// *************************************************************************** *
// *                                                                           *
// * Description:         CANDB File                                           *
// * Generated at:        2025-10-17 10:36                                     *
// * System:              SPA8410_Final2                                       *
// * Variant:             ConfigurationsSPA3d2                                 *
// * Network:             ASDM1CANFD                                           *
// *                                                                           *
// *************************************************************************** *

VERSION "ASDM1CANFD"

NS_ :

BS_ :

BU_ :  ASDM FLRB
VAL_TABLE_ ElevAlignment_States_MFR 2 "MBASC_ELEV_MISALIGNED" 1 "MBASC_ELEV_ALIGNED" 0 "MBASC_ELEV_CALIBRATING" ;

BO_ 289 RADARtoASDM: 2 FLRB
 SG_ EmblmHeatrReqReqDutyCycle : 8|8@1+ (0.5,0) [0|100] "%"  ASDM
 SG_ EmblmHeatrReqReqPWMFrq : 0|8@1+ (0.1,0) [0|25.5] ""  ASDM

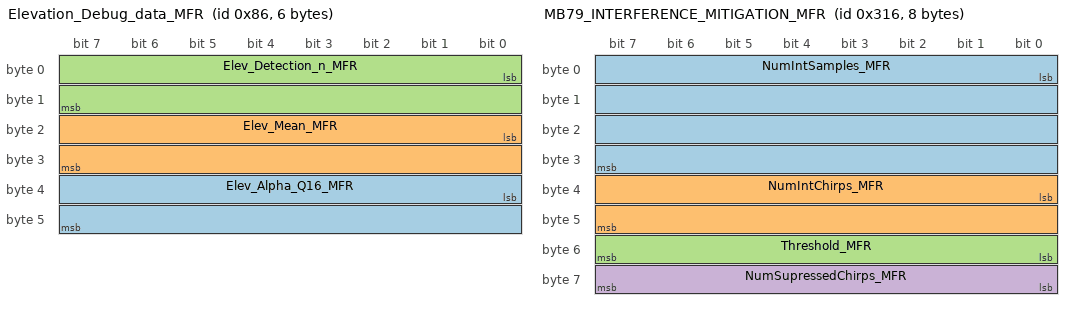
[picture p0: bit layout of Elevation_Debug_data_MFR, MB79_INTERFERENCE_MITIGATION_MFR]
BO_ 134 Elevation_Debug_data_MFR: 6 FLRB
 SG_ Elev_Alpha_Q16_MFR : 32|16@1+ (1,0) [0|65535] ""  ASDM
 SG_ Elev_Mean_MFR : 16|16@1- (1,0) [-32768|32767] ""  ASDM
 SG_ Elev_Detection_n_MFR : 0|16@1+ (1,0) [0|65535] ""  ASDM

BO_ 789 MB79_PARAMETERS_MFR: 24 FLRB
 SG_ Sensor_Serial_Number_MFR : 0|192@1+ (1,0) [0|16777215] ""  ASDM

BO_ 770 MB79_SYSTEM_STATUS_MFR: 8 FLRB
 SG_ Reserved_2bits_MFR : 29|2@1+ (1,0) [0|3] "" Vector__XXX
 SG_ Sensor_Error_Synchronization_Err : 25|1@1+ (1,0) [0|1] "" Vector__XXX
 SG_ Sensor_Error_Supply_Error_MFR : 24|1@1+ (1,0) [0|1] "" Vector__XXX
 SG_ Sensor_Error_Software_Incompatib : 27|1@1+ (1,0) [0|1] "" Vector__XXX
 SG_ Sensor_Error_Security_Breach_MFR : 28|1@1+ (1,0) [0|1] "" Vector__XXX
 SG_ Sensor_Error_Position_Error_MFR : 19|1@1+ (1,0) [0|1] "" Vector__XXX
 SG_ Sensor_Error_Misaligned_MFR : 20|1@1+ (1,0) [0|1] "" Vector__XXX
 SG_ Sensor_Error_Internal_Failure_MF : 17|1@1+ (1,0) [0|1] "" Vector__XXX
 SG_ Sensor_Error_Interference_MFR : 22|1@1+ (1,0) [0|1] "" Vector__XXX
 SG_ Sensor_Error_Initialization_MFR : 23|1@1+ (1,0) [0|1] "" Vector__XXX
 SG_ Sensor_Error_HW_Error_MFR : 26|1@1+ (1,0) [0|1] "" Vector__XXX
 SG_ Sensor_Error_Communication_MFR : 16|1@1+ (1,0) [0|1] "" Vector__XXX
 SG_ Sensor_Error_Calibration_Error_M : 18|1@1+ (1,0) [0|1] "" Vector__XXX
 SG_ Sensor_Error_Blocked_MFR : 21|1@1+ (1,0) [0|1] "" Vector__XXX
 SG_ Heater_Trigger_MFR : 31|1@1+ (1,0) [0|1] "" Vector__XXX
 SG_ Sensor_Operation_Mode_MFR : 12|4@1+ (1,0) [0|15] ""  ASDM
 SG_ Clock_SystemStatus_MFR : 8|4@1+ (1,0) [0|15] ""  ASDM
 SG_ CRC_SystemStatus_MFR : 0|8@1+ (1,0) [0|255] ""  ASDM

BO_ 790 MB79_INTERFERENCE_MITIGATION_MFR: 8 FLRB
 SG_ NumIntSamples_MFR : 0|32@1+ (1,0) [0|16777215] ""  ASDM
 SG_ NumIntChirps_MFR : 32|16@1+ (1,0) [0|255] ""  ASDM
 SG_ Threshold_MFR : 48|8@1+ (1,0) [0|65535] ""  ASDM
 SG_ NumSupressedChirps_MFR : 56|8@1+ (1,0) [0|255] ""  ASDM

BO_ 2047 AsdmToAllFuncAsdm1CanDiagReqFrame : 64 ASDM
 SG_ AsdmToAllFuncAsdm1CanDiagReqNpdu : 7|512@0+ (1,0) [0|0] "" FLRB

BO_ 1889 AsdmToFlrbAsdm1CanDiagReqFrame : 64 ASDM
 SG_ AsdmToFlrbAsdm1CanDiagReqNPdu : 7|512@0+ (1,0) [0|0] "" FLRB

BO_ 1633 FlrbToAsdmAsdm1CanDiagResFrame : 64 FLRB
 SG_ FlrbToAsdmAsdm1CanDiagRespNpdu : 7|512@0+ (1,0) [0|0] "" ASDM

BO_ 288 ASDMtoRADAR: 20 ASDM
 SG_ Vehicle_Type : 123|8@0+ (1,0) [0|255] ""  FLRB
 SG_ EmblmHeatrOutSts : 117|2@0+ (1,0) [0|0] ""  FLRB
 SG_ WshngCycActv : 115|8@0+ (1,0) [0|1] ""  FLRB
 SG_ isUsgModSts : 105|4@0+ (1,0) [0|15] ""  FLRB
 SG_ PwrLvlElecSubtyp : 3|4@0+ (1,0) [0|15] ""  FLRB
 SG_ PwrLvlElecMai : 7|4@0+ (1,0) [0|15] ""  FLRB
 SG_ AmbTRawVal : 47|11@0+ (0.1,-70) [-70|134.7] "degC"  FLRB
 SG_ AmbTRawQly : 52|2@0+ (1,0) [0|3] ""  FLRB
 SG_ BkpOfDstTrvld : 50|21@0+ (1,0) [0|2000000] "km"  FLRB
 SG_ CarTiGlb : 15|32@0+ (0.1,0) [0|429496729.5] "s"  FLRB
 SG_ CarModSts1 : 81|3@0+ (1,0) [0|7] "N/A"  FLRB
 SG_ DrvModReq : 85|4@0+ (1,0) [0|15] ""  FLRB
 SG_ VehBattUSysU : 77|8@0+ (0.1,0) [0|25] "Volt"  FLRB
 SG_ VehBattUSysUQf : 91|2@0+ (1,0) [0|3] ""  FLRB
 SG_ WipgInfoWipgSpdInfo : 94|3@0+ (1,0) [0|7] ""  FLRB
 SG_ WipgInfoWiprActv : 97|8@0+ (1,0) [0|255] ""  FLRB
 SG_ WipgInfoWiprInWipgAr : 89|8@0+ (1,0) [0|255] ""  FLRB

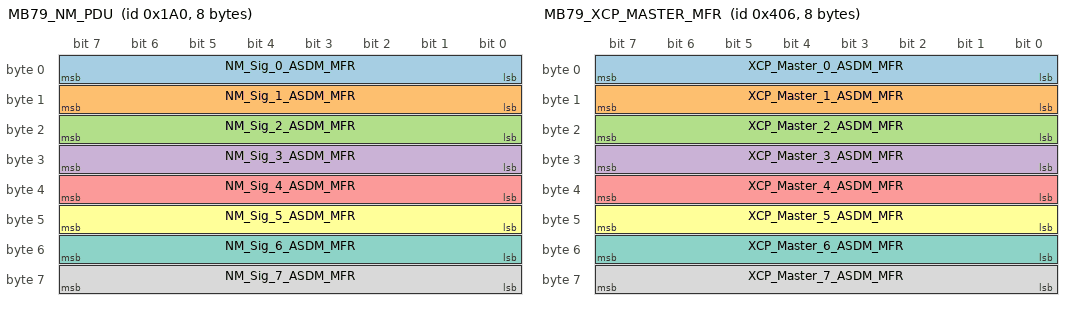
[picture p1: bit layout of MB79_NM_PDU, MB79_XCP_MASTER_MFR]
BO_ 416 MB79_NM_PDU: 8 ASDM
 SG_ NM_Sig_0_ASDM_MFR : 7|8@0+ (1,0) [0|255] "N/A"  FLRB
 SG_ NM_Sig_1_ASDM_MFR : 15|8@0+ (1,0) [0|255] "N/A"  FLRB
 SG_ NM_Sig_2_ASDM_MFR : 23|8@0+ (1,0) [0|255] "N/A"  FLRB
 SG_ NM_Sig_3_ASDM_MFR : 31|8@0+ (1,0) [0|255] "N/A"  FLRB
 SG_ NM_Sig_4_ASDM_MFR : 39|8@0+ (1,0) [0|255] "N/A"  FLRB
 SG_ NM_Sig_5_ASDM_MFR : 47|8@0+ (1,0) [0|255] "N/A"  FLRB
 SG_ NM_Sig_6_ASDM_MFR : 55|8@0+ (1,0) [0|255] "N/A"  FLRB
 SG_ NM_Sig_7_ASDM_MFR : 63|8@0+ (1,0) [0|255] "N/A"  FLRB

BO_ 1281 MB79_ECU_WAKE_UP_MFR: 64 FLRB
 SG_ ECU_Wake_UP_0_MFR : 7|8@0+ (1,0) [0|255] "N/A"  ASDM
 SG_ ECU_Wake_UP_1_MFR : 15|8@0+ (1,0) [0|255] "N/A"  ASDM
 SG_ ECU_Wake_UP_2_MFR : 23|8@0+ (1,0) [0|255] "N/A"  ASDM
 SG_ ECU_Wake_UP_3_MFR : 31|8@0+ (1,0) [0|255] "N/A"  ASDM
 SG_ ECU_Wake_UP_4_MFR : 39|8@0+ (1,0) [0|255] "N/A"  ASDM
 SG_ ECU_Wake_UP_5_MFR : 47|8@0+ (1,0) [0|255] "N/A"  ASDM
 SG_ ECU_Wake_UP_6_MFR : 55|8@0+ (1,0) [0|255] "N/A"  ASDM
 SG_ ECU_Wake_UP_7_MFR : 63|8@0+ (1,0) [0|255] "N/A"  ASDM

BO_ 1030 MB79_XCP_MASTER_MFR: 8 ASDM
 SG_ XCP_Master_0_ASDM_MFR : 7|8@0+ (1,0) [0|255] "N/A"  FLRB
 SG_ XCP_Master_1_ASDM_MFR : 15|8@0+ (1,0) [0|255] "N/A"  FLRB
 SG_ XCP_Master_2_ASDM_MFR : 23|8@0+ (1,0) [0|255] "N/A"  FLRB
 SG_ XCP_Master_3_ASDM_MFR : 31|8@0+ (1,0) [0|255] "N/A"  FLRB
 SG_ XCP_Master_4_ASDM_MFR : 39|8@0+ (1,0) [0|255] "N/A"  FLRB
 SG_ XCP_Master_5_ASDM_MFR : 47|8@0+ (1,0) [0|255] "N/A"  FLRB
 SG_ XCP_Master_6_ASDM_MFR : 55|8@0+ (1,0) [0|255] "N/A"  FLRB
 SG_ XCP_Master_7_ASDM_MFR : 63|8@0+ (1,0) [0|255] "N/A"  FLRB

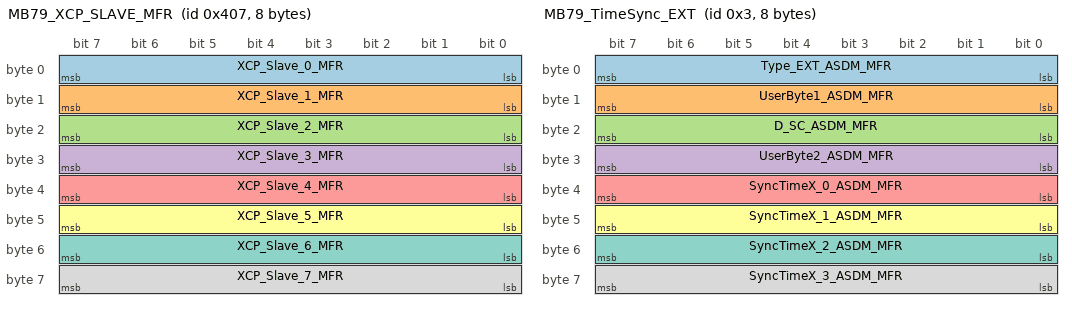
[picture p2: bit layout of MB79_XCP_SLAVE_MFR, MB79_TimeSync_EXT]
BO_ 1031 MB79_XCP_SLAVE_MFR: 8 FLRB
 SG_ XCP_Slave_0_MFR : 7|8@0+ (1,0) [0|255] "N/A"  ASDM
 SG_ XCP_Slave_1_MFR : 15|8@0+ (1,0) [0|255] "N/A"  ASDM
 SG_ XCP_Slave_2_MFR : 23|8@0+ (1,0) [0|255] "N/A"  ASDM
 SG_ XCP_Slave_3_MFR : 31|8@0+ (1,0) [0|255] "N/A"  ASDM
 SG_ XCP_Slave_4_MFR : 39|8@0+ (1,0) [0|255] "N/A"  ASDM
 SG_ XCP_Slave_5_MFR : 47|8@0+ (1,0) [0|255] "N/A"  ASDM
 SG_ XCP_Slave_6_MFR : 55|8@0+ (1,0) [0|255] "N/A"  ASDM
 SG_ XCP_Slave_7_MFR : 63|8@0+ (1,0) [0|255] "N/A"  ASDM

BO_ 3 MB79_TimeSync_EXT: 8 ASDM
 SG_ Type_EXT_ASDM_MFR : 7|8@0+ (1,0) [0|255] "N/A"  FLRB
 SG_ UserByte1_ASDM_MFR : 15|8@0+ (1,0) [0|255] "N/A"  FLRB
 SG_ D_SC_ASDM_MFR : 23|8@0+ (1,0) [0|255] "N/A"  FLRB
 SG_ UserByte2_ASDM_MFR : 31|8@0+ (1,0) [0|255] "N/A"  FLRB
 SG_ SyncTimeX_0_ASDM_MFR : 39|8@0+ (1,0) [0|255] "N/A"  FLRB
 SG_ SyncTimeX_1_ASDM_MFR : 47|8@0+ (1,0) [0|255] "N/A"  FLRB
 SG_ SyncTimeX_2_ASDM_MFR : 55|8@0+ (1,0) [0|255] "N/A"  FLRB
 SG_ SyncTimeX_3_ASDM_MFR : 63|8@0+ (1,0) [0|255] "N/A"  FLRB

BO_ 257 MB79_DETECTION_HEADER_MFR: 64 FLRB
 SG_ ElevAlignment_Status_MFR : 504|2@1+ (1,0) [0|3] "" Vector__XXX
 SG_ CRC_DetectionList_MFR : 0|32@1+ (1,0) [0|4294967295] "N/A"  ASDM
 SG_ CycleNumber_MFR : 32|32@1+ (1,0) [0|4294967295] "cycle"  ASDM
 SG_ TimeStamp_MFR : 64|32@1+ (1,0) [0|4294967295] "us"  ASDM
 SG_ HostVelEst_MFR : 96|16@1- (1,0) [-2000|14000] "cm/s"  ASDM
 SG_ HostYawEst_MFR : 112|16@1- (0.000977,0) [-2|2] "rad/s"  ASDM
 SG_ HostAccelLatEst_MFR : 128|16@1- (1,0) [-2000|2000] "cm/s.s"  ASDM
 SG_ HostAccelLongEst_MFR : 144|16@1- (1,0) [-2000|2000] "cm/s.s"  ASDM
 SG_ Sensor_Elev_Angle_corr_MFR : 160|16@1- (0.1,0) [-180|655.35] "degree"  ASDM
 SG_ Alignment_update_cycle_MFR : 176|8@1+ (1,0) [0|255] "N/A"  ASDM
 SG_ Velocity_Correction_MFR : 184|16@1- (0.0196,0) [-5|5] "%"  ASDM
 SG_ Sensor_Pos_X_MFR : 200|16@1- (0.001,0) [-20|65.535] "m"  ASDM
 SG_ Sensor_Pos_Y_MFR : 216|16@1- (0.001,0) [-20|65.535] "m"  ASDM
 SG_ Orientation_Angle_MFR : 232|16@1- (0.1,0) [-180|180] "degree"  ASDM
 SG_ Calibrated_Angle_Az_MFR : 248|16@1- (0.1,0) [-180|180] "degree"  ASDM
 SG_ Sensor_Pos_Z_MFR : 264|8@1+ (0.01,0) [0|2.55] "m"  ASDM
 SG_ Sensor_FoV_Max_MFR : 272|8@1+ (1,0) [0|255] "degree"  ASDM
 SG_ Sensor_FoV_Min_MFR : 280|8@1+ (1,0) [0|255] "degree"  ASDM
 SG_ BW100KHz1_MFR : 288|16@1+ (100,0) [0|6553500] "N/A"  ASDM
 SG_ UnambiguousVelMeas1_MFR : 304|8@1+ (1,0) [0|255] "N/A"  ASDM
 SG_ Radar_Sensor_type_MFR : 312|8@1+ (1,0) [0|255] "N/A"  ASDM
 SG_ Sensor_Position_ID_MFR : 320|4@1+ (1,0) [0|15] "N/A"  ASDM
 SG_ DetectionListVersion_MFR : 324|4@1+ (1,0) [0|15] "N/A"  ASDM
 SG_ Detection_Header_Version_MFR : 328|4@1+ (1,0) [0|15] "N/A"  ASDM
 SG_ numInfrastructureDetected_MFR : 332|10@1+ (1,0) [0|1023] "detection"  ASDM
 SG_ numNonInfraDetected_MFR : 342|10@1+ (1,0) [0|1023] "detection"  ASDM
 SG_ numFreespaceDetections_MFR : 352|2@1+ (1,0) [0|3] "detection"  ASDM
 SG_ interferenceDetected_MFR : 354|2@1+ (1,0) [0|3] "N/A"  ASDM
 SG_ Blockage_Confidence_MFR : 356|8@1+ (0.5,0) [0|200] "%"  ASDM
 SG_ Blockage_Level_MFR : 364|8@1+ (0.5,0) [0|200] "%"  ASDM
 SG_ Blockage_Status_MFR : 372|3@1+ (1,0) [0|7] "N/A"  ASDM
 SG_ max_instrumented_range_2m_MFR : 375|8@1+ (2,0) [0|510] "m"  ASDM
 SG_ Sensor_Operation_Mode_MFR : 383|4@1+ (1,0) [0|15] "Mode"  ASDM
 SG_ AutoAlignment_Status_MFR : 387|4@1+ (1,0) [0|15] "N/A"  ASDM
 SG_ Testing_Mode_MFR : 391|4@1+ (1,0) [0|15] "N/A"  ASDM
 SG_ NearZoneDetectionsCount_MFR : 395|10@1+ (1,0) [0|512] "detection" Vector__XXX
 SG_ HorizonZoneDetectionsCount_MFR : 405|10@1+ (1,0) [0|512] "detection" Vector__XXX
 SG_ Reserved_1byte_MFR : 415|8@1- (1,0) [0|0] "" Vector__XXX
 SG_ Detection_Data_Mode_MFR : 423|1@1+ (1,0) [0|1] "" Vector__XXX
 SG_ Reserved_3bits_MFR : 424|3@1- (1,0) [0|0] "" Vector__XXX
 SG_ AR_Counter_DetectionList_MFR : 427|32@1+ (1,0) [0|4294967295] "N/A"  ASDM
 SG_ MAC_DetectionList_MFR : 459|24@1+ (1,0) [0|16777215] "N/A"  ASDM
 SG_ Sensor_Topology_MFR : 483|1@1+ (1,0) [0|1] "N/A"  ASDM
 SG_ AASC_Calibration_flag_MFR : 484|1@1+ (1,0) [0|1] "N/A"  ASDM
 SG_ selected_chirp_config_MFR : 485|3@1+ (1,0) [0|7] "N/A"  ASDM
 SG_ FC1MHz1_MFR : 488|16@1+ (10,0) [0|65535] "MHz"  ASDM

BO_ 304 MB79_DETECTIONS_0_MFR: 64 FLRB
 SG_ zipy_serialized_data_0_MFR : 0|32@1- (0.1,0) [-102.4|429496729.5] "degree"  ASDM
 SG_ zipy_serialized_data_1_MFR : 32|32@1- (0.1,0) [-102.4|429496729.5] "degree"  ASDM
 SG_ zipy_serialized_data_2_MFR : 64|32@1- (0.1,0) [-102.4|429496729.5] "degree"  ASDM
 SG_ zipy_serialized_data_3_MFR : 96|32@1- (0.1,0) [-102.4|429496729.5] "degree"  ASDM
 SG_ zipy_serialized_data_4_MFR : 128|32@1- (0.1,0) [-102.4|429496729.5] "degree"  ASDM
 SG_ zipy_serialized_data_5_MFR : 160|32@1- (0.1,0) [-102.4|429496729.5] "degree"  ASDM
 SG_ zipy_serialized_data_6_MFR : 192|32@1- (0.1,0) [-102.4|429496729.5] "degree"  ASDM
 SG_ zipy_serialized_data_7_MFR : 224|32@1- (0.1,0) [-102.4|429496729.5] "degree"  ASDM
 SG_ zipy_serialized_data_8_MFR : 256|32@1- (0.1,0) [-102.4|429496729.5] "degree"  ASDM
 SG_ zipy_serialized_data_9_MFR : 288|32@1- (0.1,0) [-102.4|429496729.5] "degree"  ASDM
 SG_ zipy_serialized_data_10_MFR : 320|32@1- (0.1,0) [-102.4|429496729.5] "degree"  ASDM
 SG_ zipy_serialized_data_11_MFR : 352|32@1- (0.1,0) [-102.4|429496729.5] "degree"  ASDM
 SG_ zipy_serialized_data_12_MFR : 384|32@1- (0.1,0) [-102.4|429496729.5] "degree"  ASDM
 SG_ zipy_serialized_data_13_MFR : 416|32@1- (0.1,0) [-102.4|429496729.5] "degree"  ASDM
 SG_ zipy_serialized_data_14_MFR : 448|32@1- (0.1,0) [-102.4|429496729.5] "degree"  ASDM
 SG_ zipy_serialized_data_15_MFR : 480|32@1- (0.1,0) [-102.4|429496729.5] "degree"  ASDM

BO_ 305 MB79_DETECTIONS_1_MFR: 64 FLRB
 SG_ zipy_serialized_data_16_MFR : 0|32@1- (0.1,0) [-102.4|429496729.5] "degree"  ASDM
 SG_ zipy_serialized_data_17_MFR : 32|32@1- (0.1,0) [-102.4|429496729.5] "degree"  ASDM
 SG_ zipy_serialized_data_18_MFR : 64|32@1- (0.1,0) [-102.4|429496729.5] "degree"  ASDM
 SG_ zipy_serialized_data_19_MFR : 96|32@1- (0.1,0) [-102.4|429496729.5] "degree"  ASDM
 SG_ zipy_serialized_data_20_MFR : 128|32@1- (0.1,0) [-102.4|429496729.5] "degree"  ASDM
 SG_ zipy_serialized_data_21_MFR : 160|32@1- (0.1,0) [-102.4|429496729.5] "degree"  ASDM
 SG_ zipy_serialized_data_22_MFR : 192|32@1- (0.1,0) [-102.4|429496729.5] "degree"  ASDM
 SG_ zipy_serialized_data_23_MFR : 224|32@1- (0.1,0) [-102.4|429496729.5] "degree"  ASDM
 SG_ zipy_serialized_data_24_MFR : 256|32@1- (0.1,0) [-102.4|429496729.5] "degree"  ASDM
 SG_ zipy_serialized_data_25_MFR : 288|32@1- (0.1,0) [-102.4|429496729.5] "degree"  ASDM
 SG_ zipy_serialized_data_26_MFR : 320|32@1- (0.1,0) [-102.4|429496729.5] "degree"  ASDM
 SG_ zipy_serialized_data_27_MFR : 352|32@1- (0.1,0) [-102.4|429496729.5] "degree"  ASDM
 SG_ zipy_serialized_data_28_MFR : 384|32@1- (0.1,0) [-102.4|429496729.5] "degree"  ASDM
 SG_ zipy_serialized_data_29_MFR : 416|32@1- (0.1,0) [-102.4|429496729.5] "degree"  ASDM
 SG_ zipy_serialized_data_30_MFR : 448|32@1- (0.1,0) [-102.4|429496729.5] "degree"  ASDM
 SG_ zipy_serialized_data_31_MFR : 480|32@1- (0.1,0) [-102.4|429496729.5] "degree"  ASDM

BO_ 306 MB79_DETECTIONS_2_MFR: 64 FLRB
 SG_ zipy_serialized_data_32_MFR : 0|32@1- (0.1,0) [-102.4|429496729.5] "degree"  ASDM
 SG_ zipy_serialized_data_33_MFR : 32|32@1- (0.1,0) [-102.4|429496729.5] "degree"  ASDM
 SG_ zipy_serialized_data_34_MFR : 64|32@1- (0.1,0) [-102.4|429496729.5] "degree"  ASDM
 SG_ zipy_serialized_data_35_MFR : 96|32@1- (0.1,0) [-102.4|429496729.5] "degree"  ASDM
 SG_ zipy_serialized_data_36_MFR : 128|32@1- (0.1,0) [-102.4|429496729.5] "degree"  ASDM
 SG_ zipy_serialized_data_37_MFR : 160|32@1- (0.1,0) [-102.4|429496729.5] "degree"  ASDM
 SG_ zipy_serialized_data_38_MFR : 192|32@1- (0.1,0) [-102.4|429496729.5] "degree"  ASDM
 SG_ zipy_serialized_data_39_MFR : 224|32@1- (0.1,0) [-102.4|429496729.5] "degree"  ASDM
 SG_ zipy_serialized_data_40_MFR : 256|32@1- (0.1,0) [-102.4|429496729.5] "degree"  ASDM
 SG_ zipy_serialized_data_41_MFR : 288|32@1- (0.1,0) [-102.4|429496729.5] "degree"  ASDM
 SG_ zipy_serialized_data_42_MFR : 320|32@1- (0.1,0) [-102.4|429496729.5] "degree"  ASDM
 SG_ zipy_serialized_data_43_MFR : 352|32@1- (0.1,0) [-102.4|429496729.5] "degree"  ASDM
 SG_ zipy_serialized_data_44_MFR : 384|32@1- (0.1,0) [-102.4|429496729.5] "degree"  ASDM
 SG_ zipy_serialized_data_45_MFR : 416|32@1- (0.1,0) [-102.4|429496729.5] "degree"  ASDM
 SG_ zipy_serialized_data_46_MFR : 448|32@1- (0.1,0) [-102.4|429496729.5] "degree"  ASDM
 SG_ zipy_serialized_data_47_MFR : 480|32@1- (0.1,0) [-102.4|429496729.5] "degree"  ASDM

BO_ 307 MB79_DETECTIONS_3_MFR: 64 FLRB
 SG_ zipy_serialized_data_48_MFR : 0|32@1- (0.1,0) [-102.4|429496729.5] "degree"  ASDM
 SG_ zipy_serialized_data_49_MFR : 32|32@1- (0.1,0) [-102.4|429496729.5] "degree"  ASDM
 SG_ zipy_serialized_data_50_MFR : 64|32@1- (0.1,0) [-102.4|429496729.5] "degree"  ASDM
 SG_ zipy_serialized_data_51_MFR : 96|32@1- (0.1,0) [-102.4|429496729.5] "degree"  ASDM
 SG_ zipy_serialized_data_52_MFR : 128|32@1- (0.1,0) [-102.4|429496729.5] "degree"  ASDM
 SG_ zipy_serialized_data_53_MFR : 160|32@1- (0.1,0) [-102.4|429496729.5] "degree"  ASDM
 SG_ zipy_serialized_data_54_MFR : 192|32@1- (0.1,0) [-102.4|429496729.5] "degree"  ASDM
 SG_ zipy_serialized_data_55_MFR : 224|32@1- (0.1,0) [-102.4|429496729.5] "degree"  ASDM
 SG_ zipy_serialized_data_56_MFR : 256|32@1- (0.1,0) [-102.4|429496729.5] "degree"  ASDM
 SG_ zipy_serialized_data_57_MFR : 288|32@1- (0.1,0) [-102.4|429496729.5] "degree"  ASDM
 SG_ zipy_serialized_data_58_MFR : 320|32@1- (0.1,0) [-102.4|429496729.5] "degree"  ASDM
 SG_ zipy_serialized_data_59_MFR : 352|32@1- (0.1,0) [-102.4|429496729.5] "degree"  ASDM
 SG_ zipy_serialized_data_60_MFR : 384|32@1- (0.1,0) [-102.4|429496729.5] "degree"  ASDM
 SG_ zipy_serialized_data_61_MFR : 416|32@1- (0.1,0) [-102.4|429496729.5] "degree"  ASDM
 SG_ zipy_serialized_data_62_MFR : 448|32@1- (0.1,0) [-102.4|429496729.5] "degree"  ASDM
 SG_ zipy_serialized_data_63_MFR : 480|32@1- (0.1,0) [-102.4|429496729.5] "degree"  ASDM

BO_ 308 MB79_DETECTIONS_4_MFR: 64 FLRB
 SG_ zipy_serialized_data_64_MFR : 0|32@1- (0.1,0) [-102.4|429496729.5] "degree"  ASDM
 SG_ zipy_serialized_data_65_MFR : 32|32@1- (0.1,0) [-102.4|429496729.5] "degree"  ASDM
 SG_ zipy_serialized_data_66_MFR : 64|32@1- (0.1,0) [-102.4|429496729.5] "degree"  ASDM
 SG_ zipy_serialized_data_67_MFR : 96|32@1- (0.1,0) [-102.4|429496729.5] "degree"  ASDM
 SG_ zipy_serialized_data_68_MFR : 128|32@1- (0.1,0) [-102.4|429496729.5] "degree"  ASDM
 SG_ zipy_serialized_data_69_MFR : 160|32@1- (0.1,0) [-102.4|429496729.5] "degree"  ASDM
 SG_ zipy_serialized_data_70_MFR : 192|32@1- (0.1,0) [-102.4|429496729.5] "degree"  ASDM
 SG_ zipy_serialized_data_71_MFR : 224|32@1- (0.1,0) [-102.4|429496729.5] "degree"  ASDM
 SG_ zipy_serialized_data_72_MFR : 256|32@1- (0.1,0) [-102.4|429496729.5] "degree"  ASDM
 SG_ zipy_serialized_data_73_MFR : 288|32@1- (0.1,0) [-102.4|429496729.5] "degree"  ASDM
 SG_ zipy_serialized_data_74_MFR : 320|32@1- (0.1,0) [-102.4|429496729.5] "degree"  ASDM
 SG_ zipy_serialized_data_75_MFR : 352|32@1- (0.1,0) [-102.4|429496729.5] "degree"  ASDM
 SG_ zipy_serialized_data_76_MFR : 384|32@1- (0.1,0) [-102.4|429496729.5] "degree"  ASDM
 SG_ zipy_serialized_data_77_MFR : 416|32@1- (0.1,0) [-102.4|429496729.5] "degree"  ASDM
 SG_ zipy_serialized_data_78_MFR : 448|32@1- (0.1,0) [-102.4|429496729.5] "degree"  ASDM
 SG_ zipy_serialized_data_79_MFR : 480|32@1- (0.1,0) [-102.4|429496729.5] "degree"  ASDM

BO_ 309 MB79_DETECTIONS_5_MFR: 64 FLRB
 SG_ zipy_serialized_data_80_MFR : 0|32@1- (0.1,0) [-102.4|429496729.5] "degree"  ASDM
 SG_ zipy_serialized_data_81_MFR : 32|32@1- (0.1,0) [-102.4|429496729.5] "degree"  ASDM
 SG_ zipy_serialized_data_82_MFR : 64|32@1- (0.1,0) [-102.4|429496729.5] "degree"  ASDM
 SG_ zipy_serialized_data_83_MFR : 96|32@1- (0.1,0) [-102.4|429496729.5] "degree"  ASDM
 SG_ zipy_serialized_data_84_MFR : 128|32@1- (0.1,0) [-102.4|429496729.5] "degree"  ASDM
 SG_ zipy_serialized_data_85_MFR : 160|32@1- (0.1,0) [-102.4|429496729.5] "degree"  ASDM
 SG_ zipy_serialized_data_86_MFR : 192|32@1- (0.1,0) [-102.4|429496729.5] "degree"  ASDM
 SG_ zipy_serialized_data_87_MFR : 224|32@1- (0.1,0) [-102.4|429496729.5] "degree"  ASDM
 SG_ zipy_serialized_data_88_MFR : 256|32@1- (0.1,0) [-102.4|429496729.5] "degree"  ASDM
 SG_ zipy_serialized_data_89_MFR : 288|32@1- (0.1,0) [-102.4|429496729.5] "degree"  ASDM
 SG_ zipy_serialized_data_90_MFR : 320|32@1- (0.1,0) [-102.4|429496729.5] "degree"  ASDM
 SG_ zipy_serialized_data_91_MFR : 352|32@1- (0.1,0) [-102.4|429496729.5] "degree"  ASDM
 SG_ zipy_serialized_data_92_MFR : 384|32@1- (0.1,0) [-102.4|429496729.5] "degree"  ASDM
 SG_ zipy_serialized_data_93_MFR : 416|32@1- (0.1,0) [-102.4|429496729.5] "degree"  ASDM
 SG_ zipy_serialized_data_94_MFR : 448|32@1- (0.1,0) [-102.4|429496729.5] "degree"  ASDM
 SG_ zipy_serialized_data_95_MFR : 480|32@1- (0.1,0) [-102.4|429496729.5] "degree"  ASDM

BO_ 310 MB79_DETECTIONS_6_MFR: 64 FLRB
 SG_ zipy_serialized_data_96_MFR : 0|32@1- (0.1,0) [-102.4|429496729.5] "degree"  ASDM
 SG_ zipy_serialized_data_97_MFR : 32|32@1- (0.1,0) [-102.4|429496729.5] "degree"  ASDM
 SG_ zipy_serialized_data_98_MFR : 64|32@1- (0.1,0) [-102.4|429496729.5] "degree"  ASDM
 SG_ zipy_serialized_data_99_MFR : 96|32@1- (0.1,0) [-102.4|429496729.5] "degree"  ASDM
 SG_ zipy_serialized_data_100_MFR : 128|32@1- (0.1,0) [-102.4|429496729.5] "degree"  ASDM
 SG_ zipy_serialized_data_101_MFR : 160|32@1- (0.1,0) [-102.4|429496729.5] "degree"  ASDM
 SG_ zipy_serialized_data_102_MFR : 192|32@1- (0.1,0) [-102.4|429496729.5] "degree"  ASDM
 SG_ zipy_serialized_data_103_MFR : 224|32@1- (0.1,0) [-102.4|429496729.5] "degree"  ASDM
 SG_ zipy_serialized_data_104_MFR : 256|32@1- (0.1,0) [-102.4|429496729.5] "degree"  ASDM
 SG_ zipy_serialized_data_105_MFR : 288|32@1- (0.1,0) [-102.4|429496729.5] "degree"  ASDM
 SG_ zipy_serialized_data_106_MFR : 320|32@1- (0.1,0) [-102.4|429496729.5] "degree"  ASDM
 SG_ zipy_serialized_data_107_MFR : 352|32@1- (0.1,0) [-102.4|429496729.5] "degree"  ASDM
 SG_ zipy_serialized_data_108_MFR : 384|32@1- (0.1,0) [-102.4|429496729.5] "degree"  ASDM
 SG_ zipy_serialized_data_109_MFR : 416|32@1- (0.1,0) [-102.4|429496729.5] "degree"  ASDM
 SG_ zipy_serialized_data_110_MFR : 448|32@1- (0.1,0) [-102.4|429496729.5] "degree"  ASDM
 SG_ zipy_serialized_data_111_MFR : 480|32@1- (0.1,0) [-102.4|429496729.5] "degree"  ASDM

BO_ 311 MB79_DETECTIONS_7_MFR: 64 FLRB
 SG_ zipy_serialized_data_112_MFR : 0|32@1- (0.1,0) [-102.4|429496729.5] "degree"  ASDM
 SG_ zipy_serialized_data_113_MFR : 32|32@1- (0.1,0) [-102.4|429496729.5] "degree"  ASDM
 SG_ zipy_serialized_data_114_MFR : 64|32@1- (0.1,0) [-102.4|429496729.5] "degree"  ASDM
 SG_ zipy_serialized_data_115_MFR : 96|32@1- (0.1,0) [-102.4|429496729.5] "degree"  ASDM
 SG_ zipy_serialized_data_116_MFR : 128|32@1- (0.1,0) [-102.4|429496729.5] "degree"  ASDM
 SG_ zipy_serialized_data_117_MFR : 160|32@1- (0.1,0) [-102.4|429496729.5] "degree"  ASDM
 SG_ zipy_serialized_data_118_MFR : 192|32@1- (0.1,0) [-102.4|429496729.5] "degree"  ASDM
 SG_ zipy_serialized_data_119_MFR : 224|32@1- (0.1,0) [-102.4|429496729.5] "degree"  ASDM
 SG_ zipy_serialized_data_120_MFR : 256|32@1- (0.1,0) [-102.4|429496729.5] "degree"  ASDM
 SG_ zipy_serialized_data_121_MFR : 288|32@1- (0.1,0) [-102.4|429496729.5] "degree"  ASDM
 SG_ zipy_serialized_data_122_MFR : 320|32@1- (0.1,0) [-102.4|429496729.5] "degree"  ASDM
 SG_ zipy_serialized_data_123_MFR : 352|32@1- (0.1,0) [-102.4|429496729.5] "degree"  ASDM
 SG_ zipy_serialized_data_124_MFR : 384|32@1- (0.1,0) [-102.4|429496729.5] "degree"  ASDM
 SG_ zipy_serialized_data_125_MFR : 416|32@1- (0.1,0) [-102.4|429496729.5] "degree"  ASDM
 SG_ zipy_serialized_data_126_MFR : 448|32@1- (0.1,0) [-102.4|429496729.5] "degree"  ASDM
 SG_ zipy_serialized_data_127_MFR : 480|32@1- (0.1,0) [-102.4|429496729.5] "degree"  ASDM

BO_ 312 MB79_DETECTIONS_8_MFR: 64 FLRB
 SG_ zipy_serialized_data_128_MFR : 0|32@1- (0.1,0) [-102.4|429496729.5] "degree"  ASDM
 SG_ zipy_serialized_data_129_MFR : 32|32@1- (0.1,0) [-102.4|429496729.5] "degree"  ASDM
 SG_ zipy_serialized_data_130_MFR : 64|32@1- (0.1,0) [-102.4|429496729.5] "degree"  ASDM
 SG_ zipy_serialized_data_131_MFR : 96|32@1- (0.1,0) [-102.4|429496729.5] "degree"  ASDM
 SG_ zipy_serialized_data_132_MFR : 128|32@1- (0.1,0) [-102.4|429496729.5] "degree"  ASDM
 SG_ zipy_serialized_data_133_MFR : 160|32@1- (0.1,0) [-102.4|429496729.5] "degree"  ASDM
 SG_ zipy_serialized_data_134_MFR : 192|32@1- (0.1,0) [-102.4|429496729.5] "degree"  ASDM
 SG_ zipy_serialized_data_135_MFR : 224|32@1- (0.1,0) [-102.4|429496729.5] "degree"  ASDM
 SG_ zipy_serialized_data_136_MFR : 256|32@1- (0.1,0) [-102.4|429496729.5] "degree"  ASDM
 SG_ zipy_serialized_data_137_MFR : 288|32@1- (0.1,0) [-102.4|429496729.5] "degree"  ASDM
 SG_ zipy_serialized_data_138_MFR : 320|32@1- (0.1,0) [-102.4|429496729.5] "degree"  ASDM
 SG_ zipy_serialized_data_139_MFR : 352|32@1- (0.1,0) [-102.4|429496729.5] "degree"  ASDM
 SG_ zipy_serialized_data_140_MFR : 384|32@1- (0.1,0) [-102.4|429496729.5] "degree"  ASDM
 SG_ zipy_serialized_data_141_MFR : 416|32@1- (0.1,0) [-102.4|429496729.5] "degree"  ASDM
 SG_ zipy_serialized_data_142_MFR : 448|32@1- (0.1,0) [-102.4|429496729.5] "degree"  ASDM
 SG_ zipy_serialized_data_143_MFR : 480|32@1- (0.1,0) [-102.4|429496729.5] "degree"  ASDM

BO_ 313 MB79_DETECTIONS_9_MFR: 64 FLRB
 SG_ zipy_serialized_data_144_MFR : 0|32@1- (0.1,0) [-102.4|429496729.5] "degree"  ASDM
 SG_ zipy_serialized_data_145_MFR : 32|32@1- (0.1,0) [-102.4|429496729.5] "degree"  ASDM
 SG_ zipy_serialized_data_146_MFR : 64|32@1- (0.1,0) [-102.4|429496729.5] "degree"  ASDM
 SG_ zipy_serialized_data_147_MFR : 96|32@1- (0.1,0) [-102.4|429496729.5] "degree"  ASDM
 SG_ zipy_serialized_data_148_MFR : 128|32@1- (0.1,0) [-102.4|429496729.5] "degree"  ASDM
 SG_ zipy_serialized_data_149_MFR : 160|32@1- (0.1,0) [-102.4|429496729.5] "degree"  ASDM
 SG_ zipy_serialized_data_150_MFR : 192|32@1- (0.1,0) [-102.4|429496729.5] "degree"  ASDM
 SG_ zipy_serialized_data_151_MFR : 224|32@1- (0.1,0) [-102.4|429496729.5] "degree"  ASDM
 SG_ zipy_serialized_data_152_MFR : 256|32@1- (0.1,0) [-102.4|429496729.5] "degree"  ASDM
 SG_ zipy_serialized_data_153_MFR : 288|32@1- (0.1,0) [-102.4|429496729.5] "degree"  ASDM
 SG_ zipy_serialized_data_154_MFR : 320|32@1- (0.1,0) [-102.4|429496729.5] "degree"  ASDM
 SG_ zipy_serialized_data_155_MFR : 352|32@1- (0.1,0) [-102.4|429496729.5] "degree"  ASDM
 SG_ zipy_serialized_data_156_MFR : 384|32@1- (0.1,0) [-102.4|429496729.5] "degree"  ASDM
 SG_ zipy_serialized_data_157_MFR : 416|32@1- (0.1,0) [-102.4|429496729.5] "degree"  ASDM
 SG_ zipy_serialized_data_158_MFR : 448|32@1- (0.1,0) [-102.4|429496729.5] "degree"  ASDM
 SG_ zipy_serialized_data_159_MFR : 480|32@1- (0.1,0) [-102.4|429496729.5] "degree"  ASDM

BO_ 314 MB79_DETECTIONS_10_MFR: 64 FLRB
 SG_ zipy_serialized_data_160_MFR : 0|32@1- (0.1,0) [-102.4|429496729.5] "degree"  ASDM
 SG_ zipy_serialized_data_161_MFR : 32|32@1- (0.1,0) [-102.4|429496729.5] "degree"  ASDM
 SG_ zipy_serialized_data_162_MFR : 64|32@1- (0.1,0) [-102.4|429496729.5] "degree"  ASDM
 SG_ zipy_serialized_data_163_MFR : 96|32@1- (0.1,0) [-102.4|429496729.5] "degree"  ASDM
 SG_ zipy_serialized_data_164_MFR : 128|32@1- (0.1,0) [-102.4|429496729.5] "degree"  ASDM
 SG_ zipy_serialized_data_165_MFR : 160|32@1- (0.1,0) [-102.4|429496729.5] "degree"  ASDM
 SG_ zipy_serialized_data_166_MFR : 192|32@1- (0.1,0) [-102.4|429496729.5] "degree"  ASDM
 SG_ zipy_serialized_data_167_MFR : 224|32@1- (0.1,0) [-102.4|429496729.5] "degree"  ASDM
 SG_ zipy_serialized_data_168_MFR : 256|32@1- (0.1,0) [-102.4|429496729.5] "degree"  ASDM
 SG_ zipy_serialized_data_169_MFR : 288|32@1- (0.1,0) [-102.4|429496729.5] "degree"  ASDM
 SG_ zipy_serialized_data_170_MFR : 320|32@1- (0.1,0) [-102.4|429496729.5] "degree"  ASDM
 SG_ zipy_serialized_data_171_MFR : 352|32@1- (0.1,0) [-102.4|429496729.5] "degree"  ASDM
 SG_ zipy_serialized_data_172_MFR : 384|32@1- (0.1,0) [-102.4|429496729.5] "degree"  ASDM
 SG_ zipy_serialized_data_173_MFR : 416|32@1- (0.1,0) [-102.4|429496729.5] "degree"  ASDM
 SG_ zipy_serialized_data_174_MFR : 448|32@1- (0.1,0) [-102.4|429496729.5] "degree"  ASDM
 SG_ zipy_serialized_data_175_MFR : 480|32@1- (0.1,0) [-102.4|429496729.5] "degree"  ASDM

BO_ 315 MB79_DETECTIONS_11_MFR: 64 FLRB
 SG_ zipy_serialized_data_176_MFR : 0|32@1- (0.1,0) [-102.4|429496729.5] "degree"  ASDM
 SG_ zipy_serialized_data_177_MFR : 32|32@1- (0.1,0) [-102.4|429496729.5] "degree"  ASDM
 SG_ zipy_serialized_data_178_MFR : 64|32@1- (0.1,0) [-102.4|429496729.5] "degree"  ASDM
 SG_ zipy_serialized_data_179_MFR : 96|32@1- (0.1,0) [-102.4|429496729.5] "degree"  ASDM
 SG_ zipy_serialized_data_180_MFR : 128|32@1- (0.1,0) [-102.4|429496729.5] "degree"  ASDM
 SG_ zipy_serialized_data_181_MFR : 160|32@1- (0.1,0) [-102.4|429496729.5] "degree"  ASDM
 SG_ zipy_serialized_data_182_MFR : 192|32@1- (0.1,0) [-102.4|429496729.5] "degree"  ASDM
 SG_ zipy_serialized_data_183_MFR : 224|32@1- (0.1,0) [-102.4|429496729.5] "degree"  ASDM
 SG_ zipy_serialized_data_184_MFR : 256|32@1- (0.1,0) [-102.4|429496729.5] "degree"  ASDM
 SG_ zipy_serialized_data_185_MFR : 288|32@1- (0.1,0) [-102.4|429496729.5] "degree"  ASDM
 SG_ zipy_serialized_data_186_MFR : 320|32@1- (0.1,0) [-102.4|429496729.5] "degree"  ASDM
 SG_ zipy_serialized_data_187_MFR : 352|32@1- (0.1,0) [-102.4|429496729.5] "degree"  ASDM
 SG_ zipy_serialized_data_188_MFR : 384|32@1- (0.1,0) [-102.4|429496729.5] "degree"  ASDM
 SG_ zipy_serialized_data_189_MFR : 416|32@1- (0.1,0) [-102.4|429496729.5] "degree"  ASDM
 SG_ zipy_serialized_data_190_MFR : 448|32@1- (0.1,0) [-102.4|429496729.5] "degree"  ASDM
 SG_ zipy_serialized_data_191_MFR : 480|32@1- (0.1,0) [-102.4|429496729.5] "degree"  ASDM

BO_ 316 MB79_DETECTIONS_12_MFR: 64 FLRB
 SG_ zipy_serialized_data_192_MFR : 0|32@1- (0.1,0) [-102.4|429496729.5] "degree"  ASDM
 SG_ zipy_serialized_data_193_MFR : 32|32@1- (0.1,0) [-102.4|429496729.5] "degree"  ASDM
 SG_ zipy_serialized_data_194_MFR : 64|32@1- (0.1,0) [-102.4|429496729.5] "degree"  ASDM
 SG_ zipy_serialized_data_195_MFR : 96|32@1- (0.1,0) [-102.4|429496729.5] "degree"  ASDM
 SG_ zipy_serialized_data_196_MFR : 128|32@1- (0.1,0) [-102.4|429496729.5] "degree"  ASDM
 SG_ zipy_serialized_data_197_MFR : 160|32@1- (0.1,0) [-102.4|429496729.5] "degree"  ASDM
 SG_ zipy_serialized_data_198_MFR : 192|32@1- (0.1,0) [-102.4|429496729.5] "degree"  ASDM
 SG_ zipy_serialized_data_199_MFR : 224|32@1- (0.1,0) [-102.4|429496729.5] "degree"  ASDM
 SG_ zipy_serialized_data_200_MFR : 256|32@1- (0.1,0) [-102.4|429496729.5] "degree"  ASDM
 SG_ zipy_serialized_data_201_MFR : 288|32@1- (0.1,0) [-102.4|429496729.5] "degree"  ASDM
 SG_ zipy_serialized_data_202_MFR : 320|32@1- (0.1,0) [-102.4|429496729.5] "degree"  ASDM
 SG_ zipy_serialized_data_203_MFR : 352|32@1- (0.1,0) [-102.4|429496729.5] "degree"  ASDM
 SG_ zipy_serialized_data_204_MFR : 384|32@1- (0.1,0) [-102.4|429496729.5] "degree"  ASDM
 SG_ zipy_serialized_data_205_MFR : 416|32@1- (0.1,0) [-102.4|429496729.5] "degree"  ASDM
 SG_ zipy_serialized_data_206_MFR : 448|32@1- (0.1,0) [-102.4|429496729.5] "degree"  ASDM
 SG_ zipy_serialized_data_207_MFR : 480|32@1- (0.1,0) [-102.4|429496729.5] "degree"  ASDM

BO_ 317 MB79_DETECTIONS_13_MFR: 64 FLRB
 SG_ zipy_serialized_data_208_MFR : 0|32@1- (0.1,0) [-102.4|429496729.5] "degree"  ASDM
 SG_ zipy_serialized_data_209_MFR : 32|32@1- (0.1,0) [-102.4|429496729.5] "degree"  ASDM
 SG_ zipy_serialized_data_210_MFR : 64|32@1- (0.1,0) [-102.4|429496729.5] "degree"  ASDM
 SG_ zipy_serialized_data_211_MFR : 96|32@1- (0.1,0) [-102.4|429496729.5] "degree"  ASDM
 SG_ zipy_serialized_data_212_MFR : 128|32@1- (0.1,0) [-102.4|429496729.5] "degree"  ASDM
 SG_ zipy_serialized_data_213_MFR : 160|32@1- (0.1,0) [-102.4|429496729.5] "degree"  ASDM
 SG_ zipy_serialized_data_214_MFR : 192|32@1- (0.1,0) [-102.4|429496729.5] "degree"  ASDM
 SG_ zipy_serialized_data_215_MFR : 224|32@1- (0.1,0) [-102.4|429496729.5] "degree"  ASDM
 SG_ zipy_serialized_data_216_MFR : 256|32@1- (0.1,0) [-102.4|429496729.5] "degree"  ASDM
 SG_ zipy_serialized_data_217_MFR : 288|32@1- (0.1,0) [-102.4|429496729.5] "degree"  ASDM
 SG_ zipy_serialized_data_218_MFR : 320|32@1- (0.1,0) [-102.4|429496729.5] "degree"  ASDM
 SG_ zipy_serialized_data_219_MFR : 352|32@1- (0.1,0) [-102.4|429496729.5] "degree"  ASDM
 SG_ zipy_serialized_data_220_MFR : 384|32@1- (0.1,0) [-102.4|429496729.5] "degree"  ASDM
 SG_ zipy_serialized_data_221_MFR : 416|32@1- (0.1,0) [-102.4|429496729.5] "degree"  ASDM
 SG_ zipy_serialized_data_222_MFR : 448|32@1- (0.1,0) [-102.4|429496729.5] "degree"  ASDM
 SG_ zipy_serialized_data_223_MFR : 480|32@1- (0.1,0) [-102.4|429496729.5] "degree"  ASDM

BO_ 318 MB79_DETECTIONS_14_MFR: 64 FLRB
 SG_ zipy_serialized_data_224_MFR : 0|32@1- (0.1,0) [-102.4|429496729.5] "degree"  ASDM
 SG_ zipy_serialized_data_225_MFR : 32|32@1- (0.1,0) [-102.4|429496729.5] "degree"  ASDM
 SG_ zipy_serialized_data_226_MFR : 64|32@1- (0.1,0) [-102.4|429496729.5] "degree"  ASDM
 SG_ zipy_serialized_data_227_MFR : 96|32@1- (0.1,0) [-102.4|429496729.5] "degree"  ASDM
 SG_ zipy_serialized_data_228_MFR : 128|32@1- (0.1,0) [-102.4|429496729.5] "degree"  ASDM
 SG_ zipy_serialized_data_229_MFR : 160|32@1- (0.1,0) [-102.4|429496729.5] "degree"  ASDM
 SG_ zipy_serialized_data_230_MFR : 192|32@1- (0.1,0) [-102.4|429496729.5] "degree"  ASDM
 SG_ zipy_serialized_data_231_MFR : 224|32@1- (0.1,0) [-102.4|429496729.5] "degree"  ASDM
 SG_ zipy_serialized_data_232_MFR : 256|32@1- (0.1,0) [-102.4|429496729.5] "degree"  ASDM
 SG_ zipy_serialized_data_233_MFR : 288|32@1- (0.1,0) [-102.4|429496729.5] "degree"  ASDM
 SG_ zipy_serialized_data_234_MFR : 320|32@1- (0.1,0) [-102.4|429496729.5] "degree"  ASDM
 SG_ zipy_serialized_data_235_MFR : 352|32@1- (0.1,0) [-102.4|429496729.5] "degree"  ASDM
 SG_ zipy_serialized_data_236_MFR : 384|32@1- (0.1,0) [-102.4|429496729.5] "degree"  ASDM
 SG_ zipy_serialized_data_237_MFR : 416|32@1- (0.1,0) [-102.4|429496729.5] "degree"  ASDM
 SG_ zipy_serialized_data_238_MFR : 448|32@1- (0.1,0) [-102.4|429496729.5] "degree"  ASDM
 SG_ zipy_serialized_data_239_MFR : 480|32@1- (0.1,0) [-102.4|429496729.5] "degree"  ASDM

BO_ 319 MB79_DETECTIONS_15_MFR: 64 FLRB
 SG_ zipy_serialized_data_240_MFR : 0|32@1- (0.1,0) [-102.4|429496729.5] "degree"  ASDM
 SG_ zipy_serialized_data_241_MFR : 32|32@1- (0.1,0) [-102.4|429496729.5] "degree"  ASDM
 SG_ zipy_serialized_data_242_MFR : 64|32@1- (0.1,0) [-102.4|429496729.5] "degree"  ASDM
 SG_ zipy_serialized_data_243_MFR : 96|32@1- (0.1,0) [-102.4|429496729.5] "degree"  ASDM
 SG_ zipy_serialized_data_244_MFR : 128|32@1- (0.1,0) [-102.4|429496729.5] "degree"  ASDM
 SG_ zipy_serialized_data_245_MFR : 160|32@1- (0.1,0) [-102.4|429496729.5] "degree"  ASDM
 SG_ zipy_serialized_data_246_MFR : 192|32@1- (0.1,0) [-102.4|429496729.5] "degree"  ASDM
 SG_ zipy_serialized_data_247_MFR : 224|32@1- (0.1,0) [-102.4|429496729.5] "degree"  ASDM
 SG_ zipy_serialized_data_248_MFR : 256|32@1- (0.1,0) [-102.4|429496729.5] "degree"  ASDM
 SG_ zipy_serialized_data_249_MFR : 288|32@1- (0.1,0) [-102.4|429496729.5] "degree"  ASDM
 SG_ zipy_serialized_data_250_MFR : 320|32@1- (0.1,0) [-102.4|429496729.5] "degree"  ASDM
 SG_ zipy_serialized_data_251_MFR : 352|32@1- (0.1,0) [-102.4|429496729.5] "degree"  ASDM
 SG_ zipy_serialized_data_252_MFR : 384|32@1- (0.1,0) [-102.4|429496729.5] "degree"  ASDM
 SG_ zipy_serialized_data_253_MFR : 416|32@1- (0.1,0) [-102.4|429496729.5] "degree"  ASDM
 SG_ zipy_serialized_data_254_MFR : 448|32@1- (0.1,0) [-102.4|429496729.5] "degree"  ASDM
 SG_ zipy_serialized_data_255_MFR : 480|32@1- (0.1,0) [-102.4|429496729.5] "degree"  ASDM

BO_ 320 MB79_DETECTIONS_16_MFR: 64 FLRB
 SG_ zipy_serialized_data_256_MFR : 0|32@1- (0.1,0) [-102.4|429496729.5] "degree"  ASDM
 SG_ zipy_serialized_data_257_MFR : 32|32@1- (0.1,0) [-102.4|429496729.5] "degree"  ASDM
 SG_ zipy_serialized_data_258_MFR : 64|32@1- (0.1,0) [-102.4|429496729.5] "degree"  ASDM
 SG_ zipy_serialized_data_259_MFR : 96|32@1- (0.1,0) [-102.4|429496729.5] "degree"  ASDM
 SG_ zipy_serialized_data_260_MFR : 128|32@1- (0.1,0) [-102.4|429496729.5] "degree"  ASDM
 SG_ zipy_serialized_data_261_MFR : 160|32@1- (0.1,0) [-102.4|429496729.5] "degree"  ASDM
 SG_ zipy_serialized_data_262_MFR : 192|32@1- (0.1,0) [-102.4|429496729.5] "degree"  ASDM
 SG_ zipy_serialized_data_263_MFR : 224|32@1- (0.1,0) [-102.4|429496729.5] "degree"  ASDM
 SG_ zipy_serialized_data_264_MFR : 256|32@1- (0.1,0) [-102.4|429496729.5] "degree"  ASDM
 SG_ zipy_serialized_data_265_MFR : 288|32@1- (0.1,0) [-102.4|429496729.5] "degree"  ASDM
 SG_ zipy_serialized_data_266_MFR : 320|32@1- (0.1,0) [-102.4|429496729.5] "degree"  ASDM
 SG_ zipy_serialized_data_267_MFR : 352|32@1- (0.1,0) [-102.4|429496729.5] "degree"  ASDM
 SG_ zipy_serialized_data_268_MFR : 384|32@1- (0.1,0) [-102.4|429496729.5] "degree"  ASDM
 SG_ zipy_serialized_data_269_MFR : 416|32@1- (0.1,0) [-102.4|429496729.5] "degree"  ASDM
 SG_ zipy_serialized_data_270_MFR : 448|32@1- (0.1,0) [-102.4|429496729.5] "degree"  ASDM
 SG_ zipy_serialized_data_271_MFR : 480|32@1- (0.1,0) [-102.4|429496729.5] "degree"  ASDM

BO_ 321 MB79_DETECTIONS_17_MFR: 64 FLRB
 SG_ zipy_serialized_data_272_MFR : 0|32@1- (0.1,0) [-102.4|429496729.5] "degree"  ASDM
 SG_ zipy_serialized_data_273_MFR : 32|32@1- (0.1,0) [-102.4|429496729.5] "degree"  ASDM
 SG_ zipy_serialized_data_274_MFR : 64|32@1- (0.1,0) [-102.4|429496729.5] "degree"  ASDM
 SG_ zipy_serialized_data_275_MFR : 96|32@1- (0.1,0) [-102.4|429496729.5] "degree"  ASDM
 SG_ zipy_serialized_data_276_MFR : 128|32@1- (0.1,0) [-102.4|429496729.5] "degree"  ASDM
 SG_ zipy_serialized_data_277_MFR : 160|32@1- (0.1,0) [-102.4|429496729.5] "degree"  ASDM
 SG_ zipy_serialized_data_278_MFR : 192|32@1- (0.1,0) [-102.4|429496729.5] "degree"  ASDM
 SG_ zipy_serialized_data_279_MFR : 224|32@1- (0.1,0) [-102.4|429496729.5] "degree"  ASDM
 SG_ zipy_serialized_data_280_MFR : 256|32@1- (0.1,0) [-102.4|429496729.5] "degree"  ASDM
 SG_ zipy_serialized_data_281_MFR : 288|32@1- (0.1,0) [-102.4|429496729.5] "degree"  ASDM
 SG_ zipy_serialized_data_282_MFR : 320|32@1- (0.1,0) [-102.4|429496729.5] "degree"  ASDM
 SG_ zipy_serialized_data_283_MFR : 352|32@1- (0.1,0) [-102.4|429496729.5] "degree"  ASDM
 SG_ zipy_serialized_data_284_MFR : 384|32@1- (0.1,0) [-102.4|429496729.5] "degree"  ASDM
 SG_ zipy_serialized_data_285_MFR : 416|32@1- (0.1,0) [-102.4|429496729.5] "degree"  ASDM
 SG_ zipy_serialized_data_286_MFR : 448|32@1- (0.1,0) [-102.4|429496729.5] "degree"  ASDM
 SG_ zipy_serialized_data_287_MFR : 480|32@1- (0.1,0) [-102.4|429496729.5] "degree"  ASDM

BO_ 322 MB79_DETECTIONS_18_MFR: 64 FLRB
 SG_ zipy_serialized_data_288_MFR : 0|32@1- (0.1,0) [-102.4|429496729.5] "degree"  ASDM
 SG_ zipy_serialized_data_289_MFR : 32|32@1- (0.1,0) [-102.4|429496729.5] "degree"  ASDM
 SG_ zipy_serialized_data_290_MFR : 64|32@1- (0.1,0) [-102.4|429496729.5] "degree"  ASDM
 SG_ zipy_serialized_data_291_MFR : 96|32@1- (0.1,0) [-102.4|429496729.5] "degree"  ASDM
 SG_ zipy_serialized_data_292_MFR : 128|32@1- (0.1,0) [-102.4|429496729.5] "degree"  ASDM
 SG_ zipy_serialized_data_293_MFR : 160|32@1- (0.1,0) [-102.4|429496729.5] "degree"  ASDM
 SG_ zipy_serialized_data_294_MFR : 192|32@1- (0.1,0) [-102.4|429496729.5] "degree"  ASDM
 SG_ zipy_serialized_data_295_MFR : 224|32@1- (0.1,0) [-102.4|429496729.5] "degree"  ASDM
 SG_ zipy_serialized_data_296_MFR : 256|32@1- (0.1,0) [-102.4|429496729.5] "degree"  ASDM
 SG_ zipy_serialized_data_297_MFR : 288|32@1- (0.1,0) [-102.4|429496729.5] "degree"  ASDM
 SG_ zipy_serialized_data_298_MFR : 320|32@1- (0.1,0) [-102.4|429496729.5] "degree"  ASDM
 SG_ zipy_serialized_data_299_MFR : 352|32@1- (0.1,0) [-102.4|429496729.5] "degree"  ASDM
 SG_ zipy_serialized_data_300_MFR : 384|32@1- (0.1,0) [-102.4|429496729.5] "degree"  ASDM
 SG_ zipy_serialized_data_301_MFR : 416|32@1- (0.1,0) [-102.4|429496729.5] "degree"  ASDM
 SG_ zipy_serialized_data_302_MFR : 448|32@1- (0.1,0) [-102.4|429496729.5] "degree"  ASDM
 SG_ zipy_serialized_data_303_MFR : 480|32@1- (0.1,0) [-102.4|429496729.5] "degree"  ASDM

BO_ 323 MB79_DETECTIONS_19_MFR: 64 FLRB
 SG_ zipy_serialized_data_304_MFR : 0|32@1- (0.1,0) [-102.4|429496729.5] "degree"  ASDM
 SG_ zipy_serialized_data_305_MFR : 32|32@1- (0.1,0) [-102.4|429496729.5] "degree"  ASDM
 SG_ zipy_serialized_data_306_MFR : 64|32@1- (0.1,0) [-102.4|429496729.5] "degree"  ASDM
 SG_ zipy_serialized_data_307_MFR : 96|32@1- (0.1,0) [-102.4|429496729.5] "degree"  ASDM
 SG_ zipy_serialized_data_308_MFR : 128|32@1- (0.1,0) [-102.4|429496729.5] "degree"  ASDM
 SG_ zipy_serialized_data_309_MFR : 160|32@1- (0.1,0) [-102.4|429496729.5] "degree"  ASDM
 SG_ zipy_serialized_data_310_MFR : 192|32@1- (0.1,0) [-102.4|429496729.5] "degree"  ASDM
 SG_ zipy_serialized_data_311_MFR : 224|32@1- (0.1,0) [-102.4|429496729.5] "degree"  ASDM
 SG_ zipy_serialized_data_312_MFR : 256|32@1- (0.1,0) [-102.4|429496729.5] "degree"  ASDM
 SG_ zipy_serialized_data_313_MFR : 288|32@1- (0.1,0) [-102.4|429496729.5] "degree"  ASDM
 SG_ zipy_serialized_data_314_MFR : 320|32@1- (0.1,0) [-102.4|429496729.5] "degree"  ASDM
 SG_ zipy_serialized_data_315_MFR : 352|32@1- (0.1,0) [-102.4|429496729.5] "degree"  ASDM
 SG_ zipy_serialized_data_316_MFR : 384|32@1- (0.1,0) [-102.4|429496729.5] "degree"  ASDM
 SG_ zipy_serialized_data_317_MFR : 416|32@1- (0.1,0) [-102.4|429496729.5] "degree"  ASDM
 SG_ zipy_serialized_data_318_MFR : 448|32@1- (0.1,0) [-102.4|429496729.5] "degree"  ASDM
 SG_ zipy_serialized_data_319_MFR : 480|32@1- (0.1,0) [-102.4|429496729.5] "degree"  ASDM

BO_ 324 MB79_DETECTIONS_20_MFR: 64 FLRB
 SG_ zipy_serialized_data_320_MFR : 0|32@1- (0.1,0) [-102.4|429496729.5] "degree"  ASDM
 SG_ zipy_serialized_data_321_MFR : 32|32@1- (0.1,0) [-102.4|429496729.5] "degree"  ASDM
 SG_ zipy_serialized_data_322_MFR : 64|32@1- (0.1,0) [-102.4|429496729.5] "degree"  ASDM
 SG_ zipy_serialized_data_323_MFR : 96|32@1- (0.1,0) [-102.4|429496729.5] "degree"  ASDM
 SG_ zipy_serialized_data_324_MFR : 128|32@1- (0.1,0) [-102.4|429496729.5] "degree"  ASDM
 SG_ zipy_serialized_data_325_MFR : 160|32@1- (0.1,0) [-102.4|429496729.5] "degree"  ASDM
 SG_ zipy_serialized_data_326_MFR : 192|32@1- (0.1,0) [-102.4|429496729.5] "degree"  ASDM
 SG_ zipy_serialized_data_327_MFR : 224|32@1- (0.1,0) [-102.4|429496729.5] "degree"  ASDM
 SG_ zipy_serialized_data_328_MFR : 256|32@1- (0.1,0) [-102.4|429496729.5] "degree"  ASDM
 SG_ zipy_serialized_data_329_MFR : 288|32@1- (0.1,0) [-102.4|429496729.5] "degree"  ASDM
 SG_ zipy_serialized_data_330_MFR : 320|32@1- (0.1,0) [-102.4|429496729.5] "degree"  ASDM
 SG_ zipy_serialized_data_331_MFR : 352|32@1- (0.1,0) [-102.4|429496729.5] "degree"  ASDM
 SG_ zipy_serialized_data_332_MFR : 384|32@1- (0.1,0) [-102.4|429496729.5] "degree"  ASDM
 SG_ zipy_serialized_data_333_MFR : 416|32@1- (0.1,0) [-102.4|429496729.5] "degree"  ASDM
 SG_ zipy_serialized_data_334_MFR : 448|32@1- (0.1,0) [-102.4|429496729.5] "degree"  ASDM
 SG_ zipy_serialized_data_335_MFR : 480|32@1- (0.1,0) [-102.4|429496729.5] "degree"  ASDM

BO_ 325 MB79_DETECTIONS_21_MFR: 64 FLRB
 SG_ zipy_serialized_data_336_MFR : 0|32@1- (0.1,0) [-102.4|429496729.5] "degree"  ASDM
 SG_ zipy_serialized_data_337_MFR : 32|32@1- (0.1,0) [-102.4|429496729.5] "degree"  ASDM
 SG_ zipy_serialized_data_338_MFR : 64|32@1- (0.1,0) [-102.4|429496729.5] "degree"  ASDM
 SG_ zipy_serialized_data_339_MFR : 96|32@1- (0.1,0) [-102.4|429496729.5] "degree"  ASDM
 SG_ zipy_serialized_data_340_MFR : 128|32@1- (0.1,0) [-102.4|429496729.5] "degree"  ASDM
 SG_ zipy_serialized_data_341_MFR : 160|32@1- (0.1,0) [-102.4|429496729.5] "degree"  ASDM
 SG_ zipy_serialized_data_342_MFR : 192|32@1- (0.1,0) [-102.4|429496729.5] "degree"  ASDM
 SG_ zipy_serialized_data_343_MFR : 224|32@1- (0.1,0) [-102.4|429496729.5] "degree"  ASDM
 SG_ zipy_serialized_data_344_MFR : 256|32@1- (0.1,0) [-102.4|429496729.5] "degree"  ASDM
 SG_ zipy_serialized_data_345_MFR : 288|32@1- (0.1,0) [-102.4|429496729.5] "degree"  ASDM
 SG_ zipy_serialized_data_346_MFR : 320|32@1- (0.1,0) [-102.4|429496729.5] "degree"  ASDM
 SG_ zipy_serialized_data_347_MFR : 352|32@1- (0.1,0) [-102.4|429496729.5] "degree"  ASDM
 SG_ zipy_serialized_data_348_MFR : 384|32@1- (0.1,0) [-102.4|429496729.5] "degree"  ASDM
 SG_ zipy_serialized_data_349_MFR : 416|32@1- (0.1,0) [-102.4|429496729.5] "degree"  ASDM
 SG_ zipy_serialized_data_350_MFR : 448|32@1- (0.1,0) [-102.4|429496729.5] "degree"  ASDM
 SG_ zipy_serialized_data_351_MFR : 480|32@1- (0.1,0) [-102.4|429496729.5] "degree"  ASDM

BO_ 326 MB79_DETECTIONS_22_MFR: 64 FLRB
 SG_ zipy_serialized_data_352_MFR : 0|32@1- (0.1,0) [-102.4|429496729.5] "degree"  ASDM
 SG_ zipy_serialized_data_353_MFR : 32|32@1- (0.1,0) [-102.4|429496729.5] "degree"  ASDM
 SG_ zipy_serialized_data_354_MFR : 64|32@1- (0.1,0) [-102.4|429496729.5] "degree"  ASDM
 SG_ zipy_serialized_data_355_MFR : 96|32@1- (0.1,0) [-102.4|429496729.5] "degree"  ASDM
 SG_ zipy_serialized_data_356_MFR : 128|32@1- (0.1,0) [-102.4|429496729.5] "degree"  ASDM
 SG_ zipy_serialized_data_357_MFR : 160|32@1- (0.1,0) [-102.4|429496729.5] "degree"  ASDM
 SG_ zipy_serialized_data_358_MFR : 192|32@1- (0.1,0) [-102.4|429496729.5] "degree"  ASDM
 SG_ zipy_serialized_data_359_MFR : 224|32@1- (0.1,0) [-102.4|429496729.5] "degree"  ASDM
 SG_ zipy_serialized_data_360_MFR : 256|32@1- (0.1,0) [-102.4|429496729.5] "degree"  ASDM
 SG_ zipy_serialized_data_361_MFR : 288|32@1- (0.1,0) [-102.4|429496729.5] "degree"  ASDM
 SG_ zipy_serialized_data_362_MFR : 320|32@1- (0.1,0) [-102.4|429496729.5] "degree"  ASDM
 SG_ zipy_serialized_data_363_MFR : 352|32@1- (0.1,0) [-102.4|429496729.5] "degree"  ASDM
 SG_ zipy_serialized_data_364_MFR : 384|32@1- (0.1,0) [-102.4|429496729.5] "degree"  ASDM
 SG_ zipy_serialized_data_365_MFR : 416|32@1- (0.1,0) [-102.4|429496729.5] "degree"  ASDM
 SG_ zipy_serialized_data_366_MFR : 448|32@1- (0.1,0) [-102.4|429496729.5] "degree"  ASDM
 SG_ zipy_serialized_data_367_MFR : 480|32@1- (0.1,0) [-102.4|429496729.5] "degree"  ASDM

BO_ 327 MB79_DETECTIONS_23_MFR: 64 FLRB
 SG_ zipy_serialized_data_368_MFR : 0|32@1- (0.1,0) [-102.4|429496729.5] "degree"  ASDM
 SG_ zipy_serialized_data_369_MFR : 32|32@1- (0.1,0) [-102.4|429496729.5] "degree"  ASDM
 SG_ zipy_serialized_data_370_MFR : 64|32@1- (0.1,0) [-102.4|429496729.5] "degree"  ASDM
 SG_ zipy_serialized_data_371_MFR : 96|32@1- (0.1,0) [-102.4|429496729.5] "degree"  ASDM
 SG_ zipy_serialized_data_372_MFR : 128|32@1- (0.1,0) [-102.4|429496729.5] "degree"  ASDM
 SG_ zipy_serialized_data_373_MFR : 160|32@1- (0.1,0) [-102.4|429496729.5] "degree"  ASDM
 SG_ zipy_serialized_data_374_MFR : 192|32@1- (0.1,0) [-102.4|429496729.5] "degree"  ASDM
 SG_ zipy_serialized_data_375_MFR : 224|32@1- (0.1,0) [-102.4|429496729.5] "degree"  ASDM
 SG_ zipy_serialized_data_376_MFR : 256|32@1- (0.1,0) [-102.4|429496729.5] "degree"  ASDM
 SG_ zipy_serialized_data_377_MFR : 288|32@1- (0.1,0) [-102.4|429496729.5] "degree"  ASDM
 SG_ zipy_serialized_data_378_MFR : 320|32@1- (0.1,0) [-102.4|429496729.5] "degree"  ASDM
 SG_ zipy_serialized_data_379_MFR : 352|32@1- (0.1,0) [-102.4|429496729.5] "degree"  ASDM
 SG_ zipy_serialized_data_380_MFR : 384|32@1- (0.1,0) [-102.4|429496729.5] "degree"  ASDM
 SG_ zipy_serialized_data_381_MFR : 416|32@1- (0.1,0) [-102.4|429496729.5] "degree"  ASDM
 SG_ zipy_serialized_data_382_MFR : 448|32@1- (0.1,0) [-102.4|429496729.5] "degree"  ASDM
 SG_ zipy_serialized_data_383_MFR : 480|32@1- (0.1,0) [-102.4|429496729.5] "degree"  ASDM

BO_ 328 MB79_DETECTIONS_24_MFR: 64 FLRB
 SG_ zipy_serialized_data_384_MFR : 0|32@1- (0.1,0) [-102.4|429496729.5] "degree"  ASDM
 SG_ zipy_serialized_data_385_MFR : 32|32@1- (0.1,0) [-102.4|429496729.5] "degree"  ASDM
 SG_ zipy_serialized_data_386_MFR : 64|32@1- (0.1,0) [-102.4|429496729.5] "degree"  ASDM
 SG_ zipy_serialized_data_387_MFR : 96|32@1- (0.1,0) [-102.4|429496729.5] "degree"  ASDM
 SG_ zipy_serialized_data_388_MFR : 128|32@1- (0.1,0) [-102.4|429496729.5] "degree"  ASDM
 SG_ zipy_serialized_data_389_MFR : 160|32@1- (0.1,0) [-102.4|429496729.5] "degree"  ASDM
 SG_ zipy_serialized_data_390_MFR : 192|32@1- (0.1,0) [-102.4|429496729.5] "degree"  ASDM
 SG_ zipy_serialized_data_391_MFR : 224|32@1- (0.1,0) [-102.4|429496729.5] "degree"  ASDM
 SG_ zipy_serialized_data_392_MFR : 256|32@1- (0.1,0) [-102.4|429496729.5] "degree"  ASDM
 SG_ zipy_serialized_data_393_MFR : 288|32@1- (0.1,0) [-102.4|429496729.5] "degree"  ASDM
 SG_ zipy_serialized_data_394_MFR : 320|32@1- (0.1,0) [-102.4|429496729.5] "degree"  ASDM
 SG_ zipy_serialized_data_395_MFR : 352|32@1- (0.1,0) [-102.4|429496729.5] "degree"  ASDM
 SG_ zipy_serialized_data_396_MFR : 384|32@1- (0.1,0) [-102.4|429496729.5] "degree"  ASDM
 SG_ zipy_serialized_data_397_MFR : 416|32@1- (0.1,0) [-102.4|429496729.5] "degree"  ASDM
 SG_ zipy_serialized_data_398_MFR : 448|32@1- (0.1,0) [-102.4|429496729.5] "degree"  ASDM
 SG_ zipy_serialized_data_399_MFR : 480|32@1- (0.1,0) [-102.4|429496729.5] "degree"  ASDM

BO_ 329 MB79_DETECTIONS_25_MFR: 64 FLRB
 SG_ zipy_serialized_data_400_MFR : 0|32@1- (0.1,0) [-102.4|429496729.5] "degree"  ASDM
 SG_ zipy_serialized_data_401_MFR : 32|32@1- (0.1,0) [-102.4|429496729.5] "degree"  ASDM
 SG_ zipy_serialized_data_402_MFR : 64|32@1- (0.1,0) [-102.4|429496729.5] "degree"  ASDM
 SG_ zipy_serialized_data_403_MFR : 96|32@1- (0.1,0) [-102.4|429496729.5] "degree"  ASDM
 SG_ zipy_serialized_data_404_MFR : 128|32@1- (0.1,0) [-102.4|429496729.5] "degree"  ASDM
 SG_ zipy_serialized_data_405_MFR : 160|32@1- (0.1,0) [-102.4|429496729.5] "degree"  ASDM
 SG_ zipy_serialized_data_406_MFR : 192|32@1- (0.1,0) [-102.4|429496729.5] "degree"  ASDM
 SG_ zipy_serialized_data_407_MFR : 224|32@1- (0.1,0) [-102.4|429496729.5] "degree"  ASDM
 SG_ zipy_serialized_data_408_MFR : 256|32@1- (0.1,0) [-102.4|429496729.5] "degree"  ASDM
 SG_ zipy_serialized_data_409_MFR : 288|32@1- (0.1,0) [-102.4|429496729.5] "degree"  ASDM
 SG_ zipy_serialized_data_410_MFR : 320|32@1- (0.1,0) [-102.4|429496729.5] "degree"  ASDM
 SG_ zipy_serialized_data_411_MFR : 352|32@1- (0.1,0) [-102.4|429496729.5] "degree"  ASDM
 SG_ zipy_serialized_data_412_MFR : 384|32@1- (0.1,0) [-102.4|429496729.5] "degree"  ASDM
 SG_ zipy_serialized_data_413_MFR : 416|32@1- (0.1,0) [-102.4|429496729.5] "degree"  ASDM
 SG_ zipy_serialized_data_414_MFR : 448|32@1- (0.1,0) [-102.4|429496729.5] "degree"  ASDM
 SG_ zipy_serialized_data_415_MFR : 480|32@1- (0.1,0) [-102.4|429496729.5] "degree"  ASDM

BO_ 330 MB79_DETECTIONS_26_MFR: 64 FLRB
 SG_ zipy_serialized_data_416_MFR : 0|32@1- (0.1,0) [-102.4|429496729.5] "degree"  ASDM
 SG_ zipy_serialized_data_417_MFR : 32|32@1- (0.1,0) [-102.4|429496729.5] "degree"  ASDM
 SG_ zipy_serialized_data_418_MFR : 64|32@1- (0.1,0) [-102.4|429496729.5] "degree"  ASDM
 SG_ zipy_serialized_data_419_MFR : 96|32@1- (0.1,0) [-102.4|429496729.5] "degree"  ASDM
 SG_ zipy_serialized_data_420_MFR : 128|32@1- (0.1,0) [-102.4|429496729.5] "degree"  ASDM
 SG_ zipy_serialized_data_421_MFR : 160|32@1- (0.1,0) [-102.4|429496729.5] "degree"  ASDM
 SG_ zipy_serialized_data_422_MFR : 192|32@1- (0.1,0) [-102.4|429496729.5] "degree"  ASDM
 SG_ zipy_serialized_data_423_MFR : 224|32@1- (0.1,0) [-102.4|429496729.5] "degree"  ASDM
 SG_ zipy_serialized_data_424_MFR : 256|32@1- (0.1,0) [-102.4|429496729.5] "degree"  ASDM
 SG_ zipy_serialized_data_425_MFR : 288|32@1- (0.1,0) [-102.4|429496729.5] "degree"  ASDM
 SG_ zipy_serialized_data_426_MFR : 320|32@1- (0.1,0) [-102.4|429496729.5] "degree"  ASDM
 SG_ zipy_serialized_data_427_MFR : 352|32@1- (0.1,0) [-102.4|429496729.5] "degree"  ASDM
 SG_ zipy_serialized_data_428_MFR : 384|32@1- (0.1,0) [-102.4|429496729.5] "degree"  ASDM
 SG_ zipy_serialized_data_429_MFR : 416|32@1- (0.1,0) [-102.4|429496729.5] "degree"  ASDM
 SG_ zipy_serialized_data_430_MFR : 448|32@1- (0.1,0) [-102.4|429496729.5] "degree"  ASDM
 SG_ zipy_serialized_data_431_MFR : 480|32@1- (0.1,0) [-102.4|429496729.5] "degree"  ASDM

BO_ 331 MB79_DETECTIONS_27_MFR: 64 FLRB
 SG_ zipy_serialized_data_432_MFR : 0|32@1- (0.1,0) [-102.4|429496729.5] "degree"  ASDM
 SG_ zipy_serialized_data_433_MFR : 32|32@1- (0.1,0) [-102.4|429496729.5] "degree"  ASDM
 SG_ zipy_serialized_data_434_MFR : 64|32@1- (0.1,0) [-102.4|429496729.5] "degree"  ASDM
 SG_ zipy_serialized_data_435_MFR : 96|32@1- (0.1,0) [-102.4|429496729.5] "degree"  ASDM
 SG_ zipy_serialized_data_436_MFR : 128|32@1- (0.1,0) [-102.4|429496729.5] "degree"  ASDM
 SG_ zipy_serialized_data_437_MFR : 160|32@1- (0.1,0) [-102.4|429496729.5] "degree"  ASDM
 SG_ zipy_serialized_data_438_MFR : 192|32@1- (0.1,0) [-102.4|429496729.5] "degree"  ASDM
 SG_ zipy_serialized_data_439_MFR : 224|32@1- (0.1,0) [-102.4|429496729.5] "degree"  ASDM
 SG_ zipy_serialized_data_440_MFR : 256|32@1- (0.1,0) [-102.4|429496729.5] "degree"  ASDM
 SG_ zipy_serialized_data_441_MFR : 288|32@1- (0.1,0) [-102.4|429496729.5] "degree"  ASDM
 SG_ zipy_serialized_data_442_MFR : 320|32@1- (0.1,0) [-102.4|429496729.5] "degree"  ASDM
 SG_ zipy_serialized_data_443_MFR : 352|32@1- (0.1,0) [-102.4|429496729.5] "degree"  ASDM
 SG_ zipy_serialized_data_444_MFR : 384|32@1- (0.1,0) [-102.4|429496729.5] "degree"  ASDM
 SG_ zipy_serialized_data_445_MFR : 416|32@1- (0.1,0) [-102.4|429496729.5] "degree"  ASDM
 SG_ zipy_serialized_data_446_MFR : 448|32@1- (0.1,0) [-102.4|429496729.5] "degree"  ASDM
 SG_ zipy_serialized_data_447_MFR : 480|32@1- (0.1,0) [-102.4|429496729.5] "degree"  ASDM

BO_ 332 MB79_DETECTIONS_28_MFR: 64 FLRB
 SG_ zipy_serialized_data_448_MFR : 0|32@1- (0.1,0) [-102.4|429496729.5] "degree"  ASDM
 SG_ zipy_serialized_data_449_MFR : 32|32@1- (0.1,0) [-102.4|429496729.5] "degree"  ASDM
 SG_ zipy_serialized_data_450_MFR : 64|32@1- (0.1,0) [-102.4|429496729.5] "degree"  ASDM
 SG_ zipy_serialized_data_451_MFR : 96|32@1- (0.1,0) [-102.4|429496729.5] "degree"  ASDM
 SG_ zipy_serialized_data_452_MFR : 128|32@1- (0.1,0) [-102.4|429496729.5] "degree"  ASDM
 SG_ zipy_serialized_data_453_MFR : 160|32@1- (0.1,0) [-102.4|429496729.5] "degree"  ASDM
 SG_ zipy_serialized_data_454_MFR : 192|32@1- (0.1,0) [-102.4|429496729.5] "degree"  ASDM
 SG_ zipy_serialized_data_455_MFR : 224|32@1- (0.1,0) [-102.4|429496729.5] "degree"  ASDM
 SG_ zipy_serialized_data_456_MFR : 256|32@1- (0.1,0) [-102.4|429496729.5] "degree"  ASDM
 SG_ zipy_serialized_data_457_MFR : 288|32@1- (0.1,0) [-102.4|429496729.5] "degree"  ASDM
 SG_ zipy_serialized_data_458_MFR : 320|32@1- (0.1,0) [-102.4|429496729.5] "degree"  ASDM
 SG_ zipy_serialized_data_459_MFR : 352|32@1- (0.1,0) [-102.4|429496729.5] "degree"  ASDM
 SG_ zipy_serialized_data_460_MFR : 384|32@1- (0.1,0) [-102.4|429496729.5] "degree"  ASDM
 SG_ zipy_serialized_data_461_MFR : 416|32@1- (0.1,0) [-102.4|429496729.5] "degree"  ASDM
 SG_ zipy_serialized_data_462_MFR : 448|32@1- (0.1,0) [-102.4|429496729.5] "degree"  ASDM
 SG_ zipy_serialized_data_463_MFR : 480|32@1- (0.1,0) [-102.4|429496729.5] "degree"  ASDM

BO_ 333 MB79_DETECTIONS_29_MFR: 64 FLRB
 SG_ zipy_serialized_data_464_MFR : 0|32@1- (0.1,0) [-102.4|429496729.5] "degree"  ASDM
 SG_ zipy_serialized_data_465_MFR : 32|32@1- (0.1,0) [-102.4|429496729.5] "degree"  ASDM
 SG_ zipy_serialized_data_466_MFR : 64|32@1- (0.1,0) [-102.4|429496729.5] "degree"  ASDM
 SG_ zipy_serialized_data_467_MFR : 96|32@1- (0.1,0) [-102.4|429496729.5] "degree"  ASDM
 SG_ zipy_serialized_data_468_MFR : 128|32@1- (0.1,0) [-102.4|429496729.5] "degree"  ASDM
 SG_ zipy_serialized_data_469_MFR : 160|32@1- (0.1,0) [-102.4|429496729.5] "degree"  ASDM
 SG_ zipy_serialized_data_470_MFR : 192|32@1- (0.1,0) [-102.4|429496729.5] "degree"  ASDM
 SG_ zipy_serialized_data_471_MFR : 224|32@1- (0.1,0) [-102.4|429496729.5] "degree"  ASDM
 SG_ zipy_serialized_data_472_MFR : 256|32@1- (0.1,0) [-102.4|429496729.5] "degree"  ASDM
 SG_ zipy_serialized_data_473_MFR : 288|32@1- (0.1,0) [-102.4|429496729.5] "degree"  ASDM
 SG_ zipy_serialized_data_474_MFR : 320|32@1- (0.1,0) [-102.4|429496729.5] "degree"  ASDM
 SG_ zipy_serialized_data_475_MFR : 352|32@1- (0.1,0) [-102.4|429496729.5] "degree"  ASDM
 SG_ zipy_serialized_data_476_MFR : 384|32@1- (0.1,0) [-102.4|429496729.5] "degree"  ASDM
 SG_ zipy_serialized_data_477_MFR : 416|32@1- (0.1,0) [-102.4|429496729.5] "degree"  ASDM
 SG_ zipy_serialized_data_478_MFR : 448|32@1- (0.1,0) [-102.4|429496729.5] "degree"  ASDM
 SG_ zipy_serialized_data_479_MFR : 480|32@1- (0.1,0) [-102.4|429496729.5] "degree"  ASDM

BO_ 334 MB79_DETECTIONS_30_MFR: 64 FLRB
 SG_ zipy_serialized_data_480_MFR : 0|32@1- (0.1,0) [-102.4|429496729.5] "degree"  ASDM
 SG_ zipy_serialized_data_481_MFR : 32|32@1- (0.1,0) [-102.4|429496729.5] "degree"  ASDM
 SG_ zipy_serialized_data_482_MFR : 64|32@1- (0.1,0) [-102.4|429496729.5] "degree"  ASDM
 SG_ zipy_serialized_data_483_MFR : 96|32@1- (0.1,0) [-102.4|429496729.5] "degree"  ASDM
 SG_ zipy_serialized_data_484_MFR : 128|32@1- (0.1,0) [-102.4|429496729.5] "degree"  ASDM
 SG_ zipy_serialized_data_485_MFR : 160|32@1- (0.1,0) [-102.4|429496729.5] "degree"  ASDM
 SG_ zipy_serialized_data_486_MFR : 192|32@1- (0.1,0) [-102.4|429496729.5] "degree"  ASDM
 SG_ zipy_serialized_data_487_MFR : 224|32@1- (0.1,0) [-102.4|429496729.5] "degree"  ASDM
 SG_ zipy_serialized_data_488_MFR : 256|32@1- (0.1,0) [-102.4|429496729.5] "degree"  ASDM
 SG_ zipy_serialized_data_489_MFR : 288|32@1- (0.1,0) [-102.4|429496729.5] "degree"  ASDM
 SG_ zipy_serialized_data_490_MFR : 320|32@1- (0.1,0) [-102.4|429496729.5] "degree"  ASDM
 SG_ zipy_serialized_data_491_MFR : 352|32@1- (0.1,0) [-102.4|429496729.5] "degree"  ASDM
 SG_ zipy_serialized_data_492_MFR : 384|32@1- (0.1,0) [-102.4|429496729.5] "degree"  ASDM
 SG_ zipy_serialized_data_493_MFR : 416|32@1- (0.1,0) [-102.4|429496729.5] "degree"  ASDM
 SG_ zipy_serialized_data_494_MFR : 448|32@1- (0.1,0) [-102.4|429496729.5] "degree"  ASDM
 SG_ zipy_serialized_data_495_MFR : 480|32@1- (0.1,0) [-102.4|429496729.5] "degree"  ASDM

BO_ 335 MB79_DETECTIONS_31_MFR: 64 FLRB
 SG_ zipy_serialized_data_496_MFR : 0|32@1- (0.1,0) [-102.4|429496729.5] "degree"  ASDM
 SG_ zipy_serialized_data_497_MFR : 32|32@1- (0.1,0) [-102.4|429496729.5] "degree"  ASDM
 SG_ zipy_serialized_data_498_MFR : 64|32@1- (0.1,0) [-102.4|429496729.5] "degree"  ASDM
 SG_ zipy_serialized_data_499_MFR : 96|32@1- (0.1,0) [-102.4|429496729.5] "degree"  ASDM
 SG_ zipy_serialized_data_500_MFR : 128|32@1- (0.1,0) [-102.4|429496729.5] "degree"  ASDM
 SG_ zipy_serialized_data_501_MFR : 160|32@1- (0.1,0) [-102.4|429496729.5] "degree"  ASDM
 SG_ zipy_serialized_data_502_MFR : 192|32@1- (0.1,0) [-102.4|429496729.5] "degree"  ASDM
 SG_ zipy_serialized_data_503_MFR : 224|32@1- (0.1,0) [-102.4|429496729.5] "degree"  ASDM
 SG_ zipy_serialized_data_504_MFR : 256|32@1- (0.1,0) [-102.4|429496729.5] "degree"  ASDM
 SG_ zipy_serialized_data_505_MFR : 288|32@1- (0.1,0) [-102.4|429496729.5] "degree"  ASDM
 SG_ zipy_serialized_data_506_MFR : 320|32@1- (0.1,0) [-102.4|429496729.5] "degree"  ASDM
 SG_ zipy_serialized_data_507_MFR : 352|32@1- (0.1,0) [-102.4|429496729.5] "degree"  ASDM
 SG_ zipy_serialized_data_508_MFR : 384|32@1- (0.1,0) [-102.4|429496729.5] "degree"  ASDM
 SG_ zipy_serialized_data_509_MFR : 416|32@1- (0.1,0) [-102.4|429496729.5] "degree"  ASDM
 SG_ zipy_serialized_data_510_MFR : 448|32@1- (0.1,0) [-102.4|429496729.5] "degree"  ASDM
 SG_ zipy_serialized_data_511_MFR : 480|32@1- (0.1,0) [-102.4|429496729.5] "degree"  ASDM

BO_ 336 MB79_DETECTIONS_32_MFR: 64 FLRB
 SG_ zipy_serialized_data_512_MFR : 0|32@1- (0.1,0) [-102.4|429496729.5] "degree"  ASDM
 SG_ zipy_serialized_data_513_MFR : 32|32@1- (0.1,0) [-102.4|429496729.5] "degree"  ASDM
 SG_ zipy_serialized_data_514_MFR : 64|32@1- (0.1,0) [-102.4|429496729.5] "degree"  ASDM
 SG_ zipy_serialized_data_515_MFR : 96|32@1- (0.1,0) [-102.4|429496729.5] "degree"  ASDM
 SG_ zipy_serialized_data_516_MFR : 128|32@1- (0.1,0) [-102.4|429496729.5] "degree"  ASDM
 SG_ zipy_serialized_data_517_MFR : 160|32@1- (0.1,0) [-102.4|429496729.5] "degree"  ASDM
 SG_ zipy_serialized_data_518_MFR : 192|32@1- (0.1,0) [-102.4|429496729.5] "degree"  ASDM
 SG_ zipy_serialized_data_519_MFR : 224|32@1- (0.1,0) [-102.4|429496729.5] "degree"  ASDM
 SG_ zipy_serialized_data_520_MFR : 256|32@1- (0.1,0) [-102.4|429496729.5] "degree"  ASDM
 SG_ zipy_serialized_data_521_MFR : 288|32@1- (0.1,0) [-102.4|429496729.5] "degree"  ASDM
 SG_ zipy_serialized_data_522_MFR : 320|32@1- (0.1,0) [-102.4|429496729.5] "degree"  ASDM
 SG_ zipy_serialized_data_523_MFR : 352|32@1- (0.1,0) [-102.4|429496729.5] "degree"  ASDM
 SG_ zipy_serialized_data_524_MFR : 384|32@1- (0.1,0) [-102.4|429496729.5] "degree"  ASDM
 SG_ zipy_serialized_data_525_MFR : 416|32@1- (0.1,0) [-102.4|429496729.5] "degree"  ASDM
 SG_ zipy_serialized_data_526_MFR : 448|32@1- (0.1,0) [-102.4|429496729.5] "degree"  ASDM
 SG_ zipy_serialized_data_527_MFR : 480|32@1- (0.1,0) [-102.4|429496729.5] "degree"  ASDM

BO_ 337 MB79_DETECTIONS_33_MFR: 64 FLRB
 SG_ zipy_serialized_data_528_MFR : 0|32@1- (0.1,0) [-102.4|429496729.5] "degree"  ASDM
 SG_ zipy_serialized_data_529_MFR : 32|32@1- (0.1,0) [-102.4|429496729.5] "degree"  ASDM
 SG_ zipy_serialized_data_530_MFR : 64|32@1- (0.1,0) [-102.4|429496729.5] "degree"  ASDM
 SG_ zipy_serialized_data_531_MFR : 96|32@1- (0.1,0) [-102.4|429496729.5] "degree"  ASDM
 SG_ zipy_serialized_data_532_MFR : 128|32@1- (0.1,0) [-102.4|429496729.5] "degree"  ASDM
 SG_ zipy_serialized_data_533_MFR : 160|32@1- (0.1,0) [-102.4|429496729.5] "degree"  ASDM
 SG_ zipy_serialized_data_534_MFR : 192|32@1- (0.1,0) [-102.4|429496729.5] "degree"  ASDM
 SG_ zipy_serialized_data_535_MFR : 224|32@1- (0.1,0) [-102.4|429496729.5] "degree"  ASDM
 SG_ zipy_serialized_data_536_MFR : 256|32@1- (0.1,0) [-102.4|429496729.5] "degree"  ASDM
 SG_ zipy_serialized_data_537_MFR : 288|32@1- (0.1,0) [-102.4|429496729.5] "degree"  ASDM
 SG_ zipy_serialized_data_538_MFR : 320|32@1- (0.1,0) [-102.4|429496729.5] "degree"  ASDM
 SG_ zipy_serialized_data_539_MFR : 352|32@1- (0.1,0) [-102.4|429496729.5] "degree"  ASDM
 SG_ zipy_serialized_data_540_MFR : 384|32@1- (0.1,0) [-102.4|429496729.5] "degree"  ASDM
 SG_ zipy_serialized_data_541_MFR : 416|32@1- (0.1,0) [-102.4|429496729.5] "degree"  ASDM
 SG_ zipy_serialized_data_542_MFR : 448|32@1- (0.1,0) [-102.4|429496729.5] "degree"  ASDM
 SG_ zipy_serialized_data_543_MFR : 480|32@1- (0.1,0) [-102.4|429496729.5] "degree"  ASDM

BO_ 338 MB79_DETECTIONS_34_MFR: 64 FLRB
 SG_ zipy_serialized_data_544_MFR : 0|32@1- (0.1,0) [-102.4|429496729.5] "degree"  ASDM
 SG_ zipy_serialized_data_545_MFR : 32|32@1- (0.1,0) [-102.4|429496729.5] "degree"  ASDM
 SG_ zipy_serialized_data_546_MFR : 64|32@1- (0.1,0) [-102.4|429496729.5] "degree"  ASDM
 SG_ zipy_serialized_data_547_MFR : 96|32@1- (0.1,0) [-102.4|429496729.5] "degree"  ASDM
 SG_ zipy_serialized_data_548_MFR : 128|32@1- (0.1,0) [-102.4|429496729.5] "degree"  ASDM
 SG_ zipy_serialized_data_549_MFR : 160|32@1- (0.1,0) [-102.4|429496729.5] "degree"  ASDM
 SG_ zipy_serialized_data_550_MFR : 192|32@1- (0.1,0) [-102.4|429496729.5] "degree"  ASDM
 SG_ zipy_serialized_data_551_MFR : 224|32@1- (0.1,0) [-102.4|429496729.5] "degree"  ASDM
 SG_ zipy_serialized_data_552_MFR : 256|32@1- (0.1,0) [-102.4|429496729.5] "degree"  ASDM
 SG_ zipy_serialized_data_553_MFR : 288|32@1- (0.1,0) [-102.4|429496729.5] "degree"  ASDM
 SG_ zipy_serialized_data_554_MFR : 320|32@1- (0.1,0) [-102.4|429496729.5] "degree"  ASDM
 SG_ zipy_serialized_data_555_MFR : 352|32@1- (0.1,0) [-102.4|429496729.5] "degree"  ASDM
 SG_ zipy_serialized_data_556_MFR : 384|32@1- (0.1,0) [-102.4|429496729.5] "degree"  ASDM
 SG_ zipy_serialized_data_557_MFR : 416|32@1- (0.1,0) [-102.4|429496729.5] "degree"  ASDM
 SG_ zipy_serialized_data_558_MFR : 448|32@1- (0.1,0) [-102.4|429496729.5] "degree"  ASDM
 SG_ zipy_serialized_data_559_MFR : 480|32@1- (0.1,0) [-102.4|429496729.5] "degree"  ASDM

BO_ 339 MB79_DETECTIONS_35_MFR: 64 FLRB
 SG_ zipy_serialized_data_560_MFR : 0|32@1- (0.1,0) [-102.4|429496729.5] "degree"  ASDM
 SG_ zipy_serialized_data_561_MFR : 32|32@1- (0.1,0) [-102.4|429496729.5] "degree"  ASDM
 SG_ zipy_serialized_data_562_MFR : 64|32@1- (0.1,0) [-102.4|429496729.5] "degree"  ASDM
 SG_ zipy_serialized_data_563_MFR : 96|32@1- (0.1,0) [-102.4|429496729.5] "degree"  ASDM
 SG_ zipy_serialized_data_564_MFR : 128|32@1- (0.1,0) [-102.4|429496729.5] "degree"  ASDM
 SG_ zipy_serialized_data_565_MFR : 160|32@1- (0.1,0) [-102.4|429496729.5] "degree"  ASDM
 SG_ zipy_serialized_data_566_MFR : 192|32@1- (0.1,0) [-102.4|429496729.5] "degree"  ASDM
 SG_ zipy_serialized_data_567_MFR : 224|32@1- (0.1,0) [-102.4|429496729.5] "degree"  ASDM
 SG_ zipy_serialized_data_568_MFR : 256|32@1- (0.1,0) [-102.4|429496729.5] "degree"  ASDM
 SG_ zipy_serialized_data_569_MFR : 288|32@1- (0.1,0) [-102.4|429496729.5] "degree"  ASDM
 SG_ zipy_serialized_data_570_MFR : 320|32@1- (0.1,0) [-102.4|429496729.5] "degree"  ASDM
 SG_ zipy_serialized_data_571_MFR : 352|32@1- (0.1,0) [-102.4|429496729.5] "degree"  ASDM
 SG_ zipy_serialized_data_572_MFR : 384|32@1- (0.1,0) [-102.4|429496729.5] "degree"  ASDM
 SG_ zipy_serialized_data_573_MFR : 416|32@1- (0.1,0) [-102.4|429496729.5] "degree"  ASDM
 SG_ zipy_serialized_data_574_MFR : 448|32@1- (0.1,0) [-102.4|429496729.5] "degree"  ASDM
 SG_ zipy_serialized_data_575_MFR : 480|32@1- (0.1,0) [-102.4|429496729.5] "degree"  ASDM

BO_ 340 MB79_DETECTIONS_36_MFR: 64 FLRB
 SG_ zipy_serialized_data_576_MFR : 0|32@1- (0.1,0) [-102.4|429496729.5] "degree"  ASDM
 SG_ zipy_serialized_data_577_MFR : 32|32@1- (0.1,0) [-102.4|429496729.5] "degree"  ASDM
 SG_ zipy_serialized_data_578_MFR : 64|32@1- (0.1,0) [-102.4|429496729.5] "degree"  ASDM
 SG_ zipy_serialized_data_579_MFR : 96|32@1- (0.1,0) [-102.4|429496729.5] "degree"  ASDM
 SG_ zipy_serialized_data_580_MFR : 128|32@1- (0.1,0) [-102.4|429496729.5] "degree"  ASDM
 SG_ zipy_serialized_data_581_MFR : 160|32@1- (0.1,0) [-102.4|429496729.5] "degree"  ASDM
 SG_ zipy_serialized_data_582_MFR : 192|32@1- (0.1,0) [-102.4|429496729.5] "degree"  ASDM
 SG_ zipy_serialized_data_583_MFR : 224|32@1- (0.1,0) [-102.4|429496729.5] "degree"  ASDM
 SG_ zipy_serialized_data_584_MFR : 256|32@1- (0.1,0) [-102.4|429496729.5] "degree"  ASDM
 SG_ zipy_serialized_data_585_MFR : 288|32@1- (0.1,0) [-102.4|429496729.5] "degree"  ASDM
 SG_ zipy_serialized_data_586_MFR : 320|32@1- (0.1,0) [-102.4|429496729.5] "degree"  ASDM
 SG_ zipy_serialized_data_587_MFR : 352|32@1- (0.1,0) [-102.4|429496729.5] "degree"  ASDM
 SG_ zipy_serialized_data_588_MFR : 384|32@1- (0.1,0) [-102.4|429496729.5] "degree"  ASDM
 SG_ zipy_serialized_data_589_MFR : 416|32@1- (0.1,0) [-102.4|429496729.5] "degree"  ASDM
 SG_ zipy_serialized_data_590_MFR : 448|32@1- (0.1,0) [-102.4|429496729.5] "degree"  ASDM
 SG_ zipy_serialized_data_591_MFR : 480|32@1- (0.1,0) [-102.4|429496729.5] "degree"  ASDM

BO_ 341 MB79_DETECTIONS_37_MFR: 64 FLRB
 SG_ zipy_serialized_data_592_MFR : 0|32@1- (0.1,0) [-102.4|429496729.5] "degree"  ASDM
 SG_ zipy_serialized_data_593_MFR : 32|32@1- (0.1,0) [-102.4|429496729.5] "degree"  ASDM
 SG_ zipy_serialized_data_594_MFR : 64|32@1- (0.1,0) [-102.4|429496729.5] "degree"  ASDM
 SG_ zipy_serialized_data_595_MFR : 96|32@1- (0.1,0) [-102.4|429496729.5] "degree"  ASDM
 SG_ zipy_serialized_data_596_MFR : 128|32@1- (0.1,0) [-102.4|429496729.5] "degree"  ASDM
 SG_ zipy_serialized_data_597_MFR : 160|32@1- (0.1,0) [-102.4|429496729.5] "degree"  ASDM
 SG_ zipy_serialized_data_598_MFR : 192|32@1- (0.1,0) [-102.4|429496729.5] "degree"  ASDM
 SG_ zipy_serialized_data_599_MFR : 224|32@1- (0.1,0) [-102.4|429496729.5] "degree"  ASDM
 SG_ zipy_serialized_data_600_MFR : 256|32@1- (0.1,0) [-102.4|429496729.5] "degree"  ASDM
 SG_ zipy_serialized_data_601_MFR : 288|32@1- (0.1,0) [-102.4|429496729.5] "degree"  ASDM
 SG_ zipy_serialized_data_602_MFR : 320|32@1- (0.1,0) [-102.4|429496729.5] "degree"  ASDM
 SG_ zipy_serialized_data_603_MFR : 352|32@1- (0.1,0) [-102.4|429496729.5] "degree"  ASDM
 SG_ zipy_serialized_data_604_MFR : 384|32@1- (0.1,0) [-102.4|429496729.5] "degree"  ASDM
 SG_ zipy_serialized_data_605_MFR : 416|32@1- (0.1,0) [-102.4|429496729.5] "degree"  ASDM
 SG_ zipy_serialized_data_606_MFR : 448|32@1- (0.1,0) [-102.4|429496729.5] "degree"  ASDM
 SG_ zipy_serialized_data_607_MFR : 480|32@1- (0.1,0) [-102.4|429496729.5] "degree"  ASDM

BO_ 342 MB79_DETECTIONS_38_MFR: 64 FLRB
 SG_ zipy_serialized_data_608_MFR : 0|32@1- (0.1,0) [-102.4|429496729.5] "degree"  ASDM
 SG_ zipy_serialized_data_609_MFR : 32|32@1- (0.1,0) [-102.4|429496729.5] "degree"  ASDM
 SG_ zipy_serialized_data_610_MFR : 64|32@1- (0.1,0) [-102.4|429496729.5] "degree"  ASDM
 SG_ zipy_serialized_data_611_MFR : 96|32@1- (0.1,0) [-102.4|429496729.5] "degree"  ASDM
 SG_ zipy_serialized_data_612_MFR : 128|32@1- (0.1,0) [-102.4|429496729.5] "degree"  ASDM
 SG_ zipy_serialized_data_613_MFR : 160|32@1- (0.1,0) [-102.4|429496729.5] "degree"  ASDM
 SG_ zipy_serialized_data_614_MFR : 192|32@1- (0.1,0) [-102.4|429496729.5] "degree"  ASDM
 SG_ zipy_serialized_data_615_MFR : 224|32@1- (0.1,0) [-102.4|429496729.5] "degree"  ASDM
 SG_ zipy_serialized_data_616_MFR : 256|32@1- (0.1,0) [-102.4|429496729.5] "degree"  ASDM
 SG_ zipy_serialized_data_617_MFR : 288|32@1- (0.1,0) [-102.4|429496729.5] "degree"  ASDM
 SG_ zipy_serialized_data_618_MFR : 320|32@1- (0.1,0) [-102.4|429496729.5] "degree"  ASDM
 SG_ zipy_serialized_data_619_MFR : 352|32@1- (0.1,0) [-102.4|429496729.5] "degree"  ASDM
 SG_ zipy_serialized_data_620_MFR : 384|32@1- (0.1,0) [-102.4|429496729.5] "degree"  ASDM
 SG_ zipy_serialized_data_621_MFR : 416|32@1- (0.1,0) [-102.4|429496729.5] "degree"  ASDM
 SG_ zipy_serialized_data_622_MFR : 448|32@1- (0.1,0) [-102.4|429496729.5] "degree"  ASDM
 SG_ zipy_serialized_data_623_MFR : 480|32@1- (0.1,0) [-102.4|429496729.5] "degree"  ASDM

BO_ 343 MB79_DETECTIONS_39_MFR: 64 FLRB
 SG_ zipy_serialized_data_624_MFR : 0|32@1- (0.1,0) [-102.4|429496729.5] "degree"  ASDM
 SG_ zipy_serialized_data_625_MFR : 32|32@1- (0.1,0) [-102.4|429496729.5] "degree"  ASDM
 SG_ zipy_serialized_data_626_MFR : 64|32@1- (0.1,0) [-102.4|429496729.5] "degree"  ASDM
 SG_ zipy_serialized_data_627_MFR : 96|32@1- (0.1,0) [-102.4|429496729.5] "degree"  ASDM
 SG_ zipy_serialized_data_628_MFR : 128|32@1- (0.1,0) [-102.4|429496729.5] "degree"  ASDM
 SG_ zipy_serialized_data_629_MFR : 160|32@1- (0.1,0) [-102.4|429496729.5] "degree"  ASDM
 SG_ zipy_serialized_data_630_MFR : 192|32@1- (0.1,0) [-102.4|429496729.5] "degree"  ASDM
 SG_ zipy_serialized_data_631_MFR : 224|32@1- (0.1,0) [-102.4|429496729.5] "degree"  ASDM
 SG_ zipy_serialized_data_632_MFR : 256|32@1- (0.1,0) [-102.4|429496729.5] "degree"  ASDM
 SG_ zipy_serialized_data_633_MFR : 288|32@1- (0.1,0) [-102.4|429496729.5] "degree"  ASDM
 SG_ zipy_serialized_data_634_MFR : 320|32@1- (0.1,0) [-102.4|429496729.5] "degree"  ASDM
 SG_ zipy_serialized_data_635_MFR : 352|32@1- (0.1,0) [-102.4|429496729.5] "degree"  ASDM
 SG_ zipy_serialized_data_636_MFR : 384|32@1- (0.1,0) [-102.4|429496729.5] "degree"  ASDM
 SG_ zipy_serialized_data_637_MFR : 416|32@1- (0.1,0) [-102.4|429496729.5] "degree"  ASDM
 SG_ zipy_serialized_data_638_MFR : 448|32@1- (0.1,0) [-102.4|429496729.5] "degree"  ASDM
 SG_ zipy_serialized_data_639_MFR : 480|32@1- (0.1,0) [-102.4|429496729.5] "degree"  ASDM

BO_ 344 MB79_DETECTIONS_40_MFR: 64 FLRB
 SG_ zipy_serialized_data_640_MFR : 0|32@1- (0.1,0) [-102.4|429496729.5] "degree"  ASDM
 SG_ zipy_serialized_data_641_MFR : 32|32@1- (0.1,0) [-102.4|429496729.5] "degree"  ASDM
 SG_ zipy_serialized_data_642_MFR : 64|32@1- (0.1,0) [-102.4|429496729.5] "degree"  ASDM
 SG_ zipy_serialized_data_643_MFR : 96|32@1- (0.1,0) [-102.4|429496729.5] "degree"  ASDM
 SG_ zipy_serialized_data_644_MFR : 128|32@1- (0.1,0) [-102.4|429496729.5] "degree"  ASDM
 SG_ zipy_serialized_data_645_MFR : 160|32@1- (0.1,0) [-102.4|429496729.5] "degree"  ASDM
 SG_ zipy_serialized_data_646_MFR : 192|32@1- (0.1,0) [-102.4|429496729.5] "degree"  ASDM
 SG_ zipy_serialized_data_647_MFR : 224|32@1- (0.1,0) [-102.4|429496729.5] "degree"  ASDM
 SG_ zipy_serialized_data_648_MFR : 256|32@1- (0.1,0) [-102.4|429496729.5] "degree"  ASDM
 SG_ zipy_serialized_data_649_MFR : 288|32@1- (0.1,0) [-102.4|429496729.5] "degree"  ASDM
 SG_ zipy_serialized_data_650_MFR : 320|32@1- (0.1,0) [-102.4|429496729.5] "degree"  ASDM
 SG_ zipy_serialized_data_651_MFR : 352|32@1- (0.1,0) [-102.4|429496729.5] "degree"  ASDM
 SG_ zipy_serialized_data_652_MFR : 384|32@1- (0.1,0) [-102.4|429496729.5] "degree"  ASDM
 SG_ zipy_serialized_data_653_MFR : 416|32@1- (0.1,0) [-102.4|429496729.5] "degree"  ASDM
 SG_ zipy_serialized_data_654_MFR : 448|32@1- (0.1,0) [-102.4|429496729.5] "degree"  ASDM
 SG_ zipy_serialized_data_655_MFR : 480|32@1- (0.1,0) [-102.4|429496729.5] "degree"  ASDM

BO_ 345 MB79_DETECTIONS_41_MFR: 64 FLRB
 SG_ zipy_serialized_data_656_MFR : 0|32@1- (0.1,0) [-102.4|429496729.5] "degree"  ASDM
 SG_ zipy_serialized_data_657_MFR : 32|32@1- (0.1,0) [-102.4|429496729.5] "degree"  ASDM
 SG_ zipy_serialized_data_658_MFR : 64|32@1- (0.1,0) [-102.4|429496729.5] "degree"  ASDM
 SG_ zipy_serialized_data_659_MFR : 96|32@1- (0.1,0) [-102.4|429496729.5] "degree"  ASDM
 SG_ zipy_serialized_data_660_MFR : 128|32@1- (0.1,0) [-102.4|429496729.5] "degree"  ASDM
 SG_ zipy_serialized_data_661_MFR : 160|32@1- (0.1,0) [-102.4|429496729.5] "degree"  ASDM
 SG_ zipy_serialized_data_662_MFR : 192|32@1- (0.1,0) [-102.4|429496729.5] "degree"  ASDM
 SG_ zipy_serialized_data_663_MFR : 224|32@1- (0.1,0) [-102.4|429496729.5] "degree"  ASDM
 SG_ zipy_serialized_data_664_MFR : 256|32@1- (0.1,0) [-102.4|429496729.5] "degree"  ASDM
 SG_ zipy_serialized_data_665_MFR : 288|32@1- (0.1,0) [-102.4|429496729.5] "degree"  ASDM
 SG_ zipy_serialized_data_666_MFR : 320|32@1- (0.1,0) [-102.4|429496729.5] "degree"  ASDM
 SG_ zipy_serialized_data_667_MFR : 352|32@1- (0.1,0) [-102.4|429496729.5] "degree"  ASDM
 SG_ zipy_serialized_data_668_MFR : 384|32@1- (0.1,0) [-102.4|429496729.5] "degree"  ASDM
 SG_ zipy_serialized_data_669_MFR : 416|32@1- (0.1,0) [-102.4|429496729.5] "degree"  ASDM
 SG_ zipy_serialized_data_670_MFR : 448|32@1- (0.1,0) [-102.4|429496729.5] "degree"  ASDM
 SG_ zipy_serialized_data_671_MFR : 480|32@1- (0.1,0) [-102.4|429496729.5] "degree"  ASDM

BO_ 346 MB79_DETECTIONS_42_MFR: 64 FLRB
 SG_ zipy_serialized_data_672_MFR : 0|32@1- (0.1,0) [-102.4|429496729.5] "degree"  ASDM
 SG_ zipy_serialized_data_673_MFR : 32|32@1- (0.1,0) [-102.4|429496729.5] "degree"  ASDM
 SG_ zipy_serialized_data_674_MFR : 64|32@1- (0.1,0) [-102.4|429496729.5] "degree"  ASDM
 SG_ zipy_serialized_data_675_MFR : 96|32@1- (0.1,0) [-102.4|429496729.5] "degree"  ASDM
 SG_ zipy_serialized_data_676_MFR : 128|32@1- (0.1,0) [-102.4|429496729.5] "degree"  ASDM
 SG_ zipy_serialized_data_677_MFR : 160|32@1- (0.1,0) [-102.4|429496729.5] "degree"  ASDM
 SG_ zipy_serialized_data_678_MFR : 192|32@1- (0.1,0) [-102.4|429496729.5] "degree"  ASDM
 SG_ zipy_serialized_data_679_MFR : 224|32@1- (0.1,0) [-102.4|429496729.5] "degree"  ASDM
 SG_ zipy_serialized_data_680_MFR : 256|32@1- (0.1,0) [-102.4|429496729.5] "degree"  ASDM
 SG_ zipy_serialized_data_681_MFR : 288|32@1- (0.1,0) [-102.4|429496729.5] "degree"  ASDM
 SG_ zipy_serialized_data_682_MFR : 320|32@1- (0.1,0) [-102.4|429496729.5] "degree"  ASDM
 SG_ zipy_serialized_data_683_MFR : 352|32@1- (0.1,0) [-102.4|429496729.5] "degree"  ASDM
 SG_ zipy_serialized_data_684_MFR : 384|32@1- (0.1,0) [-102.4|429496729.5] "degree"  ASDM
 SG_ zipy_serialized_data_685_MFR : 416|32@1- (0.1,0) [-102.4|429496729.5] "degree"  ASDM
 SG_ zipy_serialized_data_686_MFR : 448|32@1- (0.1,0) [-102.4|429496729.5] "degree"  ASDM
 SG_ zipy_serialized_data_687_MFR : 480|32@1- (0.1,0) [-102.4|429496729.5] "degree"  ASDM

BO_ 347 MB79_DETECTIONS_43_MFR: 64 FLRB
 SG_ zipy_serialized_data_688_MFR : 0|32@1- (0.1,0) [-102.4|429496729.5] "degree"  ASDM
 SG_ zipy_serialized_data_689_MFR : 32|32@1- (0.1,0) [-102.4|429496729.5] "degree"  ASDM
 SG_ zipy_serialized_data_690_MFR : 64|32@1- (0.1,0) [-102.4|429496729.5] "degree"  ASDM
 SG_ zipy_serialized_data_691_MFR : 96|32@1- (0.1,0) [-102.4|429496729.5] "degree"  ASDM
 SG_ zipy_serialized_data_692_MFR : 128|32@1- (0.1,0) [-102.4|429496729.5] "degree"  ASDM
 SG_ zipy_serialized_data_693_MFR : 160|32@1- (0.1,0) [-102.4|429496729.5] "degree"  ASDM
 SG_ zipy_serialized_data_694_MFR : 192|32@1- (0.1,0) [-102.4|429496729.5] "degree"  ASDM
 SG_ zipy_serialized_data_695_MFR : 224|32@1- (0.1,0) [-102.4|429496729.5] "degree"  ASDM
 SG_ zipy_serialized_data_696_MFR : 256|32@1- (0.1,0) [-102.4|429496729.5] "degree"  ASDM
 SG_ zipy_serialized_data_697_MFR : 288|32@1- (0.1,0) [-102.4|429496729.5] "degree"  ASDM
 SG_ zipy_serialized_data_698_MFR : 320|32@1- (0.1,0) [-102.4|429496729.5] "degree"  ASDM
 SG_ zipy_serialized_data_699_MFR : 352|32@1- (0.1,0) [-102.4|429496729.5] "degree"  ASDM
 SG_ zipy_serialized_data_700_MFR : 384|32@1- (0.1,0) [-102.4|429496729.5] "degree"  ASDM
 SG_ zipy_serialized_data_701_MFR : 416|32@1- (0.1,0) [-102.4|429496729.5] "degree"  ASDM
 SG_ zipy_serialized_data_702_MFR : 448|32@1- (0.1,0) [-102.4|429496729.5] "degree"  ASDM
 SG_ zipy_serialized_data_703_MFR : 480|32@1- (0.1,0) [-102.4|429496729.5] "degree"  ASDM

BO_ 348 MB79_DETECTIONS_44_MFR: 64 FLRB
 SG_ zipy_serialized_data_704_MFR : 0|32@1- (0.1,0) [-102.4|429496729.5] "degree"  ASDM
 SG_ zipy_serialized_data_705_MFR : 32|32@1- (0.1,0) [-102.4|429496729.5] "degree"  ASDM
 SG_ zipy_serialized_data_706_MFR : 64|32@1- (0.1,0) [-102.4|429496729.5] "degree"  ASDM
 SG_ zipy_serialized_data_707_MFR : 96|32@1- (0.1,0) [-102.4|429496729.5] "degree"  ASDM
 SG_ zipy_serialized_data_708_MFR : 128|32@1- (0.1,0) [-102.4|429496729.5] "degree"  ASDM
 SG_ zipy_serialized_data_709_MFR : 160|32@1- (0.1,0) [-102.4|429496729.5] "degree"  ASDM
 SG_ zipy_serialized_data_710_MFR : 192|32@1- (0.1,0) [-102.4|429496729.5] "degree"  ASDM
 SG_ zipy_serialized_data_711_MFR : 224|32@1- (0.1,0) [-102.4|429496729.5] "degree"  ASDM
 SG_ zipy_serialized_data_712_MFR : 256|32@1- (0.1,0) [-102.4|429496729.5] "degree"  ASDM
 SG_ zipy_serialized_data_713_MFR : 288|32@1- (0.1,0) [-102.4|429496729.5] "degree"  ASDM
 SG_ zipy_serialized_data_714_MFR : 320|32@1- (0.1,0) [-102.4|429496729.5] "degree"  ASDM
 SG_ zipy_serialized_data_715_MFR : 352|32@1- (0.1,0) [-102.4|429496729.5] "degree"  ASDM
 SG_ zipy_serialized_data_716_MFR : 384|32@1- (0.1,0) [-102.4|429496729.5] "degree"  ASDM
 SG_ zipy_serialized_data_717_MFR : 416|32@1- (0.1,0) [-102.4|429496729.5] "degree"  ASDM
 SG_ zipy_serialized_data_718_MFR : 448|32@1- (0.1,0) [-102.4|429496729.5] "degree"  ASDM
 SG_ zipy_serialized_data_719_MFR : 480|32@1- (0.1,0) [-102.4|429496729.5] "degree"  ASDM

BO_ 349 MB79_DETECTIONS_45_MFR: 64 FLRB
 SG_ zipy_serialized_data_720_MFR : 0|32@1- (0.1,0) [-102.4|429496729.5] "degree"  ASDM
 SG_ zipy_serialized_data_721_MFR : 32|32@1- (0.1,0) [-102.4|429496729.5] "degree"  ASDM
 SG_ zipy_serialized_data_722_MFR : 64|32@1- (0.1,0) [-102.4|429496729.5] "degree"  ASDM
 SG_ zipy_serialized_data_723_MFR : 96|32@1- (0.1,0) [-102.4|429496729.5] "degree"  ASDM
 SG_ zipy_serialized_data_724_MFR : 128|32@1- (0.1,0) [-102.4|429496729.5] "degree"  ASDM
 SG_ zipy_serialized_data_725_MFR : 160|32@1- (0.1,0) [-102.4|429496729.5] "degree"  ASDM
 SG_ zipy_serialized_data_726_MFR : 192|32@1- (0.1,0) [-102.4|429496729.5] "degree"  ASDM
 SG_ zipy_serialized_data_727_MFR : 224|32@1- (0.1,0) [-102.4|429496729.5] "degree"  ASDM
 SG_ zipy_serialized_data_728_MFR : 256|32@1- (0.1,0) [-102.4|429496729.5] "degree"  ASDM
 SG_ zipy_serialized_data_729_MFR : 288|32@1- (0.1,0) [-102.4|429496729.5] "degree"  ASDM
 SG_ zipy_serialized_data_730_MFR : 320|32@1- (0.1,0) [-102.4|429496729.5] "degree"  ASDM
 SG_ zipy_serialized_data_731_MFR : 352|32@1- (0.1,0) [-102.4|429496729.5] "degree"  ASDM
 SG_ zipy_serialized_data_732_MFR : 384|32@1- (0.1,0) [-102.4|429496729.5] "degree"  ASDM
 SG_ zipy_serialized_data_733_MFR : 416|32@1- (0.1,0) [-102.4|429496729.5] "degree"  ASDM
 SG_ zipy_serialized_data_734_MFR : 448|32@1- (0.1,0) [-102.4|429496729.5] "degree"  ASDM
 SG_ zipy_serialized_data_735_MFR : 480|32@1- (0.1,0) [-102.4|429496729.5] "degree"  ASDM

BO_ 350 MB79_DETECTIONS_46_MFR: 64 FLRB
 SG_ zipy_serialized_data_736_MFR : 0|32@1- (0.1,0) [-102.4|429496729.5] "degree"  ASDM
 SG_ zipy_serialized_data_737_MFR : 32|32@1- (0.1,0) [-102.4|429496729.5] "degree"  ASDM
 SG_ zipy_serialized_data_738_MFR : 64|32@1- (0.1,0) [-102.4|429496729.5] "degree"  ASDM
 SG_ zipy_serialized_data_739_MFR : 96|32@1- (0.1,0) [-102.4|429496729.5] "degree"  ASDM
 SG_ zipy_serialized_data_740_MFR : 128|32@1- (0.1,0) [-102.4|429496729.5] "degree"  ASDM
 SG_ zipy_serialized_data_741_MFR : 160|32@1- (0.1,0) [-102.4|429496729.5] "degree"  ASDM
 SG_ zipy_serialized_data_742_MFR : 192|32@1- (0.1,0) [-102.4|429496729.5] "degree"  ASDM
 SG_ zipy_serialized_data_743_MFR : 224|32@1- (0.1,0) [-102.4|429496729.5] "degree"  ASDM
 SG_ zipy_serialized_data_744_MFR : 256|32@1- (0.1,0) [-102.4|429496729.5] "degree"  ASDM
 SG_ zipy_serialized_data_745_MFR : 288|32@1- (0.1,0) [-102.4|429496729.5] "degree"  ASDM
 SG_ zipy_serialized_data_746_MFR : 320|32@1- (0.1,0) [-102.4|429496729.5] "degree"  ASDM
 SG_ zipy_serialized_data_747_MFR : 352|32@1- (0.1,0) [-102.4|429496729.5] "degree"  ASDM
 SG_ zipy_serialized_data_748_MFR : 384|32@1- (0.1,0) [-102.4|429496729.5] "degree"  ASDM
 SG_ zipy_serialized_data_749_MFR : 416|32@1- (0.1,0) [-102.4|429496729.5] "degree"  ASDM
 SG_ zipy_serialized_data_750_MFR : 448|32@1- (0.1,0) [-102.4|429496729.5] "degree"  ASDM
 SG_ zipy_serialized_data_751_MFR : 480|32@1- (0.1,0) [-102.4|429496729.5] "degree"  ASDM

BO_ 351 MB79_DETECTIONS_47_MFR: 64 FLRB
 SG_ zipy_serialized_data_752_MFR : 0|32@1- (0.1,0) [-102.4|429496729.5] "degree"  ASDM
 SG_ zipy_serialized_data_753_MFR : 32|32@1- (0.1,0) [-102.4|429496729.5] "degree"  ASDM
 SG_ zipy_serialized_data_754_MFR : 64|32@1- (0.1,0) [-102.4|429496729.5] "degree"  ASDM
 SG_ zipy_serialized_data_755_MFR : 96|32@1- (0.1,0) [-102.4|429496729.5] "degree"  ASDM
 SG_ zipy_serialized_data_756_MFR : 128|32@1- (0.1,0) [-102.4|429496729.5] "degree"  ASDM
 SG_ zipy_serialized_data_757_MFR : 160|32@1- (0.1,0) [-102.4|429496729.5] "degree"  ASDM
 SG_ zipy_serialized_data_758_MFR : 192|32@1- (0.1,0) [-102.4|429496729.5] "degree"  ASDM
 SG_ zipy_serialized_data_759_MFR : 224|32@1- (0.1,0) [-102.4|429496729.5] "degree"  ASDM
 SG_ zipy_serialized_data_760_MFR : 256|32@1- (0.1,0) [-102.4|429496729.5] "degree"  ASDM
 SG_ zipy_serialized_data_761_MFR : 288|32@1- (0.1,0) [-102.4|429496729.5] "degree"  ASDM
 SG_ zipy_serialized_data_762_MFR : 320|32@1- (0.1,0) [-102.4|429496729.5] "degree"  ASDM
 SG_ zipy_serialized_data_763_MFR : 352|32@1- (0.1,0) [-102.4|429496729.5] "degree"  ASDM
 SG_ zipy_serialized_data_764_MFR : 384|32@1- (0.1,0) [-102.4|429496729.5] "degree"  ASDM
 SG_ zipy_serialized_data_765_MFR : 416|32@1- (0.1,0) [-102.4|429496729.5] "degree"  ASDM
 SG_ zipy_serialized_data_766_MFR : 448|32@1- (0.1,0) [-102.4|429496729.5] "degree"  ASDM
 SG_ zipy_serialized_data_767_MFR : 480|32@1- (0.1,0) [-102.4|429496729.5] "degree"  ASDM

BO_ 352 MB79_DETECTIONS_48_MFR: 64 FLRB
 SG_ zipy_serialized_data_768_MFR : 0|32@1- (0.1,0) [-102.4|429496729.5] "degree"  ASDM
 SG_ zipy_serialized_data_769_MFR : 32|32@1- (0.1,0) [-102.4|429496729.5] "degree"  ASDM
 SG_ zipy_serialized_data_770_MFR : 64|32@1- (0.1,0) [-102.4|429496729.5] "degree"  ASDM
 SG_ zipy_serialized_data_771_MFR : 96|32@1- (0.1,0) [-102.4|429496729.5] "degree"  ASDM
 SG_ zipy_serialized_data_772_MFR : 128|32@1- (0.1,0) [-102.4|429496729.5] "degree"  ASDM
 SG_ zipy_serialized_data_773_MFR : 160|32@1- (0.1,0) [-102.4|429496729.5] "degree"  ASDM
 SG_ zipy_serialized_data_774_MFR : 192|32@1- (0.1,0) [-102.4|429496729.5] "degree"  ASDM
 SG_ zipy_serialized_data_775_MFR : 224|32@1- (0.1,0) [-102.4|429496729.5] "degree"  ASDM
 SG_ zipy_serialized_data_776_MFR : 256|32@1- (0.1,0) [-102.4|429496729.5] "degree"  ASDM
 SG_ zipy_serialized_data_777_MFR : 288|32@1- (0.1,0) [-102.4|429496729.5] "degree"  ASDM
 SG_ zipy_serialized_data_778_MFR : 320|32@1- (0.1,0) [-102.4|429496729.5] "degree"  ASDM
 SG_ zipy_serialized_data_779_MFR : 352|32@1- (0.1,0) [-102.4|429496729.5] "degree"  ASDM
 SG_ zipy_serialized_data_780_MFR : 384|32@1- (0.1,0) [-102.4|429496729.5] "degree"  ASDM
 SG_ zipy_serialized_data_781_MFR : 416|32@1- (0.1,0) [-102.4|429496729.5] "degree"  ASDM
 SG_ zipy_serialized_data_782_MFR : 448|32@1- (0.1,0) [-102.4|429496729.5] "degree"  ASDM
 SG_ zipy_serialized_data_783_MFR : 480|32@1- (0.1,0) [-102.4|429496729.5] "degree"  ASDM

BO_ 353 MB79_DETECTIONS_49_MFR: 64 FLRB
 SG_ zipy_serialized_data_784_MFR : 0|32@1- (0.1,0) [-102.4|429496729.5] "degree"  ASDM
 SG_ zipy_serialized_data_785_MFR : 32|32@1- (0.1,0) [-102.4|429496729.5] "degree"  ASDM
 SG_ zipy_serialized_data_786_MFR : 64|32@1- (0.1,0) [-102.4|429496729.5] "degree"  ASDM
 SG_ zipy_serialized_data_787_MFR : 96|32@1- (0.1,0) [-102.4|429496729.5] "degree"  ASDM
 SG_ zipy_serialized_data_788_MFR : 128|32@1- (0.1,0) [-102.4|429496729.5] "degree"  ASDM
 SG_ zipy_serialized_data_789_MFR : 160|32@1- (0.1,0) [-102.4|429496729.5] "degree"  ASDM
 SG_ zipy_serialized_data_790_MFR : 192|32@1- (0.1,0) [-102.4|429496729.5] "degree"  ASDM
 SG_ zipy_serialized_data_791_MFR : 224|32@1- (0.1,0) [-102.4|429496729.5] "degree"  ASDM
 SG_ zipy_serialized_data_792_MFR : 256|32@1- (0.1,0) [-102.4|429496729.5] "degree"  ASDM
 SG_ zipy_serialized_data_793_MFR : 288|32@1- (0.1,0) [-102.4|429496729.5] "degree"  ASDM
 SG_ zipy_serialized_data_794_MFR : 320|32@1- (0.1,0) [-102.4|429496729.5] "degree"  ASDM
 SG_ zipy_serialized_data_795_MFR : 352|32@1- (0.1,0) [-102.4|429496729.5] "degree"  ASDM
 SG_ zipy_serialized_data_796_MFR : 384|32@1- (0.1,0) [-102.4|429496729.5] "degree"  ASDM
 SG_ zipy_serialized_data_797_MFR : 416|32@1- (0.1,0) [-102.4|429496729.5] "degree"  ASDM
 SG_ zipy_serialized_data_798_MFR : 448|32@1- (0.1,0) [-102.4|429496729.5] "degree"  ASDM
 SG_ zipy_serialized_data_799_MFR : 480|32@1- (0.1,0) [-102.4|429496729.5] "degree"  ASDM

BO_ 354 MB79_DETECTIONS_50_MFR: 64 FLRB
 SG_ zipy_serialized_data_800_MFR : 0|32@1- (0.1,0) [-102.4|429496729.5] "degree"  ASDM
 SG_ zipy_serialized_data_801_MFR : 32|32@1- (0.1,0) [-102.4|429496729.5] "degree"  ASDM
 SG_ zipy_serialized_data_802_MFR : 64|32@1- (0.1,0) [-102.4|429496729.5] "degree"  ASDM
 SG_ zipy_serialized_data_803_MFR : 96|32@1- (0.1,0) [-102.4|429496729.5] "degree"  ASDM
 SG_ zipy_serialized_data_804_MFR : 128|32@1- (0.1,0) [-102.4|429496729.5] "degree"  ASDM
 SG_ zipy_serialized_data_805_MFR : 160|32@1- (0.1,0) [-102.4|429496729.5] "degree"  ASDM
 SG_ zipy_serialized_data_806_MFR : 192|32@1- (0.1,0) [-102.4|429496729.5] "degree"  ASDM
 SG_ zipy_serialized_data_807_MFR : 224|32@1- (0.1,0) [-102.4|429496729.5] "degree"  ASDM
 SG_ zipy_serialized_data_808_MFR : 256|32@1- (0.1,0) [-102.4|429496729.5] "degree"  ASDM
 SG_ zipy_serialized_data_809_MFR : 288|32@1- (0.1,0) [-102.4|429496729.5] "degree"  ASDM
 SG_ zipy_serialized_data_810_MFR : 320|32@1- (0.1,0) [-102.4|429496729.5] "degree"  ASDM
 SG_ zipy_serialized_data_811_MFR : 352|32@1- (0.1,0) [-102.4|429496729.5] "degree"  ASDM
 SG_ zipy_serialized_data_812_MFR : 384|32@1- (0.1,0) [-102.4|429496729.5] "degree"  ASDM
 SG_ zipy_serialized_data_813_MFR : 416|32@1- (0.1,0) [-102.4|429496729.5] "degree"  ASDM
 SG_ zipy_serialized_data_814_MFR : 448|32@1- (0.1,0) [-102.4|429496729.5] "degree"  ASDM
 SG_ zipy_serialized_data_815_MFR : 480|32@1- (0.1,0) [-102.4|429496729.5] "degree"  ASDM

BO_ 355 MB79_DETECTIONS_51_MFR: 64 FLRB
 SG_ zipy_serialized_data_816_MFR : 0|32@1- (0.1,0) [-102.4|429496729.5] "degree"  ASDM
 SG_ zipy_serialized_data_817_MFR : 32|32@1- (0.1,0) [-102.4|429496729.5] "degree"  ASDM
 SG_ zipy_serialized_data_818_MFR : 64|32@1- (0.1,0) [-102.4|429496729.5] "degree"  ASDM
 SG_ zipy_serialized_data_819_MFR : 96|32@1- (0.1,0) [-102.4|429496729.5] "degree"  ASDM
 SG_ zipy_serialized_data_820_MFR : 128|32@1- (0.1,0) [-102.4|429496729.5] "degree"  ASDM
 SG_ zipy_serialized_data_821_MFR : 160|32@1- (0.1,0) [-102.4|429496729.5] "degree"  ASDM
 SG_ zipy_serialized_data_822_MFR : 192|32@1- (0.1,0) [-102.4|429496729.5] "degree"  ASDM
 SG_ zipy_serialized_data_823_MFR : 224|32@1- (0.1,0) [-102.4|429496729.5] "degree"  ASDM
 SG_ zipy_serialized_data_824_MFR : 256|32@1- (0.1,0) [-102.4|429496729.5] "degree"  ASDM
 SG_ zipy_serialized_data_825_MFR : 288|32@1- (0.1,0) [-102.4|429496729.5] "degree"  ASDM
 SG_ zipy_serialized_data_826_MFR : 320|32@1- (0.1,0) [-102.4|429496729.5] "degree"  ASDM
 SG_ zipy_serialized_data_827_MFR : 352|32@1- (0.1,0) [-102.4|429496729.5] "degree"  ASDM
 SG_ zipy_serialized_data_828_MFR : 384|32@1- (0.1,0) [-102.4|429496729.5] "degree"  ASDM
 SG_ zipy_serialized_data_829_MFR : 416|32@1- (0.1,0) [-102.4|429496729.5] "degree"  ASDM
 SG_ zipy_serialized_data_830_MFR : 448|32@1- (0.1,0) [-102.4|429496729.5] "degree"  ASDM
 SG_ zipy_serialized_data_831_MFR : 480|32@1- (0.1,0) [-102.4|429496729.5] "degree"  ASDM

BO_ 356 MB79_DETECTIONS_52_MFR: 64 FLRB
 SG_ zipy_serialized_data_832_MFR : 0|32@1- (0.1,0) [-102.4|429496729.5] "degree"  ASDM
 SG_ zipy_serialized_data_833_MFR : 32|32@1- (0.1,0) [-102.4|429496729.5] "degree"  ASDM
 SG_ zipy_serialized_data_834_MFR : 64|32@1- (0.1,0) [-102.4|429496729.5] "degree"  ASDM
 SG_ zipy_serialized_data_835_MFR : 96|32@1- (0.1,0) [-102.4|429496729.5] "degree"  ASDM
 SG_ zipy_serialized_data_836_MFR : 128|32@1- (0.1,0) [-102.4|429496729.5] "degree"  ASDM
 SG_ zipy_serialized_data_837_MFR : 160|32@1- (0.1,0) [-102.4|429496729.5] "degree"  ASDM
 SG_ zipy_serialized_data_838_MFR : 192|32@1- (0.1,0) [-102.4|429496729.5] "degree"  ASDM
 SG_ zipy_serialized_data_839_MFR : 224|32@1- (0.1,0) [-102.4|429496729.5] "degree"  ASDM
 SG_ zipy_serialized_data_840_MFR : 256|32@1- (0.1,0) [-102.4|429496729.5] "degree"  ASDM
 SG_ zipy_serialized_data_841_MFR : 288|32@1- (0.1,0) [-102.4|429496729.5] "degree"  ASDM
 SG_ zipy_serialized_data_842_MFR : 320|32@1- (0.1,0) [-102.4|429496729.5] "degree"  ASDM
 SG_ zipy_serialized_data_843_MFR : 352|32@1- (0.1,0) [-102.4|429496729.5] "degree"  ASDM
 SG_ zipy_serialized_data_844_MFR : 384|32@1- (0.1,0) [-102.4|429496729.5] "degree"  ASDM
 SG_ zipy_serialized_data_845_MFR : 416|32@1- (0.1,0) [-102.4|429496729.5] "degree"  ASDM
 SG_ zipy_serialized_data_846_MFR : 448|32@1- (0.1,0) [-102.4|429496729.5] "degree"  ASDM
 SG_ zipy_serialized_data_847_MFR : 480|32@1- (0.1,0) [-102.4|429496729.5] "degree"  ASDM

BO_ 357 MB79_DETECTIONS_53_MFR: 64 FLRB
 SG_ zipy_serialized_data_848_MFR : 0|32@1- (0.1,0) [-102.4|429496729.5] "degree"  ASDM
 SG_ zipy_serialized_data_849_MFR : 32|32@1- (0.1,0) [-102.4|429496729.5] "degree"  ASDM
 SG_ zipy_serialized_data_850_MFR : 64|32@1- (0.1,0) [-102.4|429496729.5] "degree"  ASDM
 SG_ zipy_serialized_data_851_MFR : 96|32@1- (0.1,0) [-102.4|429496729.5] "degree"  ASDM
 SG_ zipy_serialized_data_852_MFR : 128|32@1- (0.1,0) [-102.4|429496729.5] "degree"  ASDM
 SG_ zipy_serialized_data_853_MFR : 160|32@1- (0.1,0) [-102.4|429496729.5] "degree"  ASDM
 SG_ zipy_serialized_data_854_MFR : 192|32@1- (0.1,0) [-102.4|429496729.5] "degree"  ASDM
 SG_ zipy_serialized_data_855_MFR : 224|32@1- (0.1,0) [-102.4|429496729.5] "degree"  ASDM
 SG_ zipy_serialized_data_856_MFR : 256|32@1- (0.1,0) [-102.4|429496729.5] "degree"  ASDM
 SG_ zipy_serialized_data_857_MFR : 288|32@1- (0.1,0) [-102.4|429496729.5] "degree"  ASDM
 SG_ zipy_serialized_data_858_MFR : 320|32@1- (0.1,0) [-102.4|429496729.5] "degree"  ASDM
 SG_ zipy_serialized_data_859_MFR : 352|32@1- (0.1,0) [-102.4|429496729.5] "degree"  ASDM
 SG_ zipy_serialized_data_860_MFR : 384|32@1- (0.1,0) [-102.4|429496729.5] "degree"  ASDM
 SG_ zipy_serialized_data_861_MFR : 416|32@1- (0.1,0) [-102.4|429496729.5] "degree"  ASDM
 SG_ zipy_serialized_data_862_MFR : 448|32@1- (0.1,0) [-102.4|429496729.5] "degree"  ASDM
 SG_ zipy_serialized_data_863_MFR : 480|32@1- (0.1,0) [-102.4|429496729.5] "degree"  ASDM

BO_ 358 MB79_DETECTIONS_54_MFR: 64 FLRB
 SG_ zipy_serialized_data_864_MFR : 0|32@1- (0.1,0) [-102.4|429496729.5] "degree"  ASDM
 SG_ zipy_serialized_data_865_MFR : 32|32@1- (0.1,0) [-102.4|429496729.5] "degree"  ASDM
 SG_ zipy_serialized_data_866_MFR : 64|32@1- (0.1,0) [-102.4|429496729.5] "degree"  ASDM
 SG_ zipy_serialized_data_867_MFR : 96|32@1- (0.1,0) [-102.4|429496729.5] "degree"  ASDM
 SG_ zipy_serialized_data_868_MFR : 128|32@1- (0.1,0) [-102.4|429496729.5] "degree"  ASDM
 SG_ zipy_serialized_data_869_MFR : 160|32@1- (0.1,0) [-102.4|429496729.5] "degree"  ASDM
 SG_ zipy_serialized_data_870_MFR : 192|32@1- (0.1,0) [-102.4|429496729.5] "degree"  ASDM
 SG_ zipy_serialized_data_871_MFR : 224|32@1- (0.1,0) [-102.4|429496729.5] "degree"  ASDM
 SG_ zipy_serialized_data_872_MFR : 256|32@1- (0.1,0) [-102.4|429496729.5] "degree"  ASDM
 SG_ zipy_serialized_data_873_MFR : 288|32@1- (0.1,0) [-102.4|429496729.5] "degree"  ASDM
 SG_ zipy_serialized_data_874_MFR : 320|32@1- (0.1,0) [-102.4|429496729.5] "degree"  ASDM
 SG_ zipy_serialized_data_875_MFR : 352|32@1- (0.1,0) [-102.4|429496729.5] "degree"  ASDM
 SG_ zipy_serialized_data_876_MFR : 384|32@1- (0.1,0) [-102.4|429496729.5] "degree"  ASDM
 SG_ zipy_serialized_data_877_MFR : 416|32@1- (0.1,0) [-102.4|429496729.5] "degree"  ASDM
 SG_ zipy_serialized_data_878_MFR : 448|32@1- (0.1,0) [-102.4|429496729.5] "degree"  ASDM
 SG_ zipy_serialized_data_879_MFR : 480|32@1- (0.1,0) [-102.4|429496729.5] "degree"  ASDM

BO_ 359 MB79_DETECTIONS_55_MFR: 64 FLRB
 SG_ zipy_serialized_data_880_MFR : 0|32@1- (0.1,0) [-102.4|429496729.5] "degree"  ASDM
 SG_ zipy_serialized_data_881_MFR : 32|32@1- (0.1,0) [-102.4|429496729.5] "degree"  ASDM
 SG_ zipy_serialized_data_882_MFR : 64|32@1- (0.1,0) [-102.4|429496729.5] "degree"  ASDM
 SG_ zipy_serialized_data_883_MFR : 96|32@1- (0.1,0) [-102.4|429496729.5] "degree"  ASDM
 SG_ zipy_serialized_data_884_MFR : 128|32@1- (0.1,0) [-102.4|429496729.5] "degree"  ASDM
 SG_ zipy_serialized_data_885_MFR : 160|32@1- (0.1,0) [-102.4|429496729.5] "degree"  ASDM
 SG_ zipy_serialized_data_886_MFR : 192|32@1- (0.1,0) [-102.4|429496729.5] "degree"  ASDM
 SG_ zipy_serialized_data_887_MFR : 224|32@1- (0.1,0) [-102.4|429496729.5] "degree"  ASDM
 SG_ zipy_serialized_data_888_MFR : 256|32@1- (0.1,0) [-102.4|429496729.5] "degree"  ASDM
 SG_ zipy_serialized_data_889_MFR : 288|32@1- (0.1,0) [-102.4|429496729.5] "degree"  ASDM
 SG_ zipy_serialized_data_890_MFR : 320|32@1- (0.1,0) [-102.4|429496729.5] "degree"  ASDM
 SG_ zipy_serialized_data_891_MFR : 352|32@1- (0.1,0) [-102.4|429496729.5] "degree"  ASDM
 SG_ zipy_serialized_data_892_MFR : 384|32@1- (0.1,0) [-102.4|429496729.5] "degree"  ASDM
 SG_ zipy_serialized_data_893_MFR : 416|32@1- (0.1,0) [-102.4|429496729.5] "degree"  ASDM
 SG_ zipy_serialized_data_894_MFR : 448|32@1- (0.1,0) [-102.4|429496729.5] "degree"  ASDM
 SG_ zipy_serialized_data_895_MFR : 480|32@1- (0.1,0) [-102.4|429496729.5] "degree"  ASDM

BO_ 769 MB79_VEHICLE_DATA: 12 ASDM
 SG_ VehiclePower_Gear_ASDM : 40|4@1+ (1,0) [0|15] ""  FLRB
 SG_ HostVel_ASDM : 7|16@0- (1,0) [-2000|14000] "cm/s"  FLRB
 SG_ SteeringAngle_ASDM : 23|16@0- (1,0) [-800|800] "1/10 degree"  FLRB
 SG_ Reserved_2_bytes_ASDM : 39|12@0+ (1,0) [0|65535] "N/A"  FLRB
 SG_ HostYaw_ASDM : 55|16@0- (1,0) [-2048|2047] "1/1024 rad/sec"  FLRB
 SG_ VehicleType_ASDM : 71|8@0+ (1,0) [0|255] "N/A"  FLRB
 SG_ Clock_VehicleData_ASDM : 79|4@0+ (1,0) [0|15] "N/A"  FLRB
 SG_ Reserved_2bit_ASDM : 75|2@0+ (1,0) [0|3] "N/A"  FLRB
 SG_ HostTrailerAttached_ASDM : 73|1@0+ (1,0) [0|1] "N/A"  FLRB
 SG_ HostDrivingForward_ASDM : 72|1@0+ (1,0) [0|1] "N/A"  FLRB
 SG_ CRC_VehicleData_ASDM : 87|8@0+ (1,0) [0|255] "N/A"  FLRB
 SG_ HostGear_ASDM : 95|8@0+ (1,0) [0|15] "N/A"  FLRB

BO_ 784 MB79_PROCESSING_PROFIL_MFR: 64 FLRB
 SG_ Function_ID_0_MFR : 7|8@0+ (1,0) [0|255] ""  ASDM
 SG_ MaxExecTime_0_MFR : 15|16@0+ (1,0) [0|65535] ""  ASDM
 SG_ MinExecTime_0_MFR : 31|16@0+ (1,0) [0|65535] ""  ASDM
 SG_ AvgExecTime_0_MFR : 47|16@0+ (1,0) [0|65535] ""  ASDM
 SG_ LatestStartTimeOffset_0_MFR : 63|16@0+ (1,0) [0|65535] ""  ASDM
 SG_ EarliestStartTimeOffset_0_MFR : 79|16@0+ (1,0) [0|65535] ""  ASDM
 SG_ AvgStartTimeOffset_0_MFR : 95|16@0+ (1,0) [0|65535] ""  ASDM
 SG_ Function_ID_1_MFR : 111|8@0+ (1,0) [0|255] ""  ASDM
 SG_ MaxExecTime_1_MFR : 119|16@0+ (1,0) [0|65535] ""  ASDM
 SG_ MinExecTime_1_MFR : 135|16@0+ (1,0) [0|65535] ""  ASDM
 SG_ AvgExecTime_1_MFR : 151|16@0+ (1,0) [0|65535] ""  ASDM
 SG_ LatestStartTimeOffset_1_MFR : 167|16@0+ (1,0) [0|65535] ""  ASDM
 SG_ EarliestStartTimeOffset_1_MFR : 183|16@0+ (1,0) [0|65535] ""  ASDM
 SG_ AvgStartTimeOffset_1_MFR : 199|16@0+ (1,0) [0|65535] ""  ASDM
 SG_ Function_ID_2_MFR : 215|8@0+ (1,0) [0|255] ""  ASDM
 SG_ MaxExecTime_2_MFR : 223|16@0+ (1,0) [0|65535] ""  ASDM
 SG_ MinExecTime_2_MFR : 239|16@0+ (1,0) [0|65535] ""  ASDM
 SG_ AvgExecTime_2_MFR : 255|16@0+ (1,0) [0|65535] ""  ASDM
 SG_ LatestStartTimeOffset_2_MFR : 271|16@0+ (1,0) [0|65535] ""  ASDM
 SG_ EarliestStartTimeOffset_2_MFR : 287|16@0+ (1,0) [0|65535] ""  ASDM
 SG_ AvgStartTimeOffset_2_MFR : 303|16@0+ (1,0) [0|65535] ""  ASDM
 SG_ Function_ID_3_MFR : 319|8@0+ (1,0) [0|255] ""  ASDM
 SG_ MaxExecTime_3_MFR : 327|16@0+ (1,0) [0|65535] ""  ASDM
 SG_ MinExecTime_3_MFR : 343|16@0+ (1,0) [0|65535] ""  ASDM
 SG_ AvgExecTime_3_MFR : 359|16@0+ (1,0) [0|65535] ""  ASDM
 SG_ LatestStartTimeOffset_3_MFR : 375|16@0+ (1,0) [0|65535] ""  ASDM
 SG_ EarliestStartTimeOffset_3_MFR : 391|16@0+ (1,0) [0|65535] ""  ASDM
 SG_ AvgStartTimeOffset_3_MFR : 407|16@0+ (1,0) [0|65535] ""  ASDM

BO_ 785 MB79_AUTOALIGN_RESULT_MFR: 4 FLRB
 SG_ AutoAlignment_ErrorType_MFR : 7|4@0+ (1,0) [0|15] "N/A"  ASDM
 SG_ AutoCalib_Status_MFR : 3|4@0+ (1,0) [0|15] "N/A"  ASDM

BO_ 786 MB79_VOLT_MONITORING_MFR: 24 FLRB
 SG_ voltage_VBAT_mv_MFR : 7|16@0+ (1,0) [0|65535] "mv"  ASDM
 SG_ Reserved_2bytes_1_MFR : 23|16@0+ (1,0) [0|65535] "mv"  ASDM
 SG_ Reserved_2bytes_2_MFR : 39|16@0+ (1,0) [0|65535] "mv"  ASDM
 SG_ Reserved_2bytes_3_MFR : 55|16@0+ (1,0) [0|65535] "mv"  ASDM
 SG_ Reserved_2bytes_4_MFR : 71|16@0+ (1,0) [0|65535] "mv"  ASDM
 SG_ Reserved_2bytes_5_MFR : 87|16@0+ (1,0) [0|65535] "mv"  ASDM
 SG_ Reserved_2bytes_6_MFR : 103|16@0+ (1,0) [0|65535] "mv"  ASDM
 SG_ Reserved_2bytes_7_MFR : 119|16@0+ (1,0) [0|65535] "mv"  ASDM
 SG_ voltage_SPOS1_mv_MFR : 135|16@0+ (1,0) [0|65535] "mv"  ASDM
 SG_ voltage_SPOS2_mv_MFR : 151|16@0+ (1,0) [0|65535] "mv"  ASDM
 SG_ Reserved_2bytes_8_MFR : 167|16@0+ (1,0) [0|65535] "mv"  ASDM

BO_ 787 MB79_TEMP_MONITORING_MFR: 32 FLRB
 SG_ Reserved_2_bytes_MFR : 7|16@0- (1,0) [0|65535] "N/A"  ASDM
 SG_ TEMP_RX2_SENS_MFR : 23|16@0- (1,0) [-256|255] "Celsius"  ASDM
 SG_ TSENSE2_MFR : 39|16@0- (1,0) [-256|255] "Celsius"  ASDM
 SG_ TEMP_RX3_SENS_MFR : 55|16@0- (1,0) [-256|255] "Celsius"  ASDM
 SG_ TEMP_RX1_SENS_MFR : 71|16@0- (1,0) [-256|255] "Celsius"  ASDM
 SG_ TEMP_RX0_SENS_MFR : 87|16@0- (1,0) [-256|255] "Celsius"  ASDM
 SG_ TSENSE1_MFR : 103|16@0- (1,0) [-256|255] "Celsius"  ASDM
 SG_ TSENSE0_MFR : 119|16@0- (1,0) [-256|255] "Celsius"  ASDM
 SG_ TEMP_TX2_SENS_MFR : 135|16@0- (1,0) [-256|255] "Celsius"  ASDM
 SG_ TEMP_TX1_SENS_MFR : 151|16@0- (1,0) [-256|255] "Celsius"  ASDM
 SG_ TEMP_TX0_SENS_MFR : 167|16@0- (1,0) [-256|255] "Celsius"  ASDM
 SG_ TEMP_DIG1_TX3_SENS_MFR : 183|16@0- (1,0) [-256|255] "Celsius"  ASDM
 SG_ MCU_Temp_Status_MFR : 199|4@0- (1,0) [0|15] "N/A"  ASDM
 SG_ reserved_MFR : 195|4@0- (1,0) [0|15] "N/A"  ASDM
 SG_ TEMP_PM_SENS_MFR : 207|16@0- (1,0) [-256|255] "Celsius"  ASDM

BO_ 788 MB79_VERSIONS_MFR: 64 FLRB
 SG_ PCANFD_Ver_App_MFR : 7|8@0+ (1,0) [0|255] "N/A"  ASDM
 SG_ PCANFD_Ver_Major_MFR : 15|8@0+ (1,0) [0|255] "N/A"  ASDM
 SG_ PCANFD_Ver_Minor_MFR : 23|8@0+ (1,0) [0|255] "N/A"  ASDM
 SG_ SW_PIPP_Ver_App_MFR : 31|16@0+ (1,0) [0|65535] "N/A"  ASDM
 SG_ SW_PIPP_Ver_Major_MFR : 47|16@0+ (1,0) [0|65535] "N/A"  ASDM
 SG_ SW_PIPP_Ver_Minor_MFR : 63|16@0+ (1,0) [0|65535] "N/A"  ASDM
 SG_ SW_RSP_Ver_App_MFR : 79|16@0+ (1,0) [0|65535] "N/A"  ASDM
 SG_ SW_RSP_Ver_Major_MFR : 95|16@0+ (1,0) [0|65535] "N/A"  ASDM
 SG_ SW_RSP_Ver_Minor_MFR : 111|16@0+ (1,0) [0|65535] "N/A"  ASDM
 SG_ SW_CAFS_Ver_App_MFR : 127|16@0+ (1,0) [0|65535] "N/A"  ASDM
 SG_ SW_CAFS_Ver_Major_MFR : 143|16@0+ (1,0) [0|65535] "N/A"  ASDM
 SG_ SW_CAFS_Ver_Minor_MFR : 159|16@0+ (1,0) [0|65535] "N/A"  ASDM
 SG_ CoresComProtcol_Ver_Major_MFR : 175|16@0+ (1,0) [0|65535] "N/A"  ASDM
 SG_ CoresComProtcol_Ver_Minor_MFR : 191|16@0+ (1,0) [0|65535] "N/A"  ASDM
 SG_ SW_Bootloader_Ver_App_MFR : 207|16@0+ (1,0) [0|65535] "N/A"  ASDM
 SG_ SW_Bootloader_Ver_Major_MFR : 223|16@0+ (1,0) [0|65535] "N/A"  ASDM
 SG_ SW_Bootloader_Ver_Minor_MFR : 239|16@0+ (1,0) [0|65535] "N/A"  ASDM
 SG_ LCP2_Data_Ver_Major_MFR : 255|8@0+ (1,0) [0|255] "N/A"  ASDM
 SG_ LCP2_Data_Ver_Minor_MFR : 263|8@0+ (1,0) [0|255] "N/A"  ASDM
 SG_ LCP2_Design_Ver_Major_MFR : 271|8@0+ (1,0) [0|255] "N/A"  ASDM
 SG_ LCP2_Design_Ver_Minor_MFR : 279|8@0+ (1,0) [0|255] "N/A"  ASDM
 SG_ LCP3_SR_Ver_Major_MFR : 287|16@0+ (1,0) [0|65535] "N/A"  ASDM
 SG_ LCP3_SR_Ver_Minor_MFR : 303|16@0+ (1,0) [0|65535] "N/A"  ASDM
 SG_ LCP3_SR_Ver_Build_MFR : 319|16@0+ (1,0) [0|65535] "N/A"  ASDM
 SG_ LCP3_LR_Ver_Major_MFR : 335|16@0+ (1,0) [0|65535] "N/A"  ASDM
 SG_ LCP3_LR_Ver_Minor_MFR : 351|16@0+ (1,0) [0|65535] "N/A"  ASDM
 SG_ LCP3_LR_Ver_Build_MFR : 367|16@0+ (1,0) [0|65535] "N/A"  ASDM
 SG_ MCU_Cut_Ver_Major_MFR : 383|16@0+ (1,0) [0|65535] "N/A"  ASDM
 SG_ MCU_Cut_Ver_Minor_MFR : 399|16@0+ (1,0) [0|65535] "N/A"  ASDM
 SG_ RF_chip_Ver_MFR : 415|16@0+ (1,0) [0|65535] "N/A"  ASDM
 SG_ Antenna_Ver_Major_MFR : 431|8@0+ (1,0) [0|255] "N/A"  ASDM
 SG_ Antenna_Ver_Minor_MFR : 439|8@0+ (1,0) [0|255] "N/A"  ASDM

BO_ 1280 MB79_LLHT_CONFIG_ERROR_MFR: 64 FLRB
 SG_ Testing_Mode_ID_MFR : 7|16@0+ (1,0) [0|65535] "N/A"  ASDM
 SG_ Testing_Mode_SubID_MFR : 23|8@0+ (1,0) [0|255] "N/A"  ASDM
 SG_ Testing_Mode_Param_0_MFR : 31|8@0+ (1,0) [0|255] "N/A"  ASDM
 SG_ Testing_Mode_Param_1_MFR : 39|8@0+ (1,0) [0|255] "N/A"  ASDM
 SG_ Testing_Mode_Param_2_MFR : 47|8@0+ (1,0) [0|255] "N/A"  ASDM
 SG_ Testing_Mode_Param_3_MFR : 55|8@0+ (1,0) [0|255] "N/A"  ASDM
 SG_ Testing_Mode_Param_4_MFR : 63|8@0+ (1,0) [0|255] "N/A"  ASDM
 SG_ Testing_Mode_Param_5_MFR : 71|8@0+ (1,0) [0|255] "N/A"  ASDM
 SG_ Testing_Mode_Param_6_MFR : 79|8@0+ (1,0) [0|255] "N/A"  ASDM
 SG_ Testing_Mode_Param_7_MFR : 87|8@0+ (1,0) [0|255] "N/A"  ASDM
 SG_ Testing_Mode_Param_8_MFR : 95|8@0+ (1,0) [0|255] "N/A"  ASDM
 SG_ Testing_Mode_Param_9_MFR : 103|8@0+ (1,0) [0|255] "N/A"  ASDM
 SG_ Testing_Mode_Param_10_MFR : 111|8@0+ (1,0) [0|255] "N/A"  ASDM
 SG_ Testing_Mode_Param_11_MFR : 119|8@0+ (1,0) [0|255] "N/A"  ASDM
 SG_ Testing_Mode_Param_12_MFR : 127|8@0+ (1,0) [0|255] "N/A"  ASDM
 SG_ Testing_Mode_Param_13_MFR : 135|8@0+ (1,0) [0|255] "N/A"  ASDM
 SG_ Testing_Mode_Param_14_MFR : 143|8@0+ (1,0) [0|255] "N/A"  ASDM
 SG_ Testing_Mode_Param_15_MFR : 151|8@0+ (1,0) [0|255] "N/A"  ASDM
 SG_ Testing_Mode_Param_16_MFR : 159|8@0+ (1,0) [0|255] "N/A"  ASDM
 SG_ Testing_Mode_Param_17_MFR : 167|8@0+ (1,0) [0|255] "N/A"  ASDM
 SG_ Testing_Mode_Param_18_MFR : 175|8@0+ (1,0) [0|255] "N/A"  ASDM
 SG_ Testing_Mode_Param_19_MFR : 183|8@0+ (1,0) [0|255] "N/A"  ASDM
 SG_ Testing_Mode_Param_20_MFR : 191|8@0+ (1,0) [0|255] "N/A"  ASDM
 SG_ Testing_Mode_Param_21_MFR : 199|8@0+ (1,0) [0|255] "N/A"  ASDM
 SG_ Testing_Mode_Param_22_MFR : 207|8@0+ (1,0) [0|255] "N/A"  ASDM
 SG_ Testing_Mode_Param_23_MFR : 215|8@0+ (1,0) [0|255] "N/A"  ASDM
 SG_ Testing_Mode_Param_24_MFR : 223|8@0+ (1,0) [0|255] "N/A"  ASDM
 SG_ Testing_Mode_Param_25_MFR : 231|8@0+ (1,0) [0|255] "N/A"  ASDM
 SG_ Testing_Mode_Param_26_MFR : 239|8@0+ (1,0) [0|255] "N/A"  ASDM
 SG_ Testing_Mode_Param_27_MFR : 247|8@0+ (1,0) [0|255] "N/A"  ASDM
 SG_ Testing_Mode_Param_28_MFR : 255|8@0+ (1,0) [0|255] "N/A"  ASDM
 SG_ Testing_Mode_Param_29_MFR : 263|8@0+ (1,0) [0|255] "N/A"  ASDM
 SG_ Testing_Mode_Param_30_MFR : 271|8@0+ (1,0) [0|255] "N/A"  ASDM
 SG_ Testing_Mode_Param_31_MFR : 279|8@0+ (1,0) [0|255] "N/A"  ASDM
 SG_ Testing_Mode_Param_32_MFR : 287|8@0+ (1,0) [0|255] "N/A"  ASDM
 SG_ Testing_Mode_Param_33_MFR : 295|8@0+ (1,0) [0|255] "N/A"  ASDM
 SG_ Testing_Mode_Param_34_MFR : 303|8@0+ (1,0) [0|255] "N/A"  ASDM
 SG_ Testing_Mode_Param_35_MFR : 311|8@0+ (1,0) [0|255] "N/A"  ASDM
 SG_ Testing_Mode_Param_36_MFR : 319|8@0+ (1,0) [0|255] "N/A"  ASDM
 SG_ Testing_Mode_Param_37_MFR : 327|8@0+ (1,0) [0|255] "N/A"  ASDM
 SG_ Testing_Mode_Param_38_MFR : 335|8@0+ (1,0) [0|255] "N/A"  ASDM
 SG_ Testing_Mode_Param_39_MFR : 343|8@0+ (1,0) [0|255] "N/A"  ASDM
 SG_ Testing_Mode_Param_40_MFR : 351|8@0+ (1,0) [0|255] "N/A"  ASDM
 SG_ Testing_Mode_Param_41_MFR : 359|8@0+ (1,0) [0|255] "N/A"  ASDM
 SG_ Testing_Mode_Param_42_MFR : 367|8@0+ (1,0) [0|255] "N/A"  ASDM
 SG_ Testing_Mode_Param_43_MFR : 375|8@0+ (1,0) [0|255] "N/A"  ASDM
 SG_ Testing_Mode_Param_44_MFR : 383|8@0+ (1,0) [0|255] "N/A"  ASDM
 SG_ Testing_Mode_Param_45_MFR : 391|8@0+ (1,0) [0|255] "N/A"  ASDM
 SG_ Testing_Mode_Param_46_MFR : 399|8@0+ (1,0) [0|255] "N/A"  ASDM
 SG_ Testing_Mode_Param_47_MFR : 407|8@0+ (1,0) [0|255] "N/A"  ASDM
 SG_ Testing_Mode_Param_48_MFR : 415|8@0+ (1,0) [0|255] "N/A"  ASDM
 SG_ Testing_Mode_Param_49_MFR : 423|8@0+ (1,0) [0|255] "N/A"  ASDM
 SG_ Testing_Mode_Param_50_MFR : 431|8@0+ (1,0) [0|255] "N/A"  ASDM
 SG_ Testing_Mode_Param_51_MFR : 439|8@0+ (1,0) [0|255] "N/A"  ASDM
 SG_ Testing_Mode_Param_52_MFR : 447|8@0+ (1,0) [0|255] "N/A"  ASDM
 SG_ Testing_Mode_Param_53_MFR : 455|8@0+ (1,0) [0|255] "N/A"  ASDM
 SG_ Testing_Mode_Param_54_MFR : 463|8@0+ (1,0) [0|255] "N/A"  ASDM
 SG_ Testing_Mode_Param_55_MFR : 471|8@0+ (1,0) [0|255] "N/A"  ASDM
 SG_ Testing_Mode_Param_56_MFR : 479|8@0+ (1,0) [0|255] "N/A"  ASDM
 SG_ Testing_Mode_Param_57_MFR : 487|8@0+ (1,0) [0|255] "N/A"  ASDM
 SG_ Testing_Mode_Param_58_MFR : 495|8@0+ (1,0) [0|255] "N/A"  ASDM
 SG_ Testing_Mode_Param_59_MFR : 503|8@0+ (1,0) [0|255] "N/A"  ASDM
 SG_ Testing_Mode_Param_60_MFR : 511|8@0+ (1,0) [0|255] "N/A"  ASDM

BO_ 1290 MB79_LLHT_HEADER_MFR: 64 FLRB
 SG_ LLHT_Data_Header_Mode_ID_MFR : 7|16@0+ (1,0) [0|65535] "N/A"  ASDM
 SG_ LLHT_Data_Header_SubID_MFR : 23|8@0+ (1,0) [0|255] "N/A"  ASDM
 SG_ LLHT_Data_Header_MCC_MFR : 31|32@0+ (1,0) [0|4294967295] "N/A"  ASDM
 SG_ LLHT_Data_Header_BlkLength_MFR : 63|16@0+ (1,0) [0|65535] "N/A"  ASDM
 SG_ LLHT_Data_Header_BlockCnt_MFR : 79|8@0+ (1,0) [0|255] "N/A"  ASDM
 SG_ LLHT_Data_Header_NumBlocks_MFR : 87|8@0+ (1,0) [0|255] "N/A"  ASDM
 SG_ LLHT_Data_Header_FrmCnt_MFR : 95|8@0+ (1,0) [0|255] "N/A"  ASDM
 SG_ LLHT_Data_Header_Reserved_MFR : 103|16@0+ (1,0) [0|65535] "N/A"  ASDM
 SG_ LLHT_Data_Header_Config_0_MFR : 119|8@0+ (1,0) [0|255] "N/A"  ASDM
 SG_ LLHT_Data_Header_Config_1_MFR : 127|8@0+ (1,0) [0|255] "N/A"  ASDM
 SG_ LLHT_Data_Header_Config_2_MFR : 135|8@0+ (1,0) [0|255] "N/A"  ASDM
 SG_ LLHT_Data_Header_Config_3_MFR : 143|8@0+ (1,0) [0|255] "N/A"  ASDM
 SG_ LLHT_Data_Header_Config_4_MFR : 151|8@0+ (1,0) [0|255] "N/A"  ASDM
 SG_ LLHT_Data_Header_Config_5_MFR : 159|8@0+ (1,0) [0|255] "N/A"  ASDM
 SG_ LLHT_Data_Header_Config_6_MFR : 167|8@0+ (1,0) [0|255] "N/A"  ASDM
 SG_ LLHT_Data_Header_Config_7_MFR : 175|8@0+ (1,0) [0|255] "N/A"  ASDM
 SG_ LLHT_Data_Header_Config_8_MFR : 183|8@0+ (1,0) [0|255] "N/A"  ASDM
 SG_ LLHT_Data_Header_Config_9_MFR : 191|8@0+ (1,0) [0|255] "N/A"  ASDM
 SG_ LLHT_Data_Header_Config_10_MFR : 199|8@0+ (1,0) [0|255] "N/A"  ASDM
 SG_ LLHT_Data_Header_Config_11_MFR : 207|8@0+ (1,0) [0|255] "N/A"  ASDM
 SG_ LLHT_Data_Header_Config_12_MFR : 215|8@0+ (1,0) [0|255] "N/A"  ASDM
 SG_ LLHT_Data_Header_Config_13_MFR : 223|8@0+ (1,0) [0|255] "N/A"  ASDM
 SG_ LLHT_Data_Header_Config_14_MFR : 231|8@0+ (1,0) [0|255] "N/A"  ASDM
 SG_ LLHT_Data_Header_Config_15_MFR : 239|8@0+ (1,0) [0|255] "N/A"  ASDM
 SG_ LLHT_Data_Header_Config_16_MFR : 247|8@0+ (1,0) [0|255] "N/A"  ASDM
 SG_ LLHT_Data_Header_Config_17_MFR : 255|8@0+ (1,0) [0|255] "N/A"  ASDM
 SG_ LLHT_Data_Header_Config_18_MFR : 263|8@0+ (1,0) [0|255] "N/A"  ASDM
 SG_ LLHT_Data_Header_Config_19_MFR : 271|8@0+ (1,0) [0|255] "N/A"  ASDM
 SG_ LLHT_Data_Header_Config_20_MFR : 279|8@0+ (1,0) [0|255] "N/A"  ASDM
 SG_ LLHT_Data_Header_Config_21_MFR : 287|8@0+ (1,0) [0|255] "N/A"  ASDM
 SG_ LLHT_Data_Header_Config_22_MFR : 295|8@0+ (1,0) [0|255] "N/A"  ASDM
 SG_ LLHT_Data_Header_Config_23_MFR : 303|8@0+ (1,0) [0|255] "N/A"  ASDM
 SG_ LLHT_Data_Header_Config_24_MFR : 311|8@0+ (1,0) [0|255] "N/A"  ASDM
 SG_ LLHT_Data_Header_Config_25_MFR : 319|8@0+ (1,0) [0|255] "N/A"  ASDM
 SG_ LLHT_Data_Header_Config_26_MFR : 327|8@0+ (1,0) [0|255] "N/A"  ASDM
 SG_ LLHT_Data_Header_Config_27_MFR : 335|8@0+ (1,0) [0|255] "N/A"  ASDM
 SG_ LLHT_Data_Header_Config_28_MFR : 343|8@0+ (1,0) [0|255] "N/A"  ASDM
 SG_ LLHT_Data_Header_Config_29_MFR : 351|8@0+ (1,0) [0|255] "N/A"  ASDM
 SG_ LLHT_Data_Header_Config_30_MFR : 359|8@0+ (1,0) [0|255] "N/A"  ASDM
 SG_ LLHT_Data_Header_Config_31_MFR : 367|8@0+ (1,0) [0|255] "N/A"  ASDM
 SG_ LLHT_Data_Header_Config_32_MFR : 375|8@0+ (1,0) [0|255] "N/A"  ASDM
 SG_ LLHT_Data_Header_Config_33_MFR : 383|8@0+ (1,0) [0|255] "N/A"  ASDM
 SG_ LLHT_Data_Header_Config_34_MFR : 391|8@0+ (1,0) [0|255] "N/A"  ASDM
 SG_ LLHT_Data_Header_Config_35_MFR : 399|8@0+ (1,0) [0|255] "N/A"  ASDM
 SG_ LLHT_Data_Header_Config_36_MFR : 407|8@0+ (1,0) [0|255] "N/A"  ASDM
 SG_ LLHT_Data_Header_Config_37_MFR : 415|8@0+ (1,0) [0|255] "N/A"  ASDM
 SG_ LLHT_Data_Header_Config_38_MFR : 423|8@0+ (1,0) [0|255] "N/A"  ASDM
 SG_ LLHT_Data_Header_Config_39_MFR : 431|8@0+ (1,0) [0|255] "N/A"  ASDM
 SG_ LLHT_Data_Header_Config_40_MFR : 439|8@0+ (1,0) [0|255] "N/A"  ASDM
 SG_ LLHT_Data_Header_Config_41_MFR : 447|8@0+ (1,0) [0|255] "N/A"  ASDM
 SG_ LLHT_Data_Header_Config_42_MFR : 455|8@0+ (1,0) [0|255] "N/A"  ASDM
 SG_ LLHT_Data_Header_Config_43_MFR : 463|8@0+ (1,0) [0|255] "N/A"  ASDM
 SG_ LLHT_Data_Header_Config_44_MFR : 471|8@0+ (1,0) [0|255] "N/A"  ASDM
 SG_ LLHT_Data_Header_Config_45_MFR : 479|8@0+ (1,0) [0|255] "N/A"  ASDM
 SG_ LLHT_Data_Header_Config_46_MFR : 487|8@0+ (1,0) [0|255] "N/A"  ASDM
 SG_ LLHT_Data_Header_Config_47_MFR : 495|8@0+ (1,0) [0|255] "N/A"  ASDM
 SG_ LLHT_Data_Header_Config_48_MFR : 503|8@0+ (1,0) [0|255] "N/A"  ASDM
 SG_ LLHT_Data_Header_Config_49_MFR : 511|8@0+ (1,0) [0|255] "N/A"  ASDM

BO_ 1291 MB79_LLHT_0_MFR: 64 FLRB
 SG_ LLHT_Data_0_payload_0_MFR : 7|16@0+ (1,0) [0|65535] "N/A"  ASDM
 SG_ LLHT_Data_0_payload_1_MFR : 23|16@0+ (1,0) [0|65535] "N/A"  ASDM
 SG_ LLHT_Data_0_payload_2_MFR : 39|16@0+ (1,0) [0|65535] "N/A"  ASDM
 SG_ LLHT_Data_0_payload_3_MFR : 55|16@0+ (1,0) [0|65535] "N/A"  ASDM
 SG_ LLHT_Data_0_payload_4_MFR : 71|16@0+ (1,0) [0|65535] "N/A"  ASDM
 SG_ LLHT_Data_0_payload_5_MFR : 87|16@0+ (1,0) [0|65535] "N/A"  ASDM
 SG_ LLHT_Data_0_payload_6_MFR : 103|16@0+ (1,0) [0|65535] "N/A"  ASDM
 SG_ LLHT_Data_0_payload_7_MFR : 119|16@0+ (1,0) [0|65535] "N/A"  ASDM
 SG_ LLHT_Data_0_payload_8_MFR : 135|16@0+ (1,0) [0|65535] "N/A"  ASDM
 SG_ LLHT_Data_0_payload_9_MFR : 151|16@0+ (1,0) [0|65535] "N/A"  ASDM
 SG_ LLHT_Data_0_payload_10_MFR : 167|16@0+ (1,0) [0|65535] "N/A"  ASDM
 SG_ LLHT_Data_0_payload_11_MFR : 183|16@0+ (1,0) [0|65535] "N/A"  ASDM
 SG_ LLHT_Data_0_payload_12_MFR : 199|16@0+ (1,0) [0|65535] "N/A"  ASDM
 SG_ LLHT_Data_0_payload_13_MFR : 215|16@0+ (1,0) [0|65535] "N/A"  ASDM
 SG_ LLHT_Data_0_payload_14_MFR : 231|16@0+ (1,0) [0|65535] "N/A"  ASDM
 SG_ LLHT_Data_0_payload_15_MFR : 247|16@0+ (1,0) [0|65535] "N/A"  ASDM
 SG_ LLHT_Data_0_payload_16_MFR : 263|16@0+ (1,0) [0|65535] "N/A"  ASDM
 SG_ LLHT_Data_0_payload_17_MFR : 279|16@0+ (1,0) [0|65535] "N/A"  ASDM
 SG_ LLHT_Data_0_payload_18_MFR : 295|16@0+ (1,0) [0|65535] "N/A"  ASDM
 SG_ LLHT_Data_0_payload_19_MFR : 311|16@0+ (1,0) [0|65535] "N/A"  ASDM
 SG_ LLHT_Data_0_payload_20_MFR : 327|16@0+ (1,0) [0|65535] "N/A"  ASDM
 SG_ LLHT_Data_0_payload_21_MFR : 343|16@0+ (1,0) [0|65535] "N/A"  ASDM
 SG_ LLHT_Data_0_payload_22_MFR : 359|16@0+ (1,0) [0|65535] "N/A"  ASDM
 SG_ LLHT_Data_0_payload_23_MFR : 375|16@0+ (1,0) [0|65535] "N/A"  ASDM
 SG_ LLHT_Data_0_payload_24_MFR : 391|16@0+ (1,0) [0|65535] "N/A"  ASDM
 SG_ LLHT_Data_0_payload_25_MFR : 407|16@0+ (1,0) [0|65535] "N/A"  ASDM
 SG_ LLHT_Data_0_payload_26_MFR : 423|16@0+ (1,0) [0|65535] "N/A"  ASDM
 SG_ LLHT_Data_0_payload_27_MFR : 439|16@0+ (1,0) [0|65535] "N/A"  ASDM
 SG_ LLHT_Data_0_payload_28_MFR : 455|16@0+ (1,0) [0|65535] "N/A"  ASDM
 SG_ LLHT_Data_0_payload_29_MFR : 471|16@0+ (1,0) [0|65535] "N/A"  ASDM
 SG_ LLHT_Data_0_payload_30_MFR : 487|16@0+ (1,0) [0|65535] "N/A"  ASDM
 SG_ LLHT_Data_0_payload_31_MFR : 503|16@0+ (1,0) [0|65535] "N/A"  ASDM

BO_ 1292 MB79_LLHT_1_MFR: 64 FLRB
 SG_ LLHT_Data_1_payload_32_MFR : 7|16@0+ (1,0) [0|65535] "N/A"  ASDM
 SG_ LLHT_Data_1_payload_33_MFR : 23|16@0+ (1,0) [0|65535] "N/A"  ASDM
 SG_ LLHT_Data_1_payload_34_MFR : 39|16@0+ (1,0) [0|65535] "N/A"  ASDM
 SG_ LLHT_Data_1_payload_35_MFR : 55|16@0+ (1,0) [0|65535] "N/A"  ASDM
 SG_ LLHT_Data_1_payload_36_MFR : 71|16@0+ (1,0) [0|65535] "N/A"  ASDM
 SG_ LLHT_Data_1_payload_37_MFR : 87|16@0+ (1,0) [0|65535] "N/A"  ASDM
 SG_ LLHT_Data_1_payload_38_MFR : 103|16@0+ (1,0) [0|65535] "N/A"  ASDM
 SG_ LLHT_Data_1_payload_39_MFR : 119|16@0+ (1,0) [0|65535] "N/A"  ASDM
 SG_ LLHT_Data_1_payload_40_MFR : 135|16@0+ (1,0) [0|65535] "N/A"  ASDM
 SG_ LLHT_Data_1_payload_41_MFR : 151|16@0+ (1,0) [0|65535] "N/A"  ASDM
 SG_ LLHT_Data_1_payload_42_MFR : 167|16@0+ (1,0) [0|65535] "N/A"  ASDM
 SG_ LLHT_Data_1_payload_43_MFR : 183|16@0+ (1,0) [0|65535] "N/A"  ASDM
 SG_ LLHT_Data_1_payload_44_MFR : 199|16@0+ (1,0) [0|65535] "N/A"  ASDM
 SG_ LLHT_Data_1_payload_45_MFR : 215|16@0+ (1,0) [0|65535] "N/A"  ASDM
 SG_ LLHT_Data_1_payload_46_MFR : 231|16@0+ (1,0) [0|65535] "N/A"  ASDM
 SG_ LLHT_Data_1_payload_47_MFR : 247|16@0+ (1,0) [0|65535] "N/A"  ASDM
 SG_ LLHT_Data_1_payload_48_MFR : 263|16@0+ (1,0) [0|65535] "N/A"  ASDM
 SG_ LLHT_Data_1_payload_49_MFR : 279|16@0+ (1,0) [0|65535] "N/A"  ASDM
 SG_ LLHT_Data_1_payload_50_MFR : 295|16@0+ (1,0) [0|65535] "N/A"  ASDM
 SG_ LLHT_Data_1_payload_51_MFR : 311|16@0+ (1,0) [0|65535] "N/A"  ASDM
 SG_ LLHT_Data_1_payload_52_MFR : 327|16@0+ (1,0) [0|65535] "N/A"  ASDM
 SG_ LLHT_Data_1_payload_53_MFR : 343|16@0+ (1,0) [0|65535] "N/A"  ASDM
 SG_ LLHT_Data_1_payload_54_MFR : 359|16@0+ (1,0) [0|65535] "N/A"  ASDM
 SG_ LLHT_Data_1_payload_55_MFR : 375|16@0+ (1,0) [0|65535] "N/A"  ASDM
 SG_ LLHT_Data_1_payload_56_MFR : 391|16@0+ (1,0) [0|65535] "N/A"  ASDM
 SG_ LLHT_Data_1_payload_57_MFR : 407|16@0+ (1,0) [0|65535] "N/A"  ASDM
 SG_ LLHT_Data_1_payload_58_MFR : 423|16@0+ (1,0) [0|65535] "N/A"  ASDM
 SG_ LLHT_Data_1_payload_59_MFR : 439|16@0+ (1,0) [0|65535] "N/A"  ASDM
 SG_ LLHT_Data_1_payload_60_MFR : 455|16@0+ (1,0) [0|65535] "N/A"  ASDM
 SG_ LLHT_Data_1_payload_61_MFR : 471|16@0+ (1,0) [0|65535] "N/A"  ASDM
 SG_ LLHT_Data_1_payload_62_MFR : 487|16@0+ (1,0) [0|65535] "N/A"  ASDM
 SG_ LLHT_Data_1_payload_63_MFR : 503|16@0+ (1,0) [0|65535] "N/A"  ASDM

BO_ 1293 MB79_LLHT_2_MFR: 64 FLRB
 SG_ LLHT_Data_2_payload_64_MFR : 7|16@0+ (1,0) [0|65535] "N/A"  ASDM
 SG_ LLHT_Data_2_payload_65_MFR : 23|16@0+ (1,0) [0|65535] "N/A"  ASDM
 SG_ LLHT_Data_2_payload_66_MFR : 39|16@0+ (1,0) [0|65535] "N/A"  ASDM
 SG_ LLHT_Data_2_payload_67_MFR : 55|16@0+ (1,0) [0|65535] "N/A"  ASDM
 SG_ LLHT_Data_2_payload_68_MFR : 71|16@0+ (1,0) [0|65535] "N/A"  ASDM
 SG_ LLHT_Data_2_payload_69_MFR : 87|16@0+ (1,0) [0|65535] "N/A"  ASDM
 SG_ LLHT_Data_2_payload_70_MFR : 103|16@0+ (1,0) [0|65535] "N/A"  ASDM
 SG_ LLHT_Data_2_payload_71_MFR : 119|16@0+ (1,0) [0|65535] "N/A"  ASDM
 SG_ LLHT_Data_2_payload_72_MFR : 135|16@0+ (1,0) [0|65535] "N/A"  ASDM
 SG_ LLHT_Data_2_payload_73_MFR : 151|16@0+ (1,0) [0|65535] "N/A"  ASDM
 SG_ LLHT_Data_2_payload_74_MFR : 167|16@0+ (1,0) [0|65535] "N/A"  ASDM
 SG_ LLHT_Data_2_payload_75_MFR : 183|16@0+ (1,0) [0|65535] "N/A"  ASDM
 SG_ LLHT_Data_2_payload_76_MFR : 199|16@0+ (1,0) [0|65535] "N/A"  ASDM
 SG_ LLHT_Data_2_payload_77_MFR : 215|16@0+ (1,0) [0|65535] "N/A"  ASDM
 SG_ LLHT_Data_2_payload_78_MFR : 231|16@0+ (1,0) [0|65535] "N/A"  ASDM
 SG_ LLHT_Data_2_payload_79_MFR : 247|16@0+ (1,0) [0|65535] "N/A"  ASDM
 SG_ LLHT_Data_2_payload_80_MFR : 263|16@0+ (1,0) [0|65535] "N/A"  ASDM
 SG_ LLHT_Data_2_payload_81_MFR : 279|16@0+ (1,0) [0|65535] "N/A"  ASDM
 SG_ LLHT_Data_2_payload_82_MFR : 295|16@0+ (1,0) [0|65535] "N/A"  ASDM
 SG_ LLHT_Data_2_payload_83_MFR : 311|16@0+ (1,0) [0|65535] "N/A"  ASDM
 SG_ LLHT_Data_2_payload_84_MFR : 327|16@0+ (1,0) [0|65535] "N/A"  ASDM
 SG_ LLHT_Data_2_payload_85_MFR : 343|16@0+ (1,0) [0|65535] "N/A"  ASDM
 SG_ LLHT_Data_2_payload_86_MFR : 359|16@0+ (1,0) [0|65535] "N/A"  ASDM
 SG_ LLHT_Data_2_payload_87_MFR : 375|16@0+ (1,0) [0|65535] "N/A"  ASDM
 SG_ LLHT_Data_2_payload_88_MFR : 391|16@0+ (1,0) [0|65535] "N/A"  ASDM
 SG_ LLHT_Data_2_payload_89_MFR : 407|16@0+ (1,0) [0|65535] "N/A"  ASDM
 SG_ LLHT_Data_2_payload_90_MFR : 423|16@0+ (1,0) [0|65535] "N/A"  ASDM
 SG_ LLHT_Data_2_payload_91_MFR : 439|16@0+ (1,0) [0|65535] "N/A"  ASDM
 SG_ LLHT_Data_2_payload_92_MFR : 455|16@0+ (1,0) [0|65535] "N/A"  ASDM
 SG_ LLHT_Data_2_payload_93_MFR : 471|16@0+ (1,0) [0|65535] "N/A"  ASDM
 SG_ LLHT_Data_2_payload_94_MFR : 487|16@0+ (1,0) [0|65535] "N/A"  ASDM
 SG_ LLHT_Data_2_payload_95_MFR : 503|16@0+ (1,0) [0|65535] "N/A"  ASDM

BO_ 1294 MB79_LLHT_3_MFR: 64 FLRB
 SG_ LLHT_Data_3_payload_96_MFR : 7|16@0+ (1,0) [0|65535] "N/A"  ASDM
 SG_ LLHT_Data_3_payload_97_MFR : 23|16@0+ (1,0) [0|65535] "N/A"  ASDM
 SG_ LLHT_Data_3_payload_98_MFR : 39|16@0+ (1,0) [0|65535] "N/A"  ASDM
 SG_ LLHT_Data_3_payload_99_MFR : 55|16@0+ (1,0) [0|65535] "N/A"  ASDM
 SG_ LLHT_Data_3_payload_100_MFR : 71|16@0+ (1,0) [0|65535] "N/A"  ASDM
 SG_ LLHT_Data_3_payload_101_MFR : 87|16@0+ (1,0) [0|65535] "N/A"  ASDM
 SG_ LLHT_Data_3_payload_102_MFR : 103|16@0+ (1,0) [0|65535] "N/A"  ASDM
 SG_ LLHT_Data_3_payload_103_MFR : 119|16@0+ (1,0) [0|65535] "N/A"  ASDM
 SG_ LLHT_Data_3_payload_104_MFR : 135|16@0+ (1,0) [0|65535] "N/A"  ASDM
 SG_ LLHT_Data_3_payload_105_MFR : 151|16@0+ (1,0) [0|65535] "N/A"  ASDM
 SG_ LLHT_Data_3_payload_106_MFR : 167|16@0+ (1,0) [0|65535] "N/A"  ASDM
 SG_ LLHT_Data_3_payload_107_MFR : 183|16@0+ (1,0) [0|65535] "N/A"  ASDM
 SG_ LLHT_Data_3_payload_108_MFR : 199|16@0+ (1,0) [0|65535] "N/A"  ASDM
 SG_ LLHT_Data_3_payload_109_MFR : 215|16@0+ (1,0) [0|65535] "N/A"  ASDM
 SG_ LLHT_Data_3_payload_110_MFR : 231|16@0+ (1,0) [0|65535] "N/A"  ASDM
 SG_ LLHT_Data_3_payload_111_MFR : 247|16@0+ (1,0) [0|65535] "N/A"  ASDM
 SG_ LLHT_Data_3_payload_112_MFR : 263|16@0+ (1,0) [0|65535] "N/A"  ASDM
 SG_ LLHT_Data_3_payload_113_MFR : 279|16@0+ (1,0) [0|65535] "N/A"  ASDM
 SG_ LLHT_Data_3_payload_114_MFR : 295|16@0+ (1,0) [0|65535] "N/A"  ASDM
 SG_ LLHT_Data_3_payload_115_MFR : 311|16@0+ (1,0) [0|65535] "N/A"  ASDM
 SG_ LLHT_Data_3_payload_116_MFR : 327|16@0+ (1,0) [0|65535] "N/A"  ASDM
 SG_ LLHT_Data_3_payload_117_MFR : 343|16@0+ (1,0) [0|65535] "N/A"  ASDM
 SG_ LLHT_Data_3_payload_118_MFR : 359|16@0+ (1,0) [0|65535] "N/A"  ASDM
 SG_ LLHT_Data_3_payload_119_MFR : 375|16@0+ (1,0) [0|65535] "N/A"  ASDM
 SG_ LLHT_Data_3_payload_120_MFR : 391|16@0+ (1,0) [0|65535] "N/A"  ASDM
 SG_ LLHT_Data_3_payload_121_MFR : 407|16@0+ (1,0) [0|65535] "N/A"  ASDM
 SG_ LLHT_Data_3_payload_122_MFR : 423|16@0+ (1,0) [0|65535] "N/A"  ASDM
 SG_ LLHT_Data_3_payload_123_MFR : 439|16@0+ (1,0) [0|65535] "N/A"  ASDM
 SG_ LLHT_Data_3_payload_124_MFR : 455|16@0+ (1,0) [0|65535] "N/A"  ASDM
 SG_ LLHT_Data_3_payload_125_MFR : 471|16@0+ (1,0) [0|65535] "N/A"  ASDM
 SG_ LLHT_Data_3_payload_126_MFR : 487|16@0+ (1,0) [0|65535] "N/A"  ASDM
 SG_ LLHT_Data_3_payload_127_MFR : 503|16@0+ (1,0) [0|65535] "N/A"  ASDM

BO_ 1295 MB79_LLHT_4_MFR: 64 FLRB
 SG_ LLHT_Data_4_payload_128_MFR : 7|16@0+ (1,0) [0|65535] "N/A"  ASDM
 SG_ LLHT_Data_4_payload_129_MFR : 23|16@0+ (1,0) [0|65535] "N/A"  ASDM
 SG_ LLHT_Data_4_payload_130_MFR : 39|16@0+ (1,0) [0|65535] "N/A"  ASDM
 SG_ LLHT_Data_4_payload_131_MFR : 55|16@0+ (1,0) [0|65535] "N/A"  ASDM
 SG_ LLHT_Data_4_payload_132_MFR : 71|16@0+ (1,0) [0|65535] "N/A"  ASDM
 SG_ LLHT_Data_4_payload_133_MFR : 87|16@0+ (1,0) [0|65535] "N/A"  ASDM
 SG_ LLHT_Data_4_payload_134_MFR : 103|16@0+ (1,0) [0|65535] "N/A"  ASDM
 SG_ LLHT_Data_4_payload_135_MFR : 119|16@0+ (1,0) [0|65535] "N/A"  ASDM
 SG_ LLHT_Data_4_payload_136_MFR : 135|16@0+ (1,0) [0|65535] "N/A"  ASDM
 SG_ LLHT_Data_4_payload_137_MFR : 151|16@0+ (1,0) [0|65535] "N/A"  ASDM
 SG_ LLHT_Data_4_payload_138_MFR : 167|16@0+ (1,0) [0|65535] "N/A"  ASDM
 SG_ LLHT_Data_4_payload_139_MFR : 183|16@0+ (1,0) [0|65535] "N/A"  ASDM
 SG_ LLHT_Data_4_payload_140_MFR : 199|16@0+ (1,0) [0|65535] "N/A"  ASDM
 SG_ LLHT_Data_4_payload_141_MFR : 215|16@0+ (1,0) [0|65535] "N/A"  ASDM
 SG_ LLHT_Data_4_payload_142_MFR : 231|16@0+ (1,0) [0|65535] "N/A"  ASDM
 SG_ LLHT_Data_4_payload_143_MFR : 247|16@0+ (1,0) [0|65535] "N/A"  ASDM
 SG_ LLHT_Data_4_payload_144_MFR : 263|16@0+ (1,0) [0|65535] "N/A"  ASDM
 SG_ LLHT_Data_4_payload_145_MFR : 279|16@0+ (1,0) [0|65535] "N/A"  ASDM
 SG_ LLHT_Data_4_payload_146_MFR : 295|16@0+ (1,0) [0|65535] "N/A"  ASDM
 SG_ LLHT_Data_4_payload_147_MFR : 311|16@0+ (1,0) [0|65535] "N/A"  ASDM
 SG_ LLHT_Data_4_payload_148_MFR : 327|16@0+ (1,0) [0|65535] "N/A"  ASDM
 SG_ LLHT_Data_4_payload_149_MFR : 343|16@0+ (1,0) [0|65535] "N/A"  ASDM
 SG_ LLHT_Data_4_payload_150_MFR : 359|16@0+ (1,0) [0|65535] "N/A"  ASDM
 SG_ LLHT_Data_4_payload_151_MFR : 375|16@0+ (1,0) [0|65535] "N/A"  ASDM
 SG_ LLHT_Data_4_payload_152_MFR : 391|16@0+ (1,0) [0|65535] "N/A"  ASDM
 SG_ LLHT_Data_4_payload_153_MFR : 407|16@0+ (1,0) [0|65535] "N/A"  ASDM
 SG_ LLHT_Data_4_payload_154_MFR : 423|16@0+ (1,0) [0|65535] "N/A"  ASDM
 SG_ LLHT_Data_4_payload_155_MFR : 439|16@0+ (1,0) [0|65535] "N/A"  ASDM
 SG_ LLHT_Data_4_payload_156_MFR : 455|16@0+ (1,0) [0|65535] "N/A"  ASDM
 SG_ LLHT_Data_4_payload_157_MFR : 471|16@0+ (1,0) [0|65535] "N/A"  ASDM
 SG_ LLHT_Data_4_payload_158_MFR : 487|16@0+ (1,0) [0|65535] "N/A"  ASDM
 SG_ LLHT_Data_4_payload_159_MFR : 503|16@0+ (1,0) [0|65535] "N/A"  ASDM

BO_ 1296 MB79_LLHT_5_MFR: 64 FLRB
 SG_ LLHT_Data_5_payload_160_MFR : 7|16@0+ (1,0) [0|65535] "N/A"  ASDM
 SG_ LLHT_Data_5_payload_161_MFR : 23|16@0+ (1,0) [0|65535] "N/A"  ASDM
 SG_ LLHT_Data_5_payload_162_MFR : 39|16@0+ (1,0) [0|65535] "N/A"  ASDM
 SG_ LLHT_Data_5_payload_163_MFR : 55|16@0+ (1,0) [0|65535] "N/A"  ASDM
 SG_ LLHT_Data_5_payload_164_MFR : 71|16@0+ (1,0) [0|65535] "N/A"  ASDM
 SG_ LLHT_Data_5_payload_165_MFR : 87|16@0+ (1,0) [0|65535] "N/A"  ASDM
 SG_ LLHT_Data_5_payload_166_MFR : 103|16@0+ (1,0) [0|65535] "N/A"  ASDM
 SG_ LLHT_Data_5_payload_167_MFR : 119|16@0+ (1,0) [0|65535] "N/A"  ASDM
 SG_ LLHT_Data_5_payload_168_MFR : 135|16@0+ (1,0) [0|65535] "N/A"  ASDM
 SG_ LLHT_Data_5_payload_169_MFR : 151|16@0+ (1,0) [0|65535] "N/A"  ASDM
 SG_ LLHT_Data_5_payload_170_MFR : 167|16@0+ (1,0) [0|65535] "N/A"  ASDM
 SG_ LLHT_Data_5_payload_171_MFR : 183|16@0+ (1,0) [0|65535] "N/A"  ASDM
 SG_ LLHT_Data_5_payload_172_MFR : 199|16@0+ (1,0) [0|65535] "N/A"  ASDM
 SG_ LLHT_Data_5_payload_173_MFR : 215|16@0+ (1,0) [0|65535] "N/A"  ASDM
 SG_ LLHT_Data_5_payload_174_MFR : 231|16@0+ (1,0) [0|65535] "N/A"  ASDM
 SG_ LLHT_Data_5_payload_175_MFR : 247|16@0+ (1,0) [0|65535] "N/A"  ASDM
 SG_ LLHT_Data_5_payload_176_MFR : 263|16@0+ (1,0) [0|65535] "N/A"  ASDM
 SG_ LLHT_Data_5_payload_177_MFR : 279|16@0+ (1,0) [0|65535] "N/A"  ASDM
 SG_ LLHT_Data_5_payload_178_MFR : 295|16@0+ (1,0) [0|65535] "N/A"  ASDM
 SG_ LLHT_Data_5_payload_179_MFR : 311|16@0+ (1,0) [0|65535] "N/A"  ASDM
 SG_ LLHT_Data_5_payload_180_MFR : 327|16@0+ (1,0) [0|65535] "N/A"  ASDM
 SG_ LLHT_Data_5_payload_181_MFR : 343|16@0+ (1,0) [0|65535] "N/A"  ASDM
 SG_ LLHT_Data_5_payload_182_MFR : 359|16@0+ (1,0) [0|65535] "N/A"  ASDM
 SG_ LLHT_Data_5_payload_183_MFR : 375|16@0+ (1,0) [0|65535] "N/A"  ASDM
 SG_ LLHT_Data_5_payload_184_MFR : 391|16@0+ (1,0) [0|65535] "N/A"  ASDM
 SG_ LLHT_Data_5_payload_185_MFR : 407|16@0+ (1,0) [0|65535] "N/A"  ASDM
 SG_ LLHT_Data_5_payload_186_MFR : 423|16@0+ (1,0) [0|65535] "N/A"  ASDM
 SG_ LLHT_Data_5_payload_187_MFR : 439|16@0+ (1,0) [0|65535] "N/A"  ASDM
 SG_ LLHT_Data_5_payload_188_MFR : 455|16@0+ (1,0) [0|65535] "N/A"  ASDM
 SG_ LLHT_Data_5_payload_189_MFR : 471|16@0+ (1,0) [0|65535] "N/A"  ASDM
 SG_ LLHT_Data_5_payload_190_MFR : 487|16@0+ (1,0) [0|65535] "N/A"  ASDM
 SG_ LLHT_Data_5_payload_191_MFR : 503|16@0+ (1,0) [0|65535] "N/A"  ASDM

BO_ 1297 MB79_LLHT_6_MFR: 64 FLRB
 SG_ LLHT_Data_6_payload_192_MFR : 7|16@0+ (1,0) [0|65535] "N/A"  ASDM
 SG_ LLHT_Data_6_payload_193_MFR : 23|16@0+ (1,0) [0|65535] "N/A"  ASDM
 SG_ LLHT_Data_6_payload_194_MFR : 39|16@0+ (1,0) [0|65535] "N/A"  ASDM
 SG_ LLHT_Data_6_payload_195_MFR : 55|16@0+ (1,0) [0|65535] "N/A"  ASDM
 SG_ LLHT_Data_6_payload_196_MFR : 71|16@0+ (1,0) [0|65535] "N/A"  ASDM
 SG_ LLHT_Data_6_payload_197_MFR : 87|16@0+ (1,0) [0|65535] "N/A"  ASDM
 SG_ LLHT_Data_6_payload_198_MFR : 103|16@0+ (1,0) [0|65535] "N/A"  ASDM
 SG_ LLHT_Data_6_payload_199_MFR : 119|16@0+ (1,0) [0|65535] "N/A"  ASDM
 SG_ LLHT_Data_6_payload_200_MFR : 135|16@0+ (1,0) [0|65535] "N/A"  ASDM
 SG_ LLHT_Data_6_payload_201_MFR : 151|16@0+ (1,0) [0|65535] "N/A"  ASDM
 SG_ LLHT_Data_6_payload_202_MFR : 167|16@0+ (1,0) [0|65535] "N/A"  ASDM
 SG_ LLHT_Data_6_payload_203_MFR : 183|16@0+ (1,0) [0|65535] "N/A"  ASDM
 SG_ LLHT_Data_6_payload_204_MFR : 199|16@0+ (1,0) [0|65535] "N/A"  ASDM
 SG_ LLHT_Data_6_payload_205_MFR : 215|16@0+ (1,0) [0|65535] "N/A"  ASDM
 SG_ LLHT_Data_6_payload_206_MFR : 231|16@0+ (1,0) [0|65535] "N/A"  ASDM
 SG_ LLHT_Data_6_payload_207_MFR : 247|16@0+ (1,0) [0|65535] "N/A"  ASDM
 SG_ LLHT_Data_6_payload_208_MFR : 263|16@0+ (1,0) [0|65535] "N/A"  ASDM
 SG_ LLHT_Data_6_payload_209_MFR : 279|16@0+ (1,0) [0|65535] "N/A"  ASDM
 SG_ LLHT_Data_6_payload_210_MFR : 295|16@0+ (1,0) [0|65535] "N/A"  ASDM
 SG_ LLHT_Data_6_payload_211_MFR : 311|16@0+ (1,0) [0|65535] "N/A"  ASDM
 SG_ LLHT_Data_6_payload_212_MFR : 327|16@0+ (1,0) [0|65535] "N/A"  ASDM
 SG_ LLHT_Data_6_payload_213_MFR : 343|16@0+ (1,0) [0|65535] "N/A"  ASDM
 SG_ LLHT_Data_6_payload_214_MFR : 359|16@0+ (1,0) [0|65535] "N/A"  ASDM
 SG_ LLHT_Data_6_payload_215_MFR : 375|16@0+ (1,0) [0|65535] "N/A"  ASDM
 SG_ LLHT_Data_6_payload_216_MFR : 391|16@0+ (1,0) [0|65535] "N/A"  ASDM
 SG_ LLHT_Data_6_payload_217_MFR : 407|16@0+ (1,0) [0|65535] "N/A"  ASDM
 SG_ LLHT_Data_6_payload_218_MFR : 423|16@0+ (1,0) [0|65535] "N/A"  ASDM
 SG_ LLHT_Data_6_payload_219_MFR : 439|16@0+ (1,0) [0|65535] "N/A"  ASDM
 SG_ LLHT_Data_6_payload_220_MFR : 455|16@0+ (1,0) [0|65535] "N/A"  ASDM
 SG_ LLHT_Data_6_payload_221_MFR : 471|16@0+ (1,0) [0|65535] "N/A"  ASDM
 SG_ LLHT_Data_6_payload_222_MFR : 487|16@0+ (1,0) [0|65535] "N/A"  ASDM
 SG_ LLHT_Data_6_payload_223_MFR : 503|16@0+ (1,0) [0|65535] "N/A"  ASDM

BO_ 1298 MB79_LLHT_7_MFR: 64 FLRB
 SG_ LLHT_Data_7_payload_224_MFR : 7|16@0+ (1,0) [0|65535] "N/A"  ASDM
 SG_ LLHT_Data_7_payload_225_MFR : 23|16@0+ (1,0) [0|65535] "N/A"  ASDM
 SG_ LLHT_Data_7_payload_226_MFR : 39|16@0+ (1,0) [0|65535] "N/A"  ASDM
 SG_ LLHT_Data_7_payload_227_MFR : 55|16@0+ (1,0) [0|65535] "N/A"  ASDM
 SG_ LLHT_Data_7_payload_228_MFR : 71|16@0+ (1,0) [0|65535] "N/A"  ASDM
 SG_ LLHT_Data_7_payload_229_MFR : 87|16@0+ (1,0) [0|65535] "N/A"  ASDM
 SG_ LLHT_Data_7_payload_230_MFR : 103|16@0+ (1,0) [0|65535] "N/A"  ASDM
 SG_ LLHT_Data_7_payload_231_MFR : 119|16@0+ (1,0) [0|65535] "N/A"  ASDM
 SG_ LLHT_Data_7_payload_232_MFR : 135|16@0+ (1,0) [0|65535] "N/A"  ASDM
 SG_ LLHT_Data_7_payload_233_MFR : 151|16@0+ (1,0) [0|65535] "N/A"  ASDM
 SG_ LLHT_Data_7_payload_234_MFR : 167|16@0+ (1,0) [0|65535] "N/A"  ASDM
 SG_ LLHT_Data_7_payload_235_MFR : 183|16@0+ (1,0) [0|65535] "N/A"  ASDM
 SG_ LLHT_Data_7_payload_236_MFR : 199|16@0+ (1,0) [0|65535] "N/A"  ASDM
 SG_ LLHT_Data_7_payload_237_MFR : 215|16@0+ (1,0) [0|65535] "N/A"  ASDM
 SG_ LLHT_Data_7_payload_238_MFR : 231|16@0+ (1,0) [0|65535] "N/A"  ASDM
 SG_ LLHT_Data_7_payload_239_MFR : 247|16@0+ (1,0) [0|65535] "N/A"  ASDM
 SG_ LLHT_Data_7_payload_240_MFR : 263|16@0+ (1,0) [0|65535] "N/A"  ASDM
 SG_ LLHT_Data_7_payload_241_MFR : 279|16@0+ (1,0) [0|65535] "N/A"  ASDM
 SG_ LLHT_Data_7_payload_242_MFR : 295|16@0+ (1,0) [0|65535] "N/A"  ASDM
 SG_ LLHT_Data_7_payload_243_MFR : 311|16@0+ (1,0) [0|65535] "N/A"  ASDM
 SG_ LLHT_Data_7_payload_244_MFR : 327|16@0+ (1,0) [0|65535] "N/A"  ASDM
 SG_ LLHT_Data_7_payload_245_MFR : 343|16@0+ (1,0) [0|65535] "N/A"  ASDM
 SG_ LLHT_Data_7_payload_246_MFR : 359|16@0+ (1,0) [0|65535] "N/A"  ASDM
 SG_ LLHT_Data_7_payload_247_MFR : 375|16@0+ (1,0) [0|65535] "N/A"  ASDM
 SG_ LLHT_Data_7_payload_248_MFR : 391|16@0+ (1,0) [0|65535] "N/A"  ASDM
 SG_ LLHT_Data_7_payload_249_MFR : 407|16@0+ (1,0) [0|65535] "N/A"  ASDM
 SG_ LLHT_Data_7_payload_250_MFR : 423|16@0+ (1,0) [0|65535] "N/A"  ASDM
 SG_ LLHT_Data_7_payload_251_MFR : 439|16@0+ (1,0) [0|65535] "N/A"  ASDM
 SG_ LLHT_Data_7_payload_252_MFR : 455|16@0+ (1,0) [0|65535] "N/A"  ASDM
 SG_ LLHT_Data_7_payload_253_MFR : 471|16@0+ (1,0) [0|65535] "N/A"  ASDM
 SG_ LLHT_Data_7_payload_254_MFR : 487|16@0+ (1,0) [0|65535] "N/A"  ASDM
 SG_ LLHT_Data_7_payload_255_MFR : 503|16@0+ (1,0) [0|65535] "N/A"  ASDM

BO_ 1299 MB79_LLHT_8_MFR: 64 FLRB
 SG_ LLHT_Data_8_payload_256_MFR : 7|16@0+ (1,0) [0|65535] "N/A"  ASDM
 SG_ LLHT_Data_8_payload_257_MFR : 23|16@0+ (1,0) [0|65535] "N/A"  ASDM
 SG_ LLHT_Data_8_payload_258_MFR : 39|16@0+ (1,0) [0|65535] "N/A"  ASDM
 SG_ LLHT_Data_8_payload_259_MFR : 55|16@0+ (1,0) [0|65535] "N/A"  ASDM
 SG_ LLHT_Data_8_payload_260_MFR : 71|16@0+ (1,0) [0|65535] "N/A"  ASDM
 SG_ LLHT_Data_8_payload_261_MFR : 87|16@0+ (1,0) [0|65535] "N/A"  ASDM
 SG_ LLHT_Data_8_payload_262_MFR : 103|16@0+ (1,0) [0|65535] "N/A"  ASDM
 SG_ LLHT_Data_8_payload_263_MFR : 119|16@0+ (1,0) [0|65535] "N/A"  ASDM
 SG_ LLHT_Data_8_payload_264_MFR : 135|16@0+ (1,0) [0|65535] "N/A"  ASDM
 SG_ LLHT_Data_8_payload_265_MFR : 151|16@0+ (1,0) [0|65535] "N/A"  ASDM
 SG_ LLHT_Data_8_payload_266_MFR : 167|16@0+ (1,0) [0|65535] "N/A"  ASDM
 SG_ LLHT_Data_8_payload_267_MFR : 183|16@0+ (1,0) [0|65535] "N/A"  ASDM
 SG_ LLHT_Data_8_payload_268_MFR : 199|16@0+ (1,0) [0|65535] "N/A"  ASDM
 SG_ LLHT_Data_8_payload_269_MFR : 215|16@0+ (1,0) [0|65535] "N/A"  ASDM
 SG_ LLHT_Data_8_payload_270_MFR : 231|16@0+ (1,0) [0|65535] "N/A"  ASDM
 SG_ LLHT_Data_8_payload_271_MFR : 247|16@0+ (1,0) [0|65535] "N/A"  ASDM
 SG_ LLHT_Data_8_payload_272_MFR : 263|16@0+ (1,0) [0|65535] "N/A"  ASDM
 SG_ LLHT_Data_8_payload_273_MFR : 279|16@0+ (1,0) [0|65535] "N/A"  ASDM
 SG_ LLHT_Data_8_payload_274_MFR : 295|16@0+ (1,0) [0|65535] "N/A"  ASDM
 SG_ LLHT_Data_8_payload_275_MFR : 311|16@0+ (1,0) [0|65535] "N/A"  ASDM
 SG_ LLHT_Data_8_payload_276_MFR : 327|16@0+ (1,0) [0|65535] "N/A"  ASDM
 SG_ LLHT_Data_8_payload_277_MFR : 343|16@0+ (1,0) [0|65535] "N/A"  ASDM
 SG_ LLHT_Data_8_payload_278_MFR : 359|16@0+ (1,0) [0|65535] "N/A"  ASDM
 SG_ LLHT_Data_8_payload_279_MFR : 375|16@0+ (1,0) [0|65535] "N/A"  ASDM
 SG_ LLHT_Data_8_payload_280_MFR : 391|16@0+ (1,0) [0|65535] "N/A"  ASDM
 SG_ LLHT_Data_8_payload_281_MFR : 407|16@0+ (1,0) [0|65535] "N/A"  ASDM
 SG_ LLHT_Data_8_payload_282_MFR : 423|16@0+ (1,0) [0|65535] "N/A"  ASDM
 SG_ LLHT_Data_8_payload_283_MFR : 439|16@0+ (1,0) [0|65535] "N/A"  ASDM
 SG_ LLHT_Data_8_payload_284_MFR : 455|16@0+ (1,0) [0|65535] "N/A"  ASDM
 SG_ LLHT_Data_8_payload_285_MFR : 471|16@0+ (1,0) [0|65535] "N/A"  ASDM
 SG_ LLHT_Data_8_payload_286_MFR : 487|16@0+ (1,0) [0|65535] "N/A"  ASDM
 SG_ LLHT_Data_8_payload_287_MFR : 503|16@0+ (1,0) [0|65535] "N/A"  ASDM

BO_ 1300 MB79_LLHT_9_MFR: 64 FLRB
 SG_ LLHT_Data_9_payload_288_MFR : 7|16@0+ (1,0) [0|65535] "N/A"  ASDM
 SG_ LLHT_Data_9_payload_289_MFR : 23|16@0+ (1,0) [0|65535] "N/A"  ASDM
 SG_ LLHT_Data_9_payload_290_MFR : 39|16@0+ (1,0) [0|65535] "N/A"  ASDM
 SG_ LLHT_Data_9_payload_291_MFR : 55|16@0+ (1,0) [0|65535] "N/A"  ASDM
 SG_ LLHT_Data_9_payload_292_MFR : 71|16@0+ (1,0) [0|65535] "N/A"  ASDM
 SG_ LLHT_Data_9_payload_293_MFR : 87|16@0+ (1,0) [0|65535] "N/A"  ASDM
 SG_ LLHT_Data_9_payload_294_MFR : 103|16@0+ (1,0) [0|65535] "N/A"  ASDM
 SG_ LLHT_Data_9_payload_295_MFR : 119|16@0+ (1,0) [0|65535] "N/A"  ASDM
 SG_ LLHT_Data_9_payload_296_MFR : 135|16@0+ (1,0) [0|65535] "N/A"  ASDM
 SG_ LLHT_Data_9_payload_297_MFR : 151|16@0+ (1,0) [0|65535] "N/A"  ASDM
 SG_ LLHT_Data_9_payload_298_MFR : 167|16@0+ (1,0) [0|65535] "N/A"  ASDM
 SG_ LLHT_Data_9_payload_299_MFR : 183|16@0+ (1,0) [0|65535] "N/A"  ASDM
 SG_ LLHT_Data_9_payload_300_MFR : 199|16@0+ (1,0) [0|65535] "N/A"  ASDM
 SG_ LLHT_Data_9_payload_301_MFR : 215|16@0+ (1,0) [0|65535] "N/A"  ASDM
 SG_ LLHT_Data_9_payload_302_MFR : 231|16@0+ (1,0) [0|65535] "N/A"  ASDM
 SG_ LLHT_Data_9_payload_303_MFR : 247|16@0+ (1,0) [0|65535] "N/A"  ASDM
 SG_ LLHT_Data_9_payload_304_MFR : 263|16@0+ (1,0) [0|65535] "N/A"  ASDM
 SG_ LLHT_Data_9_payload_305_MFR : 279|16@0+ (1,0) [0|65535] "N/A"  ASDM
 SG_ LLHT_Data_9_payload_306_MFR : 295|16@0+ (1,0) [0|65535] "N/A"  ASDM
 SG_ LLHT_Data_9_payload_307_MFR : 311|16@0+ (1,0) [0|65535] "N/A"  ASDM
 SG_ LLHT_Data_9_payload_308_MFR : 327|16@0+ (1,0) [0|65535] "N/A"  ASDM
 SG_ LLHT_Data_9_payload_309_MFR : 343|16@0+ (1,0) [0|65535] "N/A"  ASDM
 SG_ LLHT_Data_9_payload_310_MFR : 359|16@0+ (1,0) [0|65535] "N/A"  ASDM
 SG_ LLHT_Data_9_payload_311_MFR : 375|16@0+ (1,0) [0|65535] "N/A"  ASDM
 SG_ LLHT_Data_9_payload_312_MFR : 391|16@0+ (1,0) [0|65535] "N/A"  ASDM
 SG_ LLHT_Data_9_payload_313_MFR : 407|16@0+ (1,0) [0|65535] "N/A"  ASDM
 SG_ LLHT_Data_9_payload_314_MFR : 423|16@0+ (1,0) [0|65535] "N/A"  ASDM
 SG_ LLHT_Data_9_payload_315_MFR : 439|16@0+ (1,0) [0|65535] "N/A"  ASDM
 SG_ LLHT_Data_9_payload_316_MFR : 455|16@0+ (1,0) [0|65535] "N/A"  ASDM
 SG_ LLHT_Data_9_payload_317_MFR : 471|16@0+ (1,0) [0|65535] "N/A"  ASDM
 SG_ LLHT_Data_9_payload_318_MFR : 487|16@0+ (1,0) [0|65535] "N/A"  ASDM
 SG_ LLHT_Data_9_payload_319_MFR : 503|16@0+ (1,0) [0|65535] "N/A"  ASDM

BO_ 1301 MB79_LLHT_10_MFR: 64 FLRB
 SG_ LLHT_Data_10_payload_320_MFR : 7|16@0+ (1,0) [0|65535] "N/A"  ASDM
 SG_ LLHT_Data_10_payload_321_MFR : 23|16@0+ (1,0) [0|65535] "N/A"  ASDM
 SG_ LLHT_Data_10_payload_322_MFR : 39|16@0+ (1,0) [0|65535] "N/A"  ASDM
 SG_ LLHT_Data_10_payload_323_MFR : 55|16@0+ (1,0) [0|65535] "N/A"  ASDM
 SG_ LLHT_Data_10_payload_324_MFR : 71|16@0+ (1,0) [0|65535] "N/A"  ASDM
 SG_ LLHT_Data_10_payload_325_MFR : 87|16@0+ (1,0) [0|65535] "N/A"  ASDM
 SG_ LLHT_Data_10_payload_326_MFR : 103|16@0+ (1,0) [0|65535] "N/A"  ASDM
 SG_ LLHT_Data_10_payload_327_MFR : 119|16@0+ (1,0) [0|65535] "N/A"  ASDM
 SG_ LLHT_Data_10_payload_328_MFR : 135|16@0+ (1,0) [0|65535] "N/A"  ASDM
 SG_ LLHT_Data_10_payload_329_MFR : 151|16@0+ (1,0) [0|65535] "N/A"  ASDM
 SG_ LLHT_Data_10_payload_330_MFR : 167|16@0+ (1,0) [0|65535] "N/A"  ASDM
 SG_ LLHT_Data_10_payload_331_MFR : 183|16@0+ (1,0) [0|65535] "N/A"  ASDM
 SG_ LLHT_Data_10_payload_332_MFR : 199|16@0+ (1,0) [0|65535] "N/A"  ASDM
 SG_ LLHT_Data_10_payload_333_MFR : 215|16@0+ (1,0) [0|65535] "N/A"  ASDM
 SG_ LLHT_Data_10_payload_334_MFR : 231|16@0+ (1,0) [0|65535] "N/A"  ASDM
 SG_ LLHT_Data_10_payload_335_MFR : 247|16@0+ (1,0) [0|65535] "N/A"  ASDM
 SG_ LLHT_Data_10_payload_336_MFR : 263|16@0+ (1,0) [0|65535] "N/A"  ASDM
 SG_ LLHT_Data_10_payload_337_MFR : 279|16@0+ (1,0) [0|65535] "N/A"  ASDM
 SG_ LLHT_Data_10_payload_338_MFR : 295|16@0+ (1,0) [0|65535] "N/A"  ASDM
 SG_ LLHT_Data_10_payload_339_MFR : 311|16@0+ (1,0) [0|65535] "N/A"  ASDM
 SG_ LLHT_Data_10_payload_340_MFR : 327|16@0+ (1,0) [0|65535] "N/A"  ASDM
 SG_ LLHT_Data_10_payload_341_MFR : 343|16@0+ (1,0) [0|65535] "N/A"  ASDM
 SG_ LLHT_Data_10_payload_342_MFR : 359|16@0+ (1,0) [0|65535] "N/A"  ASDM
 SG_ LLHT_Data_10_payload_343_MFR : 375|16@0+ (1,0) [0|65535] "N/A"  ASDM
 SG_ LLHT_Data_10_payload_344_MFR : 391|16@0+ (1,0) [0|65535] "N/A"  ASDM
 SG_ LLHT_Data_10_payload_345_MFR : 407|16@0+ (1,0) [0|65535] "N/A"  ASDM
 SG_ LLHT_Data_10_payload_346_MFR : 423|16@0+ (1,0) [0|65535] "N/A"  ASDM
 SG_ LLHT_Data_10_payload_347_MFR : 439|16@0+ (1,0) [0|65535] "N/A"  ASDM
 SG_ LLHT_Data_10_payload_348_MFR : 455|16@0+ (1,0) [0|65535] "N/A"  ASDM
 SG_ LLHT_Data_10_payload_349_MFR : 471|16@0+ (1,0) [0|65535] "N/A"  ASDM
 SG_ LLHT_Data_10_payload_350_MFR : 487|16@0+ (1,0) [0|65535] "N/A"  ASDM
 SG_ LLHT_Data_10_payload_351_MFR : 503|16@0+ (1,0) [0|65535] "N/A"  ASDM

BO_ 1302 MB79_LLHT_11_MFR: 64 FLRB
 SG_ LLHT_Data_11_payload_352_MFR : 7|16@0+ (1,0) [0|65535] "N/A"  ASDM
 SG_ LLHT_Data_11_payload_353_MFR : 23|16@0+ (1,0) [0|65535] "N/A"  ASDM
 SG_ LLHT_Data_11_payload_354_MFR : 39|16@0+ (1,0) [0|65535] "N/A"  ASDM
 SG_ LLHT_Data_11_payload_355_MFR : 55|16@0+ (1,0) [0|65535] "N/A"  ASDM
 SG_ LLHT_Data_11_payload_356_MFR : 71|16@0+ (1,0) [0|65535] "N/A"  ASDM
 SG_ LLHT_Data_11_payload_357_MFR : 87|16@0+ (1,0) [0|65535] "N/A"  ASDM
 SG_ LLHT_Data_11_payload_358_MFR : 103|16@0+ (1,0) [0|65535] "N/A"  ASDM
 SG_ LLHT_Data_11_payload_359_MFR : 119|16@0+ (1,0) [0|65535] "N/A"  ASDM
 SG_ LLHT_Data_11_payload_360_MFR : 135|16@0+ (1,0) [0|65535] "N/A"  ASDM
 SG_ LLHT_Data_11_payload_361_MFR : 151|16@0+ (1,0) [0|65535] "N/A"  ASDM
 SG_ LLHT_Data_11_payload_362_MFR : 167|16@0+ (1,0) [0|65535] "N/A"  ASDM
 SG_ LLHT_Data_11_payload_363_MFR : 183|16@0+ (1,0) [0|65535] "N/A"  ASDM
 SG_ LLHT_Data_11_payload_364_MFR : 199|16@0+ (1,0) [0|65535] "N/A"  ASDM
 SG_ LLHT_Data_11_payload_365_MFR : 215|16@0+ (1,0) [0|65535] "N/A"  ASDM
 SG_ LLHT_Data_11_payload_366_MFR : 231|16@0+ (1,0) [0|65535] "N/A"  ASDM
 SG_ LLHT_Data_11_payload_367_MFR : 247|16@0+ (1,0) [0|65535] "N/A"  ASDM
 SG_ LLHT_Data_11_payload_368_MFR : 263|16@0+ (1,0) [0|65535] "N/A"  ASDM
 SG_ LLHT_Data_11_payload_369_MFR : 279|16@0+ (1,0) [0|65535] "N/A"  ASDM
 SG_ LLHT_Data_11_payload_370_MFR : 295|16@0+ (1,0) [0|65535] "N/A"  ASDM
 SG_ LLHT_Data_11_payload_371_MFR : 311|16@0+ (1,0) [0|65535] "N/A"  ASDM
 SG_ LLHT_Data_11_payload_372_MFR : 327|16@0+ (1,0) [0|65535] "N/A"  ASDM
 SG_ LLHT_Data_11_payload_373_MFR : 343|16@0+ (1,0) [0|65535] "N/A"  ASDM
 SG_ LLHT_Data_11_payload_374_MFR : 359|16@0+ (1,0) [0|65535] "N/A"  ASDM
 SG_ LLHT_Data_11_payload_375_MFR : 375|16@0+ (1,0) [0|65535] "N/A"  ASDM
 SG_ LLHT_Data_11_payload_376_MFR : 391|16@0+ (1,0) [0|65535] "N/A"  ASDM
 SG_ LLHT_Data_11_payload_377_MFR : 407|16@0+ (1,0) [0|65535] "N/A"  ASDM
 SG_ LLHT_Data_11_payload_378_MFR : 423|16@0+ (1,0) [0|65535] "N/A"  ASDM
 SG_ LLHT_Data_11_payload_379_MFR : 439|16@0+ (1,0) [0|65535] "N/A"  ASDM
 SG_ LLHT_Data_11_payload_380_MFR : 455|16@0+ (1,0) [0|65535] "N/A"  ASDM
 SG_ LLHT_Data_11_payload_381_MFR : 471|16@0+ (1,0) [0|65535] "N/A"  ASDM
 SG_ LLHT_Data_11_payload_382_MFR : 487|16@0+ (1,0) [0|65535] "N/A"  ASDM
 SG_ LLHT_Data_11_payload_383_MFR : 503|16@0+ (1,0) [0|65535] "N/A"  ASDM

BO_ 1303 MB79_LLHT_12_MFR: 64 FLRB
 SG_ LLHT_Data_12_payload_384_MFR : 7|16@0+ (1,0) [0|65535] "N/A"  ASDM
 SG_ LLHT_Data_12_payload_385_MFR : 23|16@0+ (1,0) [0|65535] "N/A"  ASDM
 SG_ LLHT_Data_12_payload_386_MFR : 39|16@0+ (1,0) [0|65535] "N/A"  ASDM
 SG_ LLHT_Data_12_payload_387_MFR : 55|16@0+ (1,0) [0|65535] "N/A"  ASDM
 SG_ LLHT_Data_12_payload_388_MFR : 71|16@0+ (1,0) [0|65535] "N/A"  ASDM
 SG_ LLHT_Data_12_payload_389_MFR : 87|16@0+ (1,0) [0|65535] "N/A"  ASDM
 SG_ LLHT_Data_12_payload_390_MFR : 103|16@0+ (1,0) [0|65535] "N/A"  ASDM
 SG_ LLHT_Data_12_payload_391_MFR : 119|16@0+ (1,0) [0|65535] "N/A"  ASDM
 SG_ LLHT_Data_12_payload_392_MFR : 135|16@0+ (1,0) [0|65535] "N/A"  ASDM
 SG_ LLHT_Data_12_payload_393_MFR : 151|16@0+ (1,0) [0|65535] "N/A"  ASDM
 SG_ LLHT_Data_12_payload_394_MFR : 167|16@0+ (1,0) [0|65535] "N/A"  ASDM
 SG_ LLHT_Data_12_payload_395_MFR : 183|16@0+ (1,0) [0|65535] "N/A"  ASDM
 SG_ LLHT_Data_12_payload_396_MFR : 199|16@0+ (1,0) [0|65535] "N/A"  ASDM
 SG_ LLHT_Data_12_payload_397_MFR : 215|16@0+ (1,0) [0|65535] "N/A"  ASDM
 SG_ LLHT_Data_12_payload_398_MFR : 231|16@0+ (1,0) [0|65535] "N/A"  ASDM
 SG_ LLHT_Data_12_payload_399_MFR : 247|16@0+ (1,0) [0|65535] "N/A"  ASDM
 SG_ LLHT_Data_12_payload_400_MFR : 263|16@0+ (1,0) [0|65535] "N/A"  ASDM
 SG_ LLHT_Data_12_payload_401_MFR : 279|16@0+ (1,0) [0|65535] "N/A"  ASDM
 SG_ LLHT_Data_12_payload_402_MFR : 295|16@0+ (1,0) [0|65535] "N/A"  ASDM
 SG_ LLHT_Data_12_payload_403_MFR : 311|16@0+ (1,0) [0|65535] "N/A"  ASDM
 SG_ LLHT_Data_12_payload_404_MFR : 327|16@0+ (1,0) [0|65535] "N/A"  ASDM
 SG_ LLHT_Data_12_payload_405_MFR : 343|16@0+ (1,0) [0|65535] "N/A"  ASDM
 SG_ LLHT_Data_12_payload_406_MFR : 359|16@0+ (1,0) [0|65535] "N/A"  ASDM
 SG_ LLHT_Data_12_payload_407_MFR : 375|16@0+ (1,0) [0|65535] "N/A"  ASDM
 SG_ LLHT_Data_12_payload_408_MFR : 391|16@0+ (1,0) [0|65535] "N/A"  ASDM
 SG_ LLHT_Data_12_payload_409_MFR : 407|16@0+ (1,0) [0|65535] "N/A"  ASDM
 SG_ LLHT_Data_12_payload_410_MFR : 423|16@0+ (1,0) [0|65535] "N/A"  ASDM
 SG_ LLHT_Data_12_payload_411_MFR : 439|16@0+ (1,0) [0|65535] "N/A"  ASDM
 SG_ LLHT_Data_12_payload_412_MFR : 455|16@0+ (1,0) [0|65535] "N/A"  ASDM
 SG_ LLHT_Data_12_payload_413_MFR : 471|16@0+ (1,0) [0|65535] "N/A"  ASDM
 SG_ LLHT_Data_12_payload_414_MFR : 487|16@0+ (1,0) [0|65535] "N/A"  ASDM
 SG_ LLHT_Data_12_payload_415_MFR : 503|16@0+ (1,0) [0|65535] "N/A"  ASDM

BO_ 1304 MB79_LLHT_13_MFR: 64 FLRB
 SG_ LLHT_Data_13_payload_416_MFR : 7|16@0+ (1,0) [0|65535] "N/A"  ASDM
 SG_ LLHT_Data_13_payload_417_MFR : 23|16@0+ (1,0) [0|65535] "N/A"  ASDM
 SG_ LLHT_Data_13_payload_418_MFR : 39|16@0+ (1,0) [0|65535] "N/A"  ASDM
 SG_ LLHT_Data_13_payload_419_MFR : 55|16@0+ (1,0) [0|65535] "N/A"  ASDM
 SG_ LLHT_Data_13_payload_420_MFR : 71|16@0+ (1,0) [0|65535] "N/A"  ASDM
 SG_ LLHT_Data_13_payload_421_MFR : 87|16@0+ (1,0) [0|65535] "N/A"  ASDM
 SG_ LLHT_Data_13_payload_422_MFR : 103|16@0+ (1,0) [0|65535] "N/A"  ASDM
 SG_ LLHT_Data_13_payload_423_MFR : 119|16@0+ (1,0) [0|65535] "N/A"  ASDM
 SG_ LLHT_Data_13_payload_424_MFR : 135|16@0+ (1,0) [0|65535] "N/A"  ASDM
 SG_ LLHT_Data_13_payload_425_MFR : 151|16@0+ (1,0) [0|65535] "N/A"  ASDM
 SG_ LLHT_Data_13_payload_426_MFR : 167|16@0+ (1,0) [0|65535] "N/A"  ASDM
 SG_ LLHT_Data_13_payload_427_MFR : 183|16@0+ (1,0) [0|65535] "N/A"  ASDM
 SG_ LLHT_Data_13_payload_428_MFR : 199|16@0+ (1,0) [0|65535] "N/A"  ASDM
 SG_ LLHT_Data_13_payload_429_MFR : 215|16@0+ (1,0) [0|65535] "N/A"  ASDM
 SG_ LLHT_Data_13_payload_430_MFR : 231|16@0+ (1,0) [0|65535] "N/A"  ASDM
 SG_ LLHT_Data_13_payload_431_MFR : 247|16@0+ (1,0) [0|65535] "N/A"  ASDM
 SG_ LLHT_Data_13_payload_432_MFR : 263|16@0+ (1,0) [0|65535] "N/A"  ASDM
 SG_ LLHT_Data_13_payload_433_MFR : 279|16@0+ (1,0) [0|65535] "N/A"  ASDM
 SG_ LLHT_Data_13_payload_434_MFR : 295|16@0+ (1,0) [0|65535] "N/A"  ASDM
 SG_ LLHT_Data_13_payload_435_MFR : 311|16@0+ (1,0) [0|65535] "N/A"  ASDM
 SG_ LLHT_Data_13_payload_436_MFR : 327|16@0+ (1,0) [0|65535] "N/A"  ASDM
 SG_ LLHT_Data_13_payload_437_MFR : 343|16@0+ (1,0) [0|65535] "N/A"  ASDM
 SG_ LLHT_Data_13_payload_438_MFR : 359|16@0+ (1,0) [0|65535] "N/A"  ASDM
 SG_ LLHT_Data_13_payload_439_MFR : 375|16@0+ (1,0) [0|65535] "N/A"  ASDM
 SG_ LLHT_Data_13_payload_440_MFR : 391|16@0+ (1,0) [0|65535] "N/A"  ASDM
 SG_ LLHT_Data_13_payload_441_MFR : 407|16@0+ (1,0) [0|65535] "N/A"  ASDM
 SG_ LLHT_Data_13_payload_442_MFR : 423|16@0+ (1,0) [0|65535] "N/A"  ASDM
 SG_ LLHT_Data_13_payload_443_MFR : 439|16@0+ (1,0) [0|65535] "N/A"  ASDM
 SG_ LLHT_Data_13_payload_444_MFR : 455|16@0+ (1,0) [0|65535] "N/A"  ASDM
 SG_ LLHT_Data_13_payload_445_MFR : 471|16@0+ (1,0) [0|65535] "N/A"  ASDM
 SG_ LLHT_Data_13_payload_446_MFR : 487|16@0+ (1,0) [0|65535] "N/A"  ASDM
 SG_ LLHT_Data_13_payload_447_MFR : 503|16@0+ (1,0) [0|65535] "N/A"  ASDM

BO_ 1305 MB79_LLHT_14_MFR: 64 FLRB
 SG_ LLHT_Data_14_payload_448_MFR : 7|16@0+ (1,0) [0|65535] "N/A"  ASDM
 SG_ LLHT_Data_14_payload_449_MFR : 23|16@0+ (1,0) [0|65535] "N/A"  ASDM
 SG_ LLHT_Data_14_payload_450_MFR : 39|16@0+ (1,0) [0|65535] "N/A"  ASDM
 SG_ LLHT_Data_14_payload_451_MFR : 55|16@0+ (1,0) [0|65535] "N/A"  ASDM
 SG_ LLHT_Data_14_payload_452_MFR : 71|16@0+ (1,0) [0|65535] "N/A"  ASDM
 SG_ LLHT_Data_14_payload_453_MFR : 87|16@0+ (1,0) [0|65535] "N/A"  ASDM
 SG_ LLHT_Data_14_payload_454_MFR : 103|16@0+ (1,0) [0|65535] "N/A"  ASDM
 SG_ LLHT_Data_14_payload_455_MFR : 119|16@0+ (1,0) [0|65535] "N/A"  ASDM
 SG_ LLHT_Data_14_payload_456_MFR : 135|16@0+ (1,0) [0|65535] "N/A"  ASDM
 SG_ LLHT_Data_14_payload_457_MFR : 151|16@0+ (1,0) [0|65535] "N/A"  ASDM
 SG_ LLHT_Data_14_payload_458_MFR : 167|16@0+ (1,0) [0|65535] "N/A"  ASDM
 SG_ LLHT_Data_14_payload_459_MFR : 183|16@0+ (1,0) [0|65535] "N/A"  ASDM
 SG_ LLHT_Data_14_payload_460_MFR : 199|16@0+ (1,0) [0|65535] "N/A"  ASDM
 SG_ LLHT_Data_14_payload_461_MFR : 215|16@0+ (1,0) [0|65535] "N/A"  ASDM
 SG_ LLHT_Data_14_payload_462_MFR : 231|16@0+ (1,0) [0|65535] "N/A"  ASDM
 SG_ LLHT_Data_14_payload_463_MFR : 247|16@0+ (1,0) [0|65535] "N/A"  ASDM
 SG_ LLHT_Data_14_payload_464_MFR : 263|16@0+ (1,0) [0|65535] "N/A"  ASDM
 SG_ LLHT_Data_14_payload_465_MFR : 279|16@0+ (1,0) [0|65535] "N/A"  ASDM
 SG_ LLHT_Data_14_payload_466_MFR : 295|16@0+ (1,0) [0|65535] "N/A"  ASDM
 SG_ LLHT_Data_14_payload_467_MFR : 311|16@0+ (1,0) [0|65535] "N/A"  ASDM
 SG_ LLHT_Data_14_payload_468_MFR : 327|16@0+ (1,0) [0|65535] "N/A"  ASDM
 SG_ LLHT_Data_14_payload_469_MFR : 343|16@0+ (1,0) [0|65535] "N/A"  ASDM
 SG_ LLHT_Data_14_payload_470_MFR : 359|16@0+ (1,0) [0|65535] "N/A"  ASDM
 SG_ LLHT_Data_14_payload_471_MFR : 375|16@0+ (1,0) [0|65535] "N/A"  ASDM
 SG_ LLHT_Data_14_payload_472_MFR : 391|16@0+ (1,0) [0|65535] "N/A"  ASDM
 SG_ LLHT_Data_14_payload_473_MFR : 407|16@0+ (1,0) [0|65535] "N/A"  ASDM
 SG_ LLHT_Data_14_payload_474_MFR : 423|16@0+ (1,0) [0|65535] "N/A"  ASDM
 SG_ LLHT_Data_14_payload_475_MFR : 439|16@0+ (1,0) [0|65535] "N/A"  ASDM
 SG_ LLHT_Data_14_payload_476_MFR : 455|16@0+ (1,0) [0|65535] "N/A"  ASDM
 SG_ LLHT_Data_14_payload_477_MFR : 471|16@0+ (1,0) [0|65535] "N/A"  ASDM
 SG_ LLHT_Data_14_payload_478_MFR : 487|16@0+ (1,0) [0|65535] "N/A"  ASDM
 SG_ LLHT_Data_14_payload_479_MFR : 503|16@0+ (1,0) [0|65535] "N/A"  ASDM

BO_ 1306 MB79_LLHT_15_MFR: 64 FLRB
 SG_ LLHT_Data_15_payload_480_MFR : 7|16@0+ (1,0) [0|65535] "N/A"  ASDM
 SG_ LLHT_Data_15_payload_481_MFR : 23|16@0+ (1,0) [0|65535] "N/A"  ASDM
 SG_ LLHT_Data_15_payload_482_MFR : 39|16@0+ (1,0) [0|65535] "N/A"  ASDM
 SG_ LLHT_Data_15_payload_483_MFR : 55|16@0+ (1,0) [0|65535] "N/A"  ASDM
 SG_ LLHT_Data_15_payload_484_MFR : 71|16@0+ (1,0) [0|65535] "N/A"  ASDM
 SG_ LLHT_Data_15_payload_485_MFR : 87|16@0+ (1,0) [0|65535] "N/A"  ASDM
 SG_ LLHT_Data_15_payload_486_MFR : 103|16@0+ (1,0) [0|65535] "N/A"  ASDM
 SG_ LLHT_Data_15_payload_487_MFR : 119|16@0+ (1,0) [0|65535] "N/A"  ASDM
 SG_ LLHT_Data_15_payload_488_MFR : 135|16@0+ (1,0) [0|65535] "N/A"  ASDM
 SG_ LLHT_Data_15_payload_489_MFR : 151|16@0+ (1,0) [0|65535] "N/A"  ASDM
 SG_ LLHT_Data_15_payload_490_MFR : 167|16@0+ (1,0) [0|65535] "N/A"  ASDM
 SG_ LLHT_Data_15_payload_491_MFR : 183|16@0+ (1,0) [0|65535] "N/A"  ASDM
 SG_ LLHT_Data_15_payload_492_MFR : 199|16@0+ (1,0) [0|65535] "N/A"  ASDM
 SG_ LLHT_Data_15_payload_493_MFR : 215|16@0+ (1,0) [0|65535] "N/A"  ASDM
 SG_ LLHT_Data_15_payload_494_MFR : 231|16@0+ (1,0) [0|65535] "N/A"  ASDM
 SG_ LLHT_Data_15_payload_495_MFR : 247|16@0+ (1,0) [0|65535] "N/A"  ASDM
 SG_ LLHT_Data_15_payload_496_MFR : 263|16@0+ (1,0) [0|65535] "N/A"  ASDM
 SG_ LLHT_Data_15_payload_497_MFR : 279|16@0+ (1,0) [0|65535] "N/A"  ASDM
 SG_ LLHT_Data_15_payload_498_MFR : 295|16@0+ (1,0) [0|65535] "N/A"  ASDM
 SG_ LLHT_Data_15_payload_499_MFR : 311|16@0+ (1,0) [0|65535] "N/A"  ASDM
 SG_ LLHT_Data_15_payload_500_MFR : 327|16@0+ (1,0) [0|65535] "N/A"  ASDM
 SG_ LLHT_Data_15_payload_501_MFR : 343|16@0+ (1,0) [0|65535] "N/A"  ASDM
 SG_ LLHT_Data_15_payload_502_MFR : 359|16@0+ (1,0) [0|65535] "N/A"  ASDM
 SG_ LLHT_Data_15_payload_503_MFR : 375|16@0+ (1,0) [0|65535] "N/A"  ASDM
 SG_ LLHT_Data_15_payload_504_MFR : 391|16@0+ (1,0) [0|65535] "N/A"  ASDM
 SG_ LLHT_Data_15_payload_505_MFR : 407|16@0+ (1,0) [0|65535] "N/A"  ASDM
 SG_ LLHT_Data_15_payload_506_MFR : 423|16@0+ (1,0) [0|65535] "N/A"  ASDM
 SG_ LLHT_Data_15_payload_507_MFR : 439|16@0+ (1,0) [0|65535] "N/A"  ASDM
 SG_ LLHT_Data_15_payload_508_MFR : 455|16@0+ (1,0) [0|65535] "N/A"  ASDM
 SG_ LLHT_Data_15_payload_509_MFR : 471|16@0+ (1,0) [0|65535] "N/A"  ASDM
 SG_ LLHT_Data_15_payload_510_MFR : 487|16@0+ (1,0) [0|65535] "N/A"  ASDM
 SG_ LLHT_Data_15_payload_511_MFR : 503|16@0+ (1,0) [0|65535] "N/A"  ASDM

BO_ 1307 MB79_ASC_CORRECTION_0_MFR: 64 FLRB
 SG_ ASC_Azimuth_Correction_0_MFR : 0|16@1- (0.01,0) [-20|20] "degree"  ASDM
 SG_ ASC_Azimuth_Correction_1_MFR : 16|16@1- (0.01,0) [-20|20] "degree"  ASDM
 SG_ ASC_Azimuth_Correction_2_MFR : 32|16@1- (0.01,0) [-20|20] "degree"  ASDM
 SG_ ASC_Azimuth_Correction_3_MFR : 48|16@1- (0.01,0) [-20|20] "degree"  ASDM
 SG_ ASC_Azimuth_Correction_4_MFR : 64|16@1- (0.01,0) [-20|20] "degree"  ASDM
 SG_ ASC_Azimuth_Correction_5_MFR : 80|16@1- (0.01,0) [-20|20] "degree"  ASDM
 SG_ ASC_Azimuth_Correction_6_MFR : 96|16@1- (0.01,0) [-20|20] "degree"  ASDM
 SG_ ASC_Azimuth_Correction_7_MFR : 112|16@1- (0.01,0) [-20|20] "degree"  ASDM
 SG_ ASC_Azimuth_Correction_8_MFR : 128|16@1- (0.01,0) [-20|20] "degree"  ASDM
 SG_ ASC_Azimuth_Correction_9_MFR : 144|16@1- (0.01,0) [-20|20] "degree"  ASDM
 SG_ ASC_Azimuth_Correction_10_MFR : 160|16@1- (0.01,0) [-20|20] "degree"  ASDM
 SG_ ASC_Azimuth_Correction_11_MFR : 176|16@1- (0.01,0) [-20|20] "degree"  ASDM
 SG_ ASC_Azimuth_Correction_12_MFR : 192|16@1- (0.01,0) [-20|20] "degree"  ASDM
 SG_ ASC_Azimuth_Correction_13_MFR : 208|16@1- (0.01,0) [-20|20] "degree"  ASDM
 SG_ ASC_Azimuth_Correction_14_MFR : 224|16@1- (0.01,0) [-20|20] "degree"  ASDM
 SG_ ASC_Azimuth_Correction_15_MFR : 240|16@1- (0.01,0) [-20|20] "degree"  ASDM
 SG_ ASC_Azimuth_Correction_16_MFR : 256|16@1- (0.01,0) [-20|20] "degree"  ASDM
 SG_ ASC_Azimuth_Correction_17_MFR : 272|16@1- (0.01,0) [-20|20] "degree"  ASDM
 SG_ ASC_Azimuth_Correction_18_MFR : 288|16@1- (0.01,0) [-20|20] "degree"  ASDM
 SG_ ASC_Azimuth_Correction_19_MFR : 304|16@1- (0.01,0) [-20|20] "degree"  ASDM
 SG_ ASC_Azimuth_Correction_20_MFR : 320|16@1- (0.01,0) [-20|20] "degree"  ASDM
 SG_ ASC_Azimuth_Correction_21_MFR : 336|16@1- (0.01,0) [-20|20] "degree"  ASDM
 SG_ ASC_Azimuth_Correction_22_MFR : 352|16@1- (0.01,0) [-20|20] "degree"  ASDM
 SG_ ASC_Azimuth_Correction_23_MFR : 368|16@1- (0.01,0) [-20|20] "degree"  ASDM
 SG_ ASC_Azimuth_Correction_24_MFR : 384|16@1- (0.01,0) [-20|20] "degree"  ASDM
 SG_ ASC_Azimuth_Correction_25_MFR : 400|16@1- (0.01,0) [-20|20] "degree"  ASDM
 SG_ ASC_Azimuth_Correction_26_MFR : 416|16@1- (0.01,0) [-20|20] "degree"  ASDM
 SG_ ASC_Azimuth_Correction_27_MFR : 432|16@1- (0.01,0) [-20|20] "degree"  ASDM
 SG_ ASC_Azimuth_Correction_28_MFR : 448|16@1- (0.01,0) [-20|20] "degree"  ASDM
 SG_ ASC_Azimuth_Correction_29_MFR : 464|16@1- (0.01,0) [-20|20] "degree"  ASDM
 SG_ ASC_Azimuth_Correction_30_MFR : 480|16@1- (0.01,0) [-20|20] "degree"  ASDM
 SG_ ASC_Azimuth_Correction_31_MFR : 496|16@1- (0.01,0) [-20|20] "degree"  ASDM

BO_ 1308 MB79_ASC_CORRECTION_1_MFR: 64 FLRB
 SG_ ASC_Azimuth_Correction_32_MFR : 0|16@1- (0.01,0) [-20|20] "degree"  ASDM
 SG_ ASC_Azimuth_Correction_33_MFR : 16|16@1- (0.01,0) [-20|20] "degree"  ASDM
 SG_ ASC_Azimuth_Correction_34_MFR : 32|16@1- (0.01,0) [-20|20] "degree"  ASDM
 SG_ ASC_Azimuth_Correction_35_MFR : 48|16@1- (0.01,0) [-20|20] "degree"  ASDM
 SG_ ASC_Azimuth_Correction_36_MFR : 64|16@1- (0.01,0) [-20|20] "degree"  ASDM
 SG_ ASC_Azimuth_Correction_37_MFR : 80|16@1- (0.01,0) [-20|20] "degree"  ASDM
 SG_ ASC_Azimuth_Correction_38_MFR : 96|16@1- (0.01,0) [-20|20] "degree"  ASDM
 SG_ ASC_Azimuth_Correction_39_MFR : 112|16@1- (0.01,0) [-20|20] "degree"  ASDM
 SG_ ASC_Azimuth_Correction_40_MFR : 128|16@1- (0.01,0) [-20|20] "degree"  ASDM
 SG_ ASC_Azimuth_Correction_41_MFR : 144|16@1- (0.01,0) [-20|20] "degree"  ASDM
 SG_ ASC_Azimuth_Correction_42_MFR : 160|16@1- (0.01,0) [-20|20] "degree"  ASDM
 SG_ ASC_Azimuth_Correction_43_MFR : 176|16@1- (0.01,0) [-20|20] "degree"  ASDM
 SG_ ASC_Azimuth_Correction_44_MFR : 192|16@1- (0.01,0) [-20|20] "degree"  ASDM
 SG_ ASC_Azimuth_Correction_45_MFR : 208|16@1- (0.01,0) [-20|20] "degree"  ASDM
 SG_ ASC_Azimuth_Correction_46_MFR : 224|16@1- (0.01,0) [-20|20] "degree"  ASDM
 SG_ ASC_Azimuth_Correction_47_MFR : 240|16@1- (0.01,0) [-20|20] "degree"  ASDM
 SG_ ASC_Azimuth_Correction_48_MFR : 256|16@1- (0.01,0) [-20|20] "degree"  ASDM
 SG_ ASC_Azimuth_Correction_49_MFR : 272|16@1- (0.01,0) [-20|20] "degree"  ASDM
 SG_ ASC_Azimuth_Correction_50_MFR : 288|16@1- (0.01,0) [-20|20] "degree"  ASDM
 SG_ ASC_Azimuth_Correction_51_MFR : 304|16@1- (0.01,0) [-20|20] "degree"  ASDM
 SG_ ASC_Azimuth_Correction_52_MFR : 320|16@1- (0.01,0) [-20|20] "degree"  ASDM
 SG_ ASC_Azimuth_Correction_53_MFR : 336|16@1- (0.01,0) [-20|20] "degree"  ASDM
 SG_ ASC_Azimuth_Correction_54_MFR : 352|16@1- (0.01,0) [-20|20] "degree"  ASDM
 SG_ ASC_Azimuth_Correction_55_MFR : 368|16@1- (0.01,0) [-20|20] "degree"  ASDM
 SG_ ASC_Azimuth_Correction_56_MFR : 384|16@1- (0.01,0) [-20|20] "degree"  ASDM
 SG_ ASC_Azimuth_Correction_57_MFR : 400|16@1- (0.01,0) [-20|20] "degree"  ASDM
 SG_ ASC_Azimuth_Correction_58_MFR : 416|16@1- (0.01,0) [-20|20] "degree"  ASDM
 SG_ ASC_Azimuth_Correction_59_MFR : 432|16@1- (0.01,0) [-20|20] "degree"  ASDM
 SG_ ASC_Azimuth_Correction_60_MFR : 448|16@1- (0.01,0) [-20|20] "degree"  ASDM
 SG_ ASC_Azimuth_Correction_61_MFR : 464|16@1- (0.01,0) [-20|20] "degree"  ASDM
 SG_ ASC_Azimuth_Correction_62_MFR : 480|16@1- (0.01,0) [-20|20] "degree"  ASDM
 SG_ ASC_Azimuth_Correction_63_MFR : 496|16@1- (0.01,0) [-20|20] "degree"  ASDM

BO_ 1309 MB79_ASC_CORRECTION_2_MFR: 64 FLRB
 SG_ ASC_Azimuth_Correction_64_MFR : 0|16@1- (0.01,0) [-20|20] "degree"  ASDM
 SG_ ASC_Azimuth_Correction_65_MFR : 16|16@1- (0.01,0) [-20|20] "degree"  ASDM
 SG_ ASC_Azimuth_Correction_66_MFR : 32|16@1- (0.01,0) [-20|20] "degree"  ASDM
 SG_ ASC_Azimuth_Correction_67_MFR : 48|16@1- (0.01,0) [-20|20] "degree"  ASDM
 SG_ ASC_Azimuth_Correction_68_MFR : 64|16@1- (0.01,0) [-20|20] "degree"  ASDM
 SG_ ASC_Azimuth_Correction_69_MFR : 80|16@1- (0.01,0) [-20|20] "degree"  ASDM
 SG_ ASC_Azimuth_Correction_70_MFR : 96|16@1- (0.01,0) [-20|20] "degree"  ASDM
 SG_ ASC_Azimuth_Correction_71_MFR : 112|16@1- (0.01,0) [-20|20] "degree"  ASDM
 SG_ ASC_Azimuth_Correction_72_MFR : 128|16@1- (0.01,0) [-20|20] "degree"  ASDM
 SG_ ASC_Azimuth_Correction_73_MFR : 144|16@1- (0.01,0) [-20|20] "degree"  ASDM
 SG_ ASC_Azimuth_Correction_74_MFR : 160|16@1- (0.01,0) [-20|20] "degree"  ASDM
 SG_ ASC_Azimuth_Correction_75_MFR : 176|16@1- (0.01,0) [-20|20] "degree"  ASDM
 SG_ ASC_Azimuth_Correction_76_MFR : 192|16@1- (0.01,0) [-20|20] "degree"  ASDM
 SG_ ASC_Azimuth_Correction_77_MFR : 208|16@1- (0.01,0) [-20|20] "degree"  ASDM
 SG_ ASC_Azimuth_Correction_78_MFR : 224|16@1- (0.01,0) [-20|20] "degree"  ASDM
 SG_ ASC_Azimuth_Correction_79_MFR : 240|16@1- (0.01,0) [-20|20] "degree"  ASDM
 SG_ ASC_Azimuth_Correction_80_MFR : 256|16@1- (0.01,0) [-20|20] "degree"  ASDM
 SG_ ASC_Azimuth_Correction_81_MFR : 272|16@1- (0.01,0) [-20|20] "degree"  ASDM
 SG_ ASC_Azimuth_Correction_82_MFR : 288|16@1- (0.01,0) [-20|20] "degree"  ASDM
 SG_ ASC_Azimuth_Correction_83_MFR : 304|16@1- (0.01,0) [-20|20] "degree"  ASDM
 SG_ ASC_Azimuth_Correction_84_MFR : 320|16@1- (0.01,0) [-20|20] "degree"  ASDM
 SG_ ASC_Azimuth_Correction_85_MFR : 336|16@1- (0.01,0) [-20|20] "degree"  ASDM
 SG_ ASC_Azimuth_Correction_86_MFR : 352|16@1- (0.01,0) [-20|20] "degree"  ASDM
 SG_ ASC_Azimuth_Correction_87_MFR : 368|16@1- (0.01,0) [-20|20] "degree"  ASDM
 SG_ ASC_Azimuth_Correction_88_MFR : 384|16@1- (0.01,0) [-20|20] "degree"  ASDM
 SG_ ASC_Azimuth_Correction_89_MFR : 400|16@1- (0.01,0) [-20|20] "degree"  ASDM
 SG_ ASC_Azimuth_Correction_90_MFR : 416|16@1- (0.01,0) [-20|20] "degree"  ASDM
 SG_ ASC_Azimuth_Correction_91_MFR : 432|16@1- (0.01,0) [-20|20] "degree"  ASDM
 SG_ ASC_Azimuth_Correction_92_MFR : 448|16@1- (0.01,0) [-20|20] "degree"  ASDM
 SG_ ASC_Azimuth_Correction_93_MFR : 464|16@1- (0.01,0) [-20|20] "degree"  ASDM
 SG_ ASC_Azimuth_Correction_94_MFR : 480|16@1- (0.01,0) [-20|20] "degree"  ASDM
 SG_ ASC_Azimuth_Correction_95_MFR : 496|16@1- (0.01,0) [-20|20] "degree"  ASDM

BO_ 1310 MB79_ASC_CORRECTION_3_MFR: 64 FLRB
 SG_ ASC_Azimuth_Correction_96_MFR : 0|16@1- (0.01,0) [-20|20] "degree"  ASDM
 SG_ ASC_Azimuth_Correction_97_MFR : 16|16@1- (0.01,0) [-20|20] "degree"  ASDM
 SG_ ASC_Azimuth_Correction_98_MFR : 32|16@1- (0.01,0) [-20|20] "degree"  ASDM
 SG_ ASC_Azimuth_Correction_99_MFR : 48|16@1- (0.01,0) [-20|20] "degree"  ASDM
 SG_ ASC_Azimuth_Correction_100_MFR : 64|16@1- (0.01,0) [-20|20] "degree"  ASDM
 SG_ ASC_Azimuth_Correction_101_MFR : 80|16@1- (0.01,0) [-20|20] "degree"  ASDM
 SG_ ASC_Azimuth_Correction_102_MFR : 96|16@1- (0.01,0) [-20|20] "degree"  ASDM
 SG_ ASC_Azimuth_Correction_103_MFR : 112|16@1- (0.01,0) [-20|20] "degree"  ASDM
 SG_ ASC_Azimuth_Correction_104_MFR : 128|16@1- (0.01,0) [-20|20] "degree"  ASDM
 SG_ ASC_Azimuth_Correction_105_MFR : 144|16@1- (0.01,0) [-20|20] "degree"  ASDM
 SG_ ASC_Azimuth_Correction_106_MFR : 160|16@1- (0.01,0) [-20|20] "degree"  ASDM
 SG_ ASC_Azimuth_Correction_107_MFR : 176|16@1- (0.01,0) [-20|20] "degree"  ASDM
 SG_ ASC_Azimuth_Correction_108_MFR : 192|16@1- (0.01,0) [-20|20] "degree"  ASDM
 SG_ ASC_Azimuth_Correction_109_MFR : 208|16@1- (0.01,0) [-20|20] "degree"  ASDM
 SG_ ASC_Azimuth_Correction_110_MFR : 224|16@1- (0.01,0) [-20|20] "degree"  ASDM
 SG_ ASC_Azimuth_Correction_111_MFR : 240|16@1- (0.01,0) [-20|20] "degree"  ASDM
 SG_ ASC_Azimuth_Correction_112_MFR : 256|16@1- (0.01,0) [-20|20] "degree"  ASDM
 SG_ ASC_Azimuth_Correction_113_MFR : 272|16@1- (0.01,0) [-20|20] "degree"  ASDM
 SG_ ASC_Azimuth_Correction_114_MFR : 288|16@1- (0.01,0) [-20|20] "degree"  ASDM
 SG_ ASC_Azimuth_Correction_115_MFR : 304|16@1- (0.01,0) [-20|20] "degree"  ASDM
 SG_ ASC_Azimuth_Correction_116_MFR : 320|16@1- (0.01,0) [-20|20] "degree"  ASDM
 SG_ ASC_Azimuth_Correction_117_MFR : 336|16@1- (0.01,0) [-20|20] "degree"  ASDM
 SG_ ASC_Azimuth_Correction_118_MFR : 352|16@1- (0.01,0) [-20|20] "degree"  ASDM
 SG_ ASC_Azimuth_Correction_119_MFR : 368|16@1- (0.01,0) [-20|20] "degree"  ASDM
 SG_ ASC_Azimuth_Correction_120_MFR : 384|16@1- (0.01,0) [-20|20] "degree"  ASDM
 SG_ ASC_Azimuth_Correction_121_MFR : 400|16@1- (0.01,0) [-20|20] "degree"  ASDM
 SG_ ASC_Azimuth_Correction_122_MFR : 416|16@1- (0.01,0) [-20|20] "degree"  ASDM
 SG_ ASC_Azimuth_Correction_123_MFR : 432|16@1- (0.01,0) [-20|20] "degree"  ASDM
 SG_ ASC_Azimuth_Correction_124_MFR : 448|16@1- (0.01,0) [-20|20] "degree"  ASDM
 SG_ ASC_Azimuth_Correction_125_MFR : 464|16@1- (0.01,0) [-20|20] "degree"  ASDM
 SG_ ASC_Azimuth_Correction_126_MFR : 480|16@1- (0.01,0) [-20|20] "degree"  ASDM
 SG_ ASC_Azimuth_Correction_127_MFR : 496|16@1- (0.01,0) [-20|20] "degree"  ASDM

BO_ 1311 MB79_ASC_CORRECTION_4_MFR: 64 FLRB
 SG_ ASC_Azimuth_Correction_128_MFR : 0|16@1- (0.01,0) [-20|20] "degree"  ASDM
 SG_ ASC_Azimuth_Correction_129_MFR : 16|16@1- (0.01,0) [-20|20] "degree"  ASDM
 SG_ ASC_Azimuth_Correction_130_MFR : 32|16@1- (0.01,0) [-20|20] "degree"  ASDM
 SG_ ASC_Azimuth_Correction_131_MFR : 48|16@1- (0.01,0) [-20|20] "degree"  ASDM
 SG_ ASC_Azimuth_Correction_132_MFR : 64|16@1- (0.01,0) [-20|20] "degree"  ASDM
 SG_ ASC_Azimuth_Correction_133_MFR : 80|16@1- (0.01,0) [-20|20] "degree"  ASDM
 SG_ ASC_Azimuth_Correction_134_MFR : 96|16@1- (0.01,0) [-20|20] "degree"  ASDM
 SG_ ASC_Azimuth_Correction_135_MFR : 112|16@1- (0.01,0) [-20|20] "degree"  ASDM
 SG_ ASC_Azimuth_Correction_136_MFR : 128|16@1- (0.01,0) [-20|20] "degree"  ASDM
 SG_ ASC_Azimuth_Correction_137_MFR : 144|16@1- (0.01,0) [-20|20] "degree"  ASDM
 SG_ ASC_Azimuth_Correction_138_MFR : 160|16@1- (0.01,0) [-20|20] "degree"  ASDM
 SG_ ASC_Azimuth_Correction_139_MFR : 176|16@1- (0.01,0) [-20|20] "degree"  ASDM
 SG_ ASC_Azimuth_Correction_140_MFR : 192|16@1- (0.01,0) [-20|20] "degree"  ASDM
 SG_ ASC_Azimuth_Correction_141_MFR : 208|16@1- (0.01,0) [-20|20] "degree"  ASDM
 SG_ ASC_Azimuth_Correction_142_MFR : 224|16@1- (0.01,0) [-20|20] "degree"  ASDM
 SG_ ASC_Azimuth_Correction_143_MFR : 240|16@1- (0.01,0) [-20|20] "degree"  ASDM
 SG_ ASC_Azimuth_Correction_144_MFR : 256|16@1- (0.01,0) [-20|20] "degree"  ASDM
 SG_ ASC_Azimuth_Correction_145_MFR : 272|16@1- (0.01,0) [-20|20] "degree"  ASDM
 SG_ ASC_Azimuth_Correction_146_MFR : 288|16@1- (0.01,0) [-20|20] "degree"  ASDM
 SG_ ASC_Azimuth_Correction_147_MFR : 304|16@1- (0.01,0) [-20|20] "degree"  ASDM
 SG_ ASC_Azimuth_Correction_148_MFR : 320|16@1- (0.01,0) [-20|20] "degree"  ASDM
 SG_ ASC_Azimuth_Correction_149_MFR : 336|16@1- (0.01,0) [-20|20] "degree"  ASDM
 SG_ ASC_Azimuth_Correction_150_MFR : 352|16@1- (0.01,0) [-20|20] "degree"  ASDM
 SG_ ASC_Azimuth_Correction_151_MFR : 368|16@1- (0.01,0) [-20|20] "degree"  ASDM
 SG_ ASC_Azimuth_Correction_152_MFR : 384|16@1- (0.01,0) [-20|20] "degree"  ASDM
 SG_ ASC_Azimuth_Correction_153_MFR : 400|16@1- (0.01,0) [-20|20] "degree"  ASDM
 SG_ ASC_Azimuth_Correction_154_MFR : 416|16@1- (0.01,0) [-20|20] "degree"  ASDM
 SG_ ASC_Azimuth_Correction_155_MFR : 432|16@1- (0.01,0) [-20|20] "degree"  ASDM
 SG_ ASC_Azimuth_Correction_156_MFR : 448|16@1- (0.01,0) [-20|20] "degree"  ASDM
 SG_ ASC_Azimuth_Correction_157_MFR : 464|16@1- (0.01,0) [-20|20] "degree"  ASDM
 SG_ ASC_Azimuth_Correction_158_MFR : 480|16@1- (0.01,0) [-20|20] "degree"  ASDM
 SG_ ASC_Azimuth_Correction_159_MFR : 496|16@1- (0.01,0) [-20|20] "degree"  ASDM

BO_ 1536 MB79_TEST_Message_PC_FLRB: 64 ASDM
 SG_ Testing_Mode_ID_ASDM_MFR : 7|16@0+ (1,0) [0|65535] "N/A"  FLRB
 SG_ Testing_Mode_SubID_ASDM_MFR : 23|8@0+ (1,0) [0|255] "N/A"  FLRB
 SG_ Testing_Mode_Param_0_ASDM_MFR : 31|8@0+ (1,0) [0|255] "N/A"  FLRB
 SG_ Testing_Mode_Param_1_ASDM_MFR : 39|8@0+ (1,0) [0|255] "N/A"  FLRB
 SG_ Testing_Mode_Param_2_ASDM_MFR : 47|8@0+ (1,0) [0|255] "N/A"  FLRB
 SG_ Testing_Mode_Param_3_ASDM_MFR : 55|8@0+ (1,0) [0|255] "N/A"  FLRB
 SG_ Testing_Mode_Param_4_ASDM_MFR : 63|8@0+ (1,0) [0|255] "N/A"  FLRB
 SG_ Testing_Mode_Param_5_ASDM_MFR : 71|8@0+ (1,0) [0|255] "N/A"  FLRB
 SG_ Testing_Mode_Param_6_ASDM_MFR : 79|8@0+ (1,0) [0|255] "N/A"  FLRB
 SG_ Testing_Mode_Param_7_ASDM_MFR : 87|8@0+ (1,0) [0|255] "N/A"  FLRB
 SG_ Testing_Mode_Param_8_ASDM_MFR : 95|8@0+ (1,0) [0|255] "N/A"  FLRB
 SG_ Testing_Mode_Param_9_ASDM_MFR : 103|8@0+ (1,0) [0|255] "N/A"  FLRB
 SG_ Testing_Mode_Param_10_ASDM_MFR : 111|8@0+ (1,0) [0|255] "N/A"  FLRB
 SG_ Testing_Mode_Param_11_ASDM_MFR : 119|8@0+ (1,0) [0|255] "N/A"  FLRB
 SG_ Testing_Mode_Param_12_ASDM_MFR : 127|8@0+ (1,0) [0|255] "N/A"  FLRB
 SG_ Testing_Mode_Param_13_ASDM_MFR : 135|8@0+ (1,0) [0|255] "N/A"  FLRB
 SG_ Testing_Mode_Param_14_ASDM_MFR : 143|8@0+ (1,0) [0|255] "N/A"  FLRB
 SG_ Testing_Mode_Param_15_ASDM_MFR : 151|8@0+ (1,0) [0|255] "N/A"  FLRB
 SG_ Testing_Mode_Param_16_ASDM_MFR : 159|8@0+ (1,0) [0|255] "N/A"  FLRB
 SG_ Testing_Mode_Param_17_ASDM_MFR : 167|8@0+ (1,0) [0|255] "N/A"  FLRB
 SG_ Testing_Mode_Param_18_ASDM_MFR : 175|8@0+ (1,0) [0|255] "N/A"  FLRB
 SG_ Testing_Mode_Param_19_ASDM_MFR : 183|8@0+ (1,0) [0|255] "N/A"  FLRB
 SG_ Testing_Mode_Param_20_ASDM_MFR : 191|8@0+ (1,0) [0|255] "N/A"  FLRB
 SG_ Testing_Mode_Param_21_ASDM_MFR : 199|8@0+ (1,0) [0|255] "N/A"  FLRB
 SG_ Testing_Mode_Param_22_ASDM_MFR : 207|8@0+ (1,0) [0|255] "N/A"  FLRB
 SG_ Testing_Mode_Param_23_ASDM_MFR : 215|8@0+ (1,0) [0|255] "N/A"  FLRB
 SG_ Testing_Mode_Param_24_ASDM_MFR : 223|8@0+ (1,0) [0|255] "N/A"  FLRB
 SG_ Testing_Mode_Param_25_ASDM_MFR : 231|8@0+ (1,0) [0|255] "N/A"  FLRB
 SG_ Testing_Mode_Param_26_ASDM_MFR : 239|8@0+ (1,0) [0|255] "N/A"  FLRB
 SG_ Testing_Mode_Param_27_ASDM_MFR : 247|8@0+ (1,0) [0|255] "N/A"  FLRB
 SG_ Testing_Mode_Param_28_ASDM_MFR : 255|8@0+ (1,0) [0|255] "N/A"  FLRB
 SG_ Testing_Mode_Param_29_ASDM_MFR : 263|8@0+ (1,0) [0|255] "N/A"  FLRB
 SG_ Testing_Mode_Param_30_ASDM_MFR : 271|8@0+ (1,0) [0|255] "N/A"  FLRB
 SG_ Testing_Mode_Param_31_ASDM_MFR : 279|8@0+ (1,0) [0|255] "N/A"  FLRB
 SG_ Testing_Mode_Param_32_ASDM_MFR : 287|8@0+ (1,0) [0|255] "N/A"  FLRB
 SG_ Testing_Mode_Param_33_ASDM_MFR : 295|8@0+ (1,0) [0|255] "N/A"  FLRB
 SG_ Testing_Mode_Param_34_ASDM_MFR : 303|8@0+ (1,0) [0|255] "N/A"  FLRB
 SG_ Testing_Mode_Param_35_ASDM_MFR : 311|8@0+ (1,0) [0|255] "N/A"  FLRB
 SG_ Testing_Mode_Param_36_ASDM_MFR : 319|8@0+ (1,0) [0|255] "N/A"  FLRB
 SG_ Testing_Mode_Param_37_ASDM_MFR : 327|8@0+ (1,0) [0|255] "N/A"  FLRB
 SG_ Testing_Mode_Param_38_ASDM_MFR : 335|8@0+ (1,0) [0|255] "N/A"  FLRB
 SG_ Testing_Mode_Param_39_ASDM_MFR : 343|8@0+ (1,0) [0|255] "N/A"  FLRB
 SG_ Testing_Mode_Param_40_ASDM_MFR : 351|8@0+ (1,0) [0|255] "N/A"  FLRB
 SG_ Testing_Mode_Param_41_ASDM_MFR : 359|8@0+ (1,0) [0|255] "N/A"  FLRB
 SG_ Testing_Mode_Param_42_ASDM_MFR : 367|8@0+ (1,0) [0|255] "N/A"  FLRB
 SG_ Testing_Mode_Param_43_ASDM_MFR : 375|8@0+ (1,0) [0|255] "N/A"  FLRB
 SG_ Testing_Mode_Param_44_ASDM_MFR : 383|8@0+ (1,0) [0|255] "N/A"  FLRB
 SG_ Testing_Mode_Param_45_ASDM_MFR : 391|8@0+ (1,0) [0|255] "N/A"  FLRB
 SG_ Testing_Mode_Param_46_ASDM_MFR : 399|8@0+ (1,0) [0|255] "N/A"  FLRB
 SG_ Testing_Mode_Param_47_ASDM_MFR : 407|8@0+ (1,0) [0|255] "N/A"  FLRB
 SG_ Testing_Mode_Param_48_ASDM_MFR : 415|8@0+ (1,0) [0|255] "N/A"  FLRB
 SG_ Testing_Mode_Param_49_ASDM_MFR : 423|8@0+ (1,0) [0|255] "N/A"  FLRB
 SG_ Testing_Mode_Param_50_ASDM_MFR : 431|8@0+ (1,0) [0|255] "N/A"  FLRB
 SG_ Testing_Mode_Param_51_ASDM_MFR : 439|8@0+ (1,0) [0|255] "N/A"  FLRB
 SG_ Testing_Mode_Param_52_ASDM_MFR : 447|8@0+ (1,0) [0|255] "N/A"  FLRB
 SG_ Testing_Mode_Param_53_ASDM_MFR : 455|8@0+ (1,0) [0|255] "N/A"  FLRB
 SG_ Testing_Mode_Param_54_ASDM_MFR : 463|8@0+ (1,0) [0|255] "N/A"  FLRB
 SG_ Testing_Mode_Param_55_ASDM_MFR : 471|8@0+ (1,0) [0|255] "N/A"  FLRB
 SG_ Testing_Mode_Param_56_ASDM_MFR : 479|8@0+ (1,0) [0|255] "N/A"  FLRB
 SG_ Testing_Mode_Param_57_ASDM_MFR : 487|8@0+ (1,0) [0|255] "N/A"  FLRB
 SG_ Testing_Mode_Param_58_ASDM_MFR : 495|8@0+ (1,0) [0|255] "N/A"  FLRB
 SG_ Testing_Mode_Param_59_ASDM_MFR : 503|8@0+ (1,0) [0|255] "N/A"  FLRB
 SG_ Testing_Mode_Param_60_ASDM_MFR : 511|8@0+ (1,0) [0|255] "N/A"  FLRB

// Node Comments
CM_ BU_ FLRB "Forward Looking Radar B";
CM_ BO_ 416 "used for network Management";
CM_ SG_ 416 NM_Sig_0_ASDM_MFR "Network Manegement Signal";
CM_ SG_ 416 NM_Sig_1_ASDM_MFR "Network Manegement Signal";
CM_ SG_ 416 NM_Sig_2_ASDM_MFR "Network Manegement Signal";
CM_ SG_ 416 NM_Sig_3_ASDM_MFR "Network Manegement Signal";
CM_ SG_ 416 NM_Sig_4_ASDM_MFR "Network Manegement Signal";
CM_ SG_ 416 NM_Sig_5_ASDM_MFR "Network Manegement Signal";
CM_ SG_ 416 NM_Sig_6_ASDM_MFR "Network Manegement Signal";
CM_ SG_ 416 NM_Sig_7_ASDM_MFR "Network Manegement Signal";
CM_ BO_ 1281 "ECU_WAKE_UP";
CM_ BO_ 1030 "This MSG is Received by sensor for XCP calibration";
CM_ SG_ 1030 XCP_Master_0_ASDM_MFR "This signal is received by sensor for XCP calibration";
CM_ SG_ 1030 XCP_Master_1_ASDM_MFR "This signal is received by sensor for XCP calibration";
CM_ SG_ 1030 XCP_Master_2_ASDM_MFR "This signal is received by sensor for XCP calibration";
CM_ SG_ 1030 XCP_Master_3_ASDM_MFR "This signal is received by sensor for XCP calibration";
CM_ SG_ 1030 XCP_Master_4_ASDM_MFR "This signal is received by sensor for XCP calibration";
CM_ SG_ 1030 XCP_Master_5_ASDM_MFR "This signal is received by sensor for XCP calibration";
CM_ SG_ 1030 XCP_Master_6_ASDM_MFR "This signal is received by sensor for XCP calibration";
CM_ SG_ 1030 XCP_Master_7_ASDM_MFR "This signal is received by sensor for XCP calibration";
CM_ BO_ 1031 "This MSG is Sent by sensor for XCP calibration";
CM_ SG_ 1031 XCP_Slave_0_MFR "This signal is sent by sensor for XCP calibration";
CM_ SG_ 1031 XCP_Slave_1_MFR "This signal is sent by sensor for XCP calibration";
CM_ SG_ 1031 XCP_Slave_2_MFR "This signal is sent by sensor for XCP calibration";
CM_ SG_ 1031 XCP_Slave_3_MFR "This signal is sent by sensor for XCP calibration";
CM_ SG_ 1031 XCP_Slave_4_MFR "This signal is sent by sensor for XCP calibration";
CM_ SG_ 1031 XCP_Slave_5_MFR "This signal is sent by sensor for XCP calibration";
CM_ SG_ 1031 XCP_Slave_6_MFR "This signal is sent by sensor for XCP calibration";
CM_ SG_ 1031 XCP_Slave_7_MFR "This signal is sent by sensor for XCP calibration";
CM_ BO_ 3 "Time Sync Message used by CanTSync for Syncing FR with DSF";
CM_ BO_ 257 "Detection Header Message";
CM_ SG_ 257 CycleNumber_MFR "AliveCounter/MCC";
CM_ SG_ 257 FC1MHz1_MFR "two bytes reserve as u16 FC1MHz codes the center frequency as 1MHz steps where Actual_FC =  60GHz +  FC1MHz * 1MHz  (we cover then 60GHz to 125GHz  )";
CM_ BO_ 304 "DetectionList";
CM_ BO_ 305 "DetectionList";
CM_ BO_ 306 "DetectionList";
CM_ BO_ 307 "DetectionList";
CM_ BO_ 308 "DetectionList";
CM_ BO_ 309 "DetectionList";
CM_ BO_ 310 "DetectionList";
CM_ BO_ 311 "DetectionList";
CM_ BO_ 312 "DetectionList";
CM_ BO_ 313 "DetectionList";
CM_ BO_ 314 "DetectionList";
CM_ BO_ 315 "DetectionList";
CM_ BO_ 316 "DetectionList";
CM_ BO_ 317 "DetectionList";
CM_ BO_ 318 "DetectionList";
CM_ BO_ 319 "DetectionList";
CM_ BO_ 320 "DetectionList";
CM_ BO_ 321 "DetectionList";
CM_ BO_ 322 "DetectionList";
CM_ BO_ 323 "DetectionList";
CM_ BO_ 324 "DetectionList";
CM_ BO_ 325 "DetectionList";
CM_ BO_ 326 "DetectionList";
CM_ BO_ 327 "DetectionList";
CM_ BO_ 328 "DetectionList";
CM_ BO_ 329 "DetectionList";
CM_ BO_ 330 "DetectionList";
CM_ BO_ 331 "DetectionList";
CM_ BO_ 332 "DetectionList";
CM_ BO_ 333 "DetectionList";
CM_ BO_ 334 "DetectionList";
CM_ BO_ 335 "DetectionList";
CM_ BO_ 336 "DetectionList";
CM_ BO_ 337 "DetectionList";
CM_ BO_ 338 "DetectionList";
CM_ BO_ 339 "DetectionList";
CM_ BO_ 340 "DetectionList";
CM_ BO_ 341 "DetectionList";
CM_ BO_ 342 "DetectionList";
CM_ BO_ 343 "DetectionList";
CM_ BO_ 344 "DetectionList";
CM_ BO_ 345 "DetectionList";
CM_ BO_ 346 "DetectionList";
CM_ BO_ 347 "DetectionList";
CM_ BO_ 348 "DetectionList";
CM_ BO_ 349 "DetectionList";
CM_ BO_ 350 "DetectionList";
CM_ BO_ 351 "DetectionList";
CM_ BO_ 352 "DetectionList";
CM_ BO_ 353 "DetectionList";
CM_ BO_ 354 "DetectionList";
CM_ BO_ 355 "DetectionList";
CM_ BO_ 356 "DetectionList";
CM_ BO_ 357 "DetectionList";
CM_ BO_ 358 "DetectionList";
CM_ BO_ 359 "DetectionList";
CM_ BO_ 769 "Vehicle Data Message used by comh to recieve the Vehicle Data";
CM_ SG_ 769 HostGear_ASDM "Host gear shift";
CM_ BO_ 784 "Processing Profil Message used by app to send Profiling Data To PC when available";
CM_ BO_ 785 "AASC Result";
CM_ BO_ 786 "Send the Voltage state to PC";
CM_ BO_ 787 "Send Eagle and MCU Tempreture to PC";
CM_ BO_ 788 "Versions Message used by comh to send SW versions";
CM_ SG_ 788 LCP2_Data_Ver_Major_MFR "LCP2 version";
CM_ SG_ 788 LCP2_Data_Ver_Minor_MFR "LCP2 version";
CM_ SG_ 788 LCP2_Design_Ver_Major_MFR "LCP2 version";
CM_ SG_ 788 LCP2_Design_Ver_Minor_MFR "LCP2 version";
CM_ SG_ 788 LCP3_SR_Ver_Major_MFR "LCP3 Version Major - Parking mode (Short Range)";
CM_ SG_ 788 LCP3_SR_Ver_Minor_MFR "LCP3 Version Minor - Parking mode (Short Range)";
CM_ SG_ 788 LCP3_SR_Ver_Build_MFR "LCP3 Version Build - Parking mode (Short Range)";
CM_ SG_ 788 LCP3_LR_Ver_Major_MFR "LCP3 Version Major - Driving mode (Long Range)";
CM_ SG_ 788 LCP3_LR_Ver_Minor_MFR "LCP3 Version Minor - Driving mode (Long Range)";
CM_ SG_ 788 LCP3_LR_Ver_Build_MFR "LCP3 Version Build - Driving mode (Long Range)";
CM_ BO_ 1290 "LLST Response";
CM_ BO_ 1291 "LLST Response";
CM_ BO_ 1292 "LLST Response";
CM_ BO_ 1293 "LLST Response";
CM_ BO_ 1294 "LLST Response";
CM_ BO_ 1295 "LLST Response";
CM_ BO_ 1296 "LLST Response";
CM_ BO_ 1297 "LLST Response";
CM_ BO_ 1298 "LLST Response";
CM_ BO_ 1299 "LLST Response";
CM_ BO_ 1300 "LLST Response";
CM_ BO_ 1301 "LLST Response";
CM_ BO_ 1302 "LLST Response";
CM_ BO_ 1303 "LLST Response";
CM_ BO_ 1304 "LLST Response";
CM_ BO_ 1305 "LLST Response";
CM_ BO_ 1306 "LLST Response";
CM_ BO_ 1307 "Azimuth Corections from AASC";
CM_ BO_ 1308 "Azimuth Corections from AASC";
CM_ BO_ 1309 "Azimuth Corections from AASC";
CM_ BO_ 1310 "Azimuth Corections from AASC";
CM_ BO_ 1311 "Azimuth Corections from AASC";
CM_ BO_ 1536 "LLST Req MSG";

// Attribute definitions
BA_DEF_  "BaudRateCANFD" FLOAT 1000 10000000; // [bps]
BA_DEF_  "Baudrate" INT 1000 1000000; // [bps]
BA_DEF_  "BusType" STRING;
BA_DEF_  "DBName" STRING;
BA_DEF_  "ProtocolType" STRING;
BA_DEF_ BO_ "CANFD_BRS" ENUM "0","1";
BA_DEF_ BO_ "GenMsgCycleTime" INT 0 65536; // [ms]
BA_DEF_ BO_ "GenMsgDelayTime" INT 0 65536; // [ms]
BA_DEF_ BO_ "GenMsgSendType" ENUM "cyclic", "spontaneous", "not-used", "not-used", "not-used", "cyclicAndSpontaneous", "not-used", "cyclicIfActive", "NoMsgSendType"; // [us]
BA_DEF_ BO_ "VFrameFormat" ENUM "StandardCAN","ExtendedCAN","reserved","J1939PG","reserved","reserved","reserved","reserved","reserved","reserved","reserved","reserved","reserved","reserved","StandardCAN_FD","ExtendedCAN_FD";
BA_DEF_ SG_ "GenSigSendType" ENUM "Cyclic","OnWrite","OnWriteWithRepetition","OnChange","OnChangeWithRepetition","IfActive","IfActiveWithRepetition","NoSigSendType";
BA_DEF_ SG_ "SystemSignalLongSymbol" STRING ;
BA_DEF_ BO_ "GenMsgILSupport" ENUM "No","Yes";
BA_DEF_ BO_ "NmAsrMessage" ENUM "No","Yes";
BA_DEF_  "NmAsrBaseAddress" HEX 0 536870911;
BA_DEF_  "NmAsrMessageCount" INT 0 255;
BA_DEF_ BU_ "NodeLayerModules" STRING;
BA_DEF_ BU_ "ILused" ENUM "No","Yes";
BA_DEF_ SG_ "GenSigFuncType" ENUM "NoFun","n","n","n","n","n","n","n","n","n","n","n","n","n","n","CHK","CNT","n","n","n","CNT1","CRC1B","CRC1A","CRC1L","CRC1N","CNT4","CRC4A","CNT5","CRC5","n","n","n","n","CNT2","CRC2","CNT11","CRC11B","n","n","CRC11N";
BA_DEF_ SG_  "GenSigStartValue" FLOAT -1.79769313486232E+019 1.84467440737096E+019;

BA_DEF_DEF_ "BusType" "";
BA_DEF_DEF_ "DBName" "";
BA_DEF_DEF_ "ProtocolType" "";
BA_DEF_DEF_ "CANFD_BRS" "1";
BA_DEF_DEF_ "GenSigStartValue" 0;
BA_DEF_DEF_ "VFrameFormat" "J1939PG";
BA_DEF_DEF_ "GenSigSendType" "NoSigSendType";
BA_DEF_DEF_ "GenMsgCycleTime" 0;
BA_DEF_DEF_ "GenMsgDelayTime" 0;
BA_DEF_DEF_  "GenMsgSendType" "Spontaneous";
BA_DEF_DEF_ "GenMsgILSupport" "Yes";
BA_DEF_DEF_ "NmAsrMessage" "No";
BA_DEF_DEF_ "NmAsrBaseAddress" 1280;
BA_DEF_DEF_ "NmAsrMessageCount" 64;
BA_DEF_DEF_ "NodeLayerModules" "CANoeILNLVector.dll";
BA_DEF_DEF_ "ILused" "Yes";
BA_DEF_DEF_ "GenSigFuncType" "NoFun";
BA_DEF_DEF_  "SystemSignalLongSymbol" "";

BA_ "BaudRateCANFD" 2000000;
BA_ "Baudrate" 500000;
BA_ "BusType" "CAN FD";
BA_ "DBName" "ASDM1CANFD";
BA_ "ProtocolType" "CAN";
// Network
// ECU: ASDM
BA_ "ILused" BU_ ASDM 0;
// ECU: FLRB
BA_ "ILused" BU_ FLRB 0;
// Frame: AsdmToAllFuncAsdm1CanDiagReqFrame
BA_ "GenMsgDelayTime" BO_ 2047 5.000;
BA_ "GenMsgSendType" BO_ 2047 1;
BA_ "VFrameFormat" BO_ 2047 14;
// Frame: AsdmToFlrbAsdm1CanDiagReqFrame
BA_ "GenMsgDelayTime" BO_ 1889 5.000;
BA_ "GenMsgSendType" BO_ 1889 1;
BA_ "VFrameFormat" BO_ 1889 14;
// Frame: FlrbToAsdmAsdm1CanDiagResFrame
BA_ "GenMsgDelayTime" BO_ 1633 5.000;
BA_ "GenMsgSendType" BO_ 1633 1;
BA_ "VFrameFormat" BO_ 1633 14;

BA_ "GenMsgSendType" BO_ 289 0;
BA_ "GenMsgCycleTime" BO_ 289 20;
BA_ "VFrameFormat" BO_ 289 14;
BA_ "GenMsgSendType" BO_ 134 1;
BA_ "VFrameFormat" BO_ 134 14;
BA_ "GenMsgSendType" BO_ 789 0;
BA_ "GenMsgCycleTime" BO_ 789 1000;
BA_ "VFrameFormat" BO_ 789 14;
BA_ "GenMsgSendType" BO_ 770 0;
BA_ "GenMsgCycleTime" BO_ 770 50;
BA_ "VFrameFormat" BO_ 770 14;
BA_ "GenMsgSendType" BO_ 790 1;
BA_ "VFrameFormat" BO_ 790 14;
BA_ "GenMsgSendType" BO_ 416 1;
BA_ "VFrameFormat" BO_ 416 14;
BA_ "GenMsgSendType" BO_ 288 0;
BA_ "GenMsgCycleTime" BO_ 288 25;
BA_ "VFrameFormat" BO_ 288 14;
BA_ "GenMsgCycleTime" BO_ 1281 50;
BA_ "GenMsgSendType" BO_ 1281 0;
BA_ "VFrameFormat" BO_ 1281 14;
BA_ "GenMsgSendType" BO_ 1030 1;
BA_ "GenMsgILSupport" BO_ 1030 0;
BA_ "VFrameFormat" BO_ 1030 14;
BA_ "GenMsgSendType" BO_ 1031 1;
BA_ "GenMsgILSupport" BO_ 1031 0;
BA_ "VFrameFormat" BO_ 1031 14;
BA_ "GenMsgSendType" BO_ 3 1;
BA_ "VFrameFormat" BO_ 3 14;
BA_ "GenMsgSendType" BO_ 257 1;
BA_ "VFrameFormat" BO_ 257 14;
BA_ "GenMsgSendType" BO_ 304 1;
BA_ "VFrameFormat" BO_ 304 14;
BA_ "GenMsgSendType" BO_ 305 1;
BA_ "VFrameFormat" BO_ 305 14;
BA_ "GenMsgSendType" BO_ 306 1;
BA_ "VFrameFormat" BO_ 306 14;
BA_ "GenMsgSendType" BO_ 307 1;
BA_ "VFrameFormat" BO_ 307 14;
BA_ "GenMsgSendType" BO_ 308 1;
BA_ "VFrameFormat" BO_ 308 14;
BA_ "GenMsgSendType" BO_ 309 1;
BA_ "VFrameFormat" BO_ 309 14;
BA_ "GenMsgSendType" BO_ 310 1;
BA_ "VFrameFormat" BO_ 310 14;
BA_ "GenMsgSendType" BO_ 311 1;
BA_ "VFrameFormat" BO_ 311 14;
BA_ "GenMsgSendType" BO_ 312 1;
BA_ "VFrameFormat" BO_ 312 14;
BA_ "GenMsgSendType" BO_ 313 1;
BA_ "VFrameFormat" BO_ 313 14;
BA_ "GenMsgSendType" BO_ 314 1;
BA_ "VFrameFormat" BO_ 314 14;
BA_ "GenMsgSendType" BO_ 315 1;
BA_ "VFrameFormat" BO_ 315 14;
BA_ "GenMsgSendType" BO_ 316 1;
BA_ "VFrameFormat" BO_ 316 14;
BA_ "GenMsgSendType" BO_ 317 1;
BA_ "VFrameFormat" BO_ 317 14;
BA_ "GenMsgSendType" BO_ 318 1;
BA_ "VFrameFormat" BO_ 318 14;
BA_ "GenMsgSendType" BO_ 319 1;
BA_ "VFrameFormat" BO_ 319 14;
BA_ "GenMsgSendType" BO_ 320 1;
BA_ "VFrameFormat" BO_ 320 14;
BA_ "GenMsgSendType" BO_ 321 1;
BA_ "VFrameFormat" BO_ 321 14;
BA_ "GenMsgSendType" BO_ 322 1;
BA_ "VFrameFormat" BO_ 322 14;
BA_ "GenMsgSendType" BO_ 323 1;
BA_ "VFrameFormat" BO_ 323 14;
BA_ "GenMsgSendType" BO_ 324 1;
BA_ "VFrameFormat" BO_ 324 14;
BA_ "GenMsgSendType" BO_ 325 1;
BA_ "VFrameFormat" BO_ 325 14;
BA_ "GenMsgSendType" BO_ 326 1;
BA_ "VFrameFormat" BO_ 326 14;
BA_ "GenMsgSendType" BO_ 327 1;
BA_ "VFrameFormat" BO_ 327 14;
BA_ "GenMsgSendType" BO_ 328 1;
BA_ "VFrameFormat" BO_ 328 14;
BA_ "GenMsgSendType" BO_ 329 1;
BA_ "VFrameFormat" BO_ 329 14;
BA_ "GenMsgSendType" BO_ 330 1;
BA_ "VFrameFormat" BO_ 330 14;
BA_ "GenMsgSendType" BO_ 331 1;
BA_ "VFrameFormat" BO_ 331 14;
BA_ "GenMsgSendType" BO_ 332 1;
BA_ "VFrameFormat" BO_ 332 14;
BA_ "GenMsgSendType" BO_ 333 1;
BA_ "VFrameFormat" BO_ 333 14;
BA_ "GenMsgSendType" BO_ 334 1;
BA_ "VFrameFormat" BO_ 334 14;
BA_ "GenMsgSendType" BO_ 335 1;
BA_ "VFrameFormat" BO_ 335 14;
BA_ "GenMsgSendType" BO_ 336 1;
BA_ "VFrameFormat" BO_ 336 14;
BA_ "GenMsgSendType" BO_ 337 1;
BA_ "VFrameFormat" BO_ 337 14;
BA_ "GenMsgSendType" BO_ 338 1;
BA_ "VFrameFormat" BO_ 338 14;
BA_ "GenMsgSendType" BO_ 339 1;
BA_ "VFrameFormat" BO_ 339 14;
BA_ "GenMsgSendType" BO_ 340 1;
BA_ "VFrameFormat" BO_ 340 14;
BA_ "GenMsgSendType" BO_ 341 1;
BA_ "VFrameFormat" BO_ 341 14;
BA_ "GenMsgSendType" BO_ 342 1;
BA_ "VFrameFormat" BO_ 342 14;
BA_ "GenMsgSendType" BO_ 343 1;
BA_ "VFrameFormat" BO_ 343 14;
BA_ "GenMsgSendType" BO_ 344 1;
BA_ "VFrameFormat" BO_ 344 14;
BA_ "GenMsgSendType" BO_ 345 1;
BA_ "VFrameFormat" BO_ 345 14;
BA_ "GenMsgSendType" BO_ 346 1;
BA_ "VFrameFormat" BO_ 346 14;
BA_ "GenMsgSendType" BO_ 347 1;
BA_ "VFrameFormat" BO_ 347 14;
BA_ "GenMsgSendType" BO_ 348 1;
BA_ "VFrameFormat" BO_ 348 14;
BA_ "GenMsgSendType" BO_ 349 1;
BA_ "VFrameFormat" BO_ 349 14;
BA_ "GenMsgSendType" BO_ 350 1;
BA_ "VFrameFormat" BO_ 350 14;
BA_ "GenMsgSendType" BO_ 351 1;
BA_ "VFrameFormat" BO_ 351 14;
BA_ "GenMsgSendType" BO_ 352 1;
BA_ "VFrameFormat" BO_ 352 14;
BA_ "GenMsgSendType" BO_ 353 1;
BA_ "VFrameFormat" BO_ 353 14;
BA_ "GenMsgSendType" BO_ 354 1;
BA_ "VFrameFormat" BO_ 354 14;
BA_ "GenMsgSendType" BO_ 355 1;
BA_ "VFrameFormat" BO_ 355 14;
BA_ "GenMsgSendType" BO_ 356 1;
BA_ "VFrameFormat" BO_ 356 14;
BA_ "GenMsgSendType" BO_ 357 1;
BA_ "VFrameFormat" BO_ 357 14;
BA_ "GenMsgSendType" BO_ 358 1;
BA_ "VFrameFormat" BO_ 358 14;
BA_ "GenMsgSendType" BO_ 359 1;
BA_ "VFrameFormat" BO_ 359 14;
BA_ "GenMsgSendType" BO_ 769 0;
BA_ "GenMsgCycleTime" BO_ 769 25;
BA_ "VFrameFormat" BO_ 769 14;
BA_ "GenMsgSendType" BO_ 784 1;
BA_ "VFrameFormat" BO_ 784 14;
BA_ "GenMsgSendType" BO_ 785 0;
BA_ "GenMsgCycleTime" BO_ 785 50;
BA_ "VFrameFormat" BO_ 785 14;
BA_ "GenMsgSendType" BO_ 786 0;
BA_ "GenMsgCycleTime" BO_ 786 50;
BA_ "VFrameFormat" BO_ 786 14;
BA_ "GenMsgSendType" BO_ 787 0;
BA_ "GenMsgCycleTime" BO_ 787 50;
BA_ "VFrameFormat" BO_ 787 14;
BA_ "GenMsgSendType" BO_ 788 1;
BA_ "VFrameFormat" BO_ 788 14;
BA_ "GenMsgSendType" BO_ 1280 1;
BA_ "VFrameFormat" BO_ 1280 14;
BA_ "GenMsgSendType" BO_ 1290 1;
BA_ "VFrameFormat" BO_ 1290 14;
BA_ "GenMsgSendType" BO_ 1291 1;
BA_ "VFrameFormat" BO_ 1291 14;
BA_ "GenMsgSendType" BO_ 1292 1;
BA_ "VFrameFormat" BO_ 1292 14;
BA_ "GenMsgSendType" BO_ 1293 1;
BA_ "VFrameFormat" BO_ 1293 14;
BA_ "GenMsgSendType" BO_ 1294 1;
BA_ "VFrameFormat" BO_ 1294 14;
BA_ "GenMsgSendType" BO_ 1295 1;
BA_ "VFrameFormat" BO_ 1295 14;
BA_ "GenMsgSendType" BO_ 1296 1;
BA_ "VFrameFormat" BO_ 1296 14;
BA_ "GenMsgSendType" BO_ 1297 1;
BA_ "VFrameFormat" BO_ 1297 14;
BA_ "GenMsgSendType" BO_ 1298 1;
BA_ "VFrameFormat" BO_ 1298 14;
BA_ "GenMsgSendType" BO_ 1299 1;
BA_ "VFrameFormat" BO_ 1299 14;
BA_ "GenMsgSendType" BO_ 1300 1;
BA_ "VFrameFormat" BO_ 1300 14;
BA_ "GenMsgSendType" BO_ 1301 1;
BA_ "VFrameFormat" BO_ 1301 14;
BA_ "GenMsgSendType" BO_ 1302 1;
BA_ "VFrameFormat" BO_ 1302 14;
BA_ "GenMsgSendType" BO_ 1303 1;
BA_ "VFrameFormat" BO_ 1303 14;
BA_ "GenMsgSendType" BO_ 1304 1;
BA_ "VFrameFormat" BO_ 1304 14;
BA_ "GenMsgSendType" BO_ 1305 1;
BA_ "VFrameFormat" BO_ 1305 14;
BA_ "GenMsgSendType" BO_ 1306 1;
BA_ "VFrameFormat" BO_ 1306 14;
BA_ "GenMsgSendType" BO_ 1307 1;
BA_ "VFrameFormat" BO_ 1307 14;
BA_ "GenMsgSendType" BO_ 1308 1;
BA_ "VFrameFormat" BO_ 1308 14;
BA_ "GenMsgSendType" BO_ 1309 1;
BA_ "VFrameFormat" BO_ 1309 14;
BA_ "GenMsgSendType" BO_ 1310 1;
BA_ "VFrameFormat" BO_ 1310 14;
BA_ "GenMsgSendType" BO_ 1311 1;
BA_ "VFrameFormat" BO_ 1311 14;
BA_ "GenMsgSendType" BO_ 1536 1;
BA_ "VFrameFormat" BO_ 1536 14;

BA_ "SystemSignalLongSymbol" SG_ 770 Sensor_Error_Synchronization_Err "Sensor_Error_Synchronization_Error_MFR";
BA_ "SystemSignalLongSymbol" SG_ 770 Sensor_Error_Software_Incompatib "Sensor_Error_Software_Incompatible_MFR";
BA_ "SystemSignalLongSymbol" SG_ 770 Sensor_Error_Internal_Failure_MF "Sensor_Error_Internal_Failure_MFR";
BA_ "SystemSignalLongSymbol" SG_ 770 Sensor_Error_Calibration_Error_M "Sensor_Error_Calibration_Error_MFR";
BA_ "GenSigStartValue" SG_ 769 HostGear_ASDM 1;

VAL_ 257 ElevAlignment_Status_MFR 2 "MBASC_ELEV_MISALIGNED" 1 "MBASC_ELEV_ALIGNED" 0 "MBASC_ELEV_CALIBRATING" ;
VAL_ 288 CarModSts1 0 "CarModSts1_CarModNorm" 1 "CarModSts1_CarModTrnsp" 2 "CarModSts1_CarModFcy" 3 "CarModSts1_CarModCrash" 4 "CarModSts1_CarModDyno" ;
VAL_ 3 Type_EXT_ASDM_MFR 16 "CANTSYN_SYNC_NOT_CRC_SECURED" 32 "CANTSYN_SYNC_CRC_SECURED" 24 "CANTSYN_FUP_NOT_CRC_SECURED" 40 "CANTSYN_FUP_CRC_SECURED" 48 "CANTSYN_OFS_NOT_CRC_SECURED" 64 "CANTSYN_OFS_CRC_SECURED" 56 "CANTSYN_OFNS_NOT_CRC_SECURED" 72 "CANTSYN_OFNS_CRC_SECURED" ;
VAL_ 257 UnambiguousVelMeas1_MFR 0 "TPRI_69us" 1 "TPRI_82.8us" 2 "TPRI_96.6us" ;
VAL_ 257 Radar_Sensor_type_MFR 0 "Gen1.1" 1 "Gen1.2" 2 "MB79_A6" 3 "MCR2" 4 "MFR1" 5 "MFR1_2" 6 "MCR1_2_E" 7 "MFR1_2_E" ;
VAL_ 257 Sensor_Position_ID_MFR 0 "FL" 1 "FR" 2 "RL" 3 "RR" 4 "MFR" 5 "Reserved" 6 "Reserved" 7 "Reserved" ;
VAL_ 257 interferenceDetected_MFR 0 "False" 1 "True" ;
VAL_ 257 Blockage_Status_MFR 0 "Unblocked" 1 "Blocked" 2 "Partial_Low" 3 "Partial_Medium" 4 "Partial_High" ;
VAL_ 257 Sensor_Operation_Mode_MFR 0 "Undefined" 1 "Startup" 2 "Normal_Run" 3 "Faulty" 5 "Shutdown" 7 "Testing" 15 "Transaction_Mode" ;
VAL_ 257 AutoAlignment_Status_MFR 0 "Reserved" 1 "Reserved" 2 "Reserved" 3 "Online Validation" 4 "Online DBAA (or Coarse Alignment)" 5 "Online ASC (or Fine Alignment)" 6 "Aligned" 7 "MisAligned" 14 "Manual" 15 "Inactive" ;
VAL_ 257 Testing_Mode_MFR 0 "No_Test_Mode_Active" 1 "END_OF_LINE_TEST" 2 "HILT" 3 "LLHT_beam_pattern" 4 "LLHT_video" 5 "LLHT_FFT2D" 6 "LLHT_FFT3D_CMPLX" 7 "EIRP" 8 "LLHT_FFT3D_SPEC" 9 "Z7_CORES_IDLE" 10 "OSM_MODE" 11 "EMC" ;
VAL_ 257 Detection_Data_Mode_MFR 1 "Parking mode data" 0 "Driving mode data" ;
VAL_ 257 Sensor_Topology_MFR 0 "Master" 1 "Slave" ;
VAL_ 257 AASC_Calibration_flag_MFR 1 "Calibration complete" 0 "Calibration Not complete" ;
VAL_ 257 selected_chirp_config_MFR 0 "64" 1 "128" 2 "256" 3 "512" 4 "1024" 5 "2048" ;
VAL_ 769 VehiclePower_Gear_ASDM 15 "Invalid" 8 "Start" 4 "Run" 3 "ON" 2 "ACC" 1 "OFF" 0 "Uknown" ;
VAL_ 769 HostTrailerAttached_ASDM 0 "not_connected" 1 "connected" ;
VAL_ 769 HostDrivingForward_ASDM 0 "False" 1 "True" ;
VAL_ 769 HostGear_ASDM 0 "Gear_P" 1 "Gear_1" 2 "Gear_2" 3 "Gear_3" 4 "Gear_4" 5 "Gear_5" 6 "Gear_6" 7 "Gear_7" 8 "Gear_R" 9 "Gear_N" 11 "Gear_8" 12 "Gear_9" 14 "Gear_not_defined" 15 "Error" ;
VAL_ 784 Function_ID_0_MFR 0 "Empty_FUNC_ID" 1 "ICCM_DSS_FUNC_HWA1D_RUN" 2 "ICCM_DSS_FUNC_HWA2D_CONFIG" 3 "ICCM_DSS_FUNC_HWA2D_RUN" 4 "ICCM_DSS_FUNC_C1SA_RUN" 5 "ICCM_DSS_FUNC_C1CG_RUN" 6 "ICCM_DSS_FUNC_NRLC" 7 "ICCM_DSS_FUNC_SPEC" 8 "ICCM_DSS_FUNC_CFAR" 9 "ICCM_DSS_FUNC_DETC" 10 "ICCM_DSS_FUNC_DOAE" 11 "ICCM_DSS_FUNC_FECL" 12 "ICCM_DSS_FUNC_HPRM" 13 "ICCM_DSS_FUNC_AASC" 14 "ICCM_DSS_FUNC_INFC" 15 "ICCM_DSS_FUNC_RVVP" 16 "ICCM_DSS_FUNC_PRPC" 17 "ICCM_DSS_FUNC_PRPC_HWA_CONFIG" 18 "ICCM_DSS_FUNC_PRPC_RECONFIG" 19 "ICCM_DSS_FUNC_PRPC_AASC_MSG" 20 "ICCM_DSS_FUNC_PRPC_LAST_MSG" 255 "STACK_USAGE" ;
VAL_ 784 Function_ID_1_MFR 0 "Empty_FUNC_ID" 1 "ICCM_DSS_FUNC_HWA1D_RUN" 2 "ICCM_DSS_FUNC_HWA2D_CONFIG" 3 "ICCM_DSS_FUNC_HWA2D_RUN" 4 "ICCM_DSS_FUNC_C1SA_RUN" 5 "ICCM_DSS_FUNC_C1CG_RUN" 6 "ICCM_DSS_FUNC_NRLC" 7 "ICCM_DSS_FUNC_SPEC" 8 "ICCM_DSS_FUNC_CFAR" 9 "ICCM_DSS_FUNC_DETC" 10 "ICCM_DSS_FUNC_DOAE" 11 "ICCM_DSS_FUNC_FECL" 12 "ICCM_DSS_FUNC_HPRM" 13 "ICCM_DSS_FUNC_AASC" 14 "ICCM_DSS_FUNC_INFC" 15 "ICCM_DSS_FUNC_RVVP" 16 "ICCM_DSS_FUNC_PRPC" 17 "ICCM_DSS_FUNC_PRPC_HWA_CONFIG" 18 "ICCM_DSS_FUNC_PRPC_RECONFIG" 19 "ICCM_DSS_FUNC_PRPC_AASC_MSG" 20 "ICCM_DSS_FUNC_PRPC_LAST_MSG" 255 "STACK_USAGE" ;
VAL_ 784 Function_ID_2_MFR 0 "Empty_FUNC_ID" 1 "ICCM_DSS_FUNC_HWA1D_RUN" 2 "ICCM_DSS_FUNC_HWA2D_CONFIG" 3 "ICCM_DSS_FUNC_HWA2D_RUN" 4 "ICCM_DSS_FUNC_C1SA_RUN" 5 "ICCM_DSS_FUNC_C1CG_RUN" 6 "ICCM_DSS_FUNC_NRLC" 7 "ICCM_DSS_FUNC_SPEC" 8 "ICCM_DSS_FUNC_CFAR" 9 "ICCM_DSS_FUNC_DETC" 10 "ICCM_DSS_FUNC_DOAE" 11 "ICCM_DSS_FUNC_FECL" 12 "ICCM_DSS_FUNC_HPRM" 13 "ICCM_DSS_FUNC_AASC" 14 "ICCM_DSS_FUNC_INFC" 15 "ICCM_DSS_FUNC_RVVP" 16 "ICCM_DSS_FUNC_PRPC" 17 "ICCM_DSS_FUNC_PRPC_HWA_CONFIG" 18 "ICCM_DSS_FUNC_PRPC_RECONFIG" 19 "ICCM_DSS_FUNC_PRPC_AASC_MSG" 20 "ICCM_DSS_FUNC_PRPC_LAST_MSG" 255 "STACK_USAGE" ;
VAL_ 784 Function_ID_3_MFR 0 "Empty_FUNC_ID" 1 "ICCM_DSS_FUNC_HWA1D_RUN" 2 "ICCM_DSS_FUNC_HWA2D_CONFIG" 3 "ICCM_DSS_FUNC_HWA2D_RUN" 4 "ICCM_DSS_FUNC_C1SA_RUN" 5 "ICCM_DSS_FUNC_C1CG_RUN" 6 "ICCM_DSS_FUNC_NRLC" 7 "ICCM_DSS_FUNC_SPEC" 8 "ICCM_DSS_FUNC_CFAR" 9 "ICCM_DSS_FUNC_DETC" 10 "ICCM_DSS_FUNC_DOAE" 11 "ICCM_DSS_FUNC_FECL" 12 "ICCM_DSS_FUNC_HPRM" 13 "ICCM_DSS_FUNC_AASC" 14 "ICCM_DSS_FUNC_INFC" 15 "ICCM_DSS_FUNC_RVVP" 16 "ICCM_DSS_FUNC_PRPC" 17 "ICCM_DSS_FUNC_PRPC_HWA_CONFIG" 18 "ICCM_DSS_FUNC_PRPC_RECONFIG" 19 "ICCM_DSS_FUNC_PRPC_AASC_MSG" 20 "ICCM_DSS_FUNC_PRPC_LAST_MSG" 255 "STACK_USAGE" ;
VAL_ 785 AutoAlignment_ErrorType_MFR 0 "OV - not enough detections (upon timeout)" 1 "OV - error too big" 2 "DBAA - estimated MAO too large" 3 "DBAA - too many bins empty" 4 "DBAA - repeatedly too many bins empty" 5 "ASC - too many bins empty" 6 "Unused" 7 "Unused" ;
VAL_ 785 AutoCalib_Status_MFR 0 "Calib Not Started" 1 "Calib InProgress" 2 "Calib Successful" 3 "Not Enough Detections" 4 "Calib Not Precise Enough" 5 "Misaligned to the Left" 6 "Misaligned to the Right" 7 "MisAligned Upward" 8 "MisAligned Downward" 9 "Unused" 15 "Unused" ;
VAL_ 787 MCU_Temp_Status_MFR 11 "OverThreshold" 10 "Normal" 14 "UnderThreshold" ;
VAL_ 1290 LLHT_Data_Header_Mode_ID_MFR 1 "Video Mode" 2 "FFT2D Mode" 3 "FFT3D CMPLX Mode" 4 "FFT3D SPEC Mode" 5 "Beam Pattern Mode" 6 "EIRP Mode" 7 "Eagle BB" 8 "Eagle Tx" ;
SIG_GROUP_ 1281 ECU_WAKE_UP_MFR 1 : ECU_Wake_UP_0_MFR ECU_Wake_UP_1_MFR ECU_Wake_UP_2_MFR ECU_Wake_UP_3_MFR ECU_Wake_UP_4_MFR ECU_Wake_UP_5_MFR ECU_Wake_UP_6_MFR ECU_Wake_UP_7_MFR;
SIG_GROUP_ 1030 XCP_MASTER_MFR 1 : XCP_Master_0_ASDM_MFR XCP_Master_1_ASDM_MFR XCP_Master_2_ASDM_MFR XCP_Master_3_ASDM_MFR XCP_Master_4_ASDM_MFR XCP_Master_5_ASDM_MFR XCP_Master_6_ASDM_MFR XCP_Master_7_ASDM_MFR;
SIG_GROUP_ 1031 XCP_SLAVE_MFR 1 : XCP_Slave_0_MFR XCP_Slave_1_MFR XCP_Slave_2_MFR XCP_Slave_3_MFR XCP_Slave_4_MFR XCP_Slave_5_MFR XCP_Slave_6_MFR XCP_Slave_7_MFR;
SIG_GROUP_ 785 AUTOALIGN_RESULT_MFR_SG_311 1 : AutoCalib_Status_MFR AutoAlignment_ErrorType_MFR;
